VERSION "HNNBNNNYNNNNNNNNNNNNNNNNNNNNNNNNNNNNNNNNNN/4/%%%/4/'%**4NNN///"

NS_ :

BS_:

BU_: Allrad_Haldex AreaView_MQB BAP_Tester Bremse_ABS_MK100 Bremse_ESP_EPB_EBC460Vi Bremse_ESP_EPB_MK100 Bremse_ESP_MK100 Daempfer Gateway_MQB Lenkhilfe_EPS PDC PDC_PLA

BO_ 795 ESP_24: 8 Bremse_ABS_MK100
 SG_ ESP_24_CRC : 0|8@1+ (1,0) [0|255] ""  Gateway_MQB,Lenkhilfe_EPS
 SG_ ESP_24_BZ : 8|4@1+ (1,0) [0|15] ""  Gateway_MQB,Lenkhilfe_EPS
 SG_ ESP_Lampe : 12|1@1+ (1.0,0.0) [0.0|1] ""  AreaView_MQB,Gateway_MQB,Lenkhilfe_EPS,PDC,PDC_PLA
 SG_ ABS_Lampe : 13|1@1+ (1.0,0.0) [0.0|1] ""  Gateway_MQB,Lenkhilfe_EPS
 SG_ BK_Lampe_02 : 14|2@1+ (1.0,0.0) [0.0|3] ""  Gateway_MQB
 SG_ TC_Lampe : 16|1@1+ (1.0,0.0) [0.0|1] ""  Gateway_MQB
 SG_ ESP_m_Raddrehz : 17|15@1+ (0.002,0) [0.000|65.278] "Unit_Hertz"  Gateway_MQB
 SG_ ESP_Textanzeigen_03 : 32|5@1+ (1.0,0.0) [0.0|31] ""  Gateway_MQB
 SG_ ESP_Meldungen : 37|3@1+ (1.0,0.0) [0.0|7] ""  Gateway_MQB
 SG_ ESP_Wegimp_VA : 40|11@1+ (1,0) [0|2047] ""  AreaView_MQB,Gateway_MQB
 SG_ ESP_Fehlerstatus_Wegimp : 51|1@1+ (1.0,0.0) [0.0|1] ""  AreaView_MQB,Gateway_MQB
 SG_ ESP_Wegimp_Ueberlauf : 52|1@1+ (1.0,0.0) [0.0|1] ""  AreaView_MQB,Gateway_MQB
 SG_ ESP_QBit_Wegimp_VA : 53|1@1+ (1.0,0.0) [0.0|1] ""  AreaView_MQB,Gateway_MQB
 SG_ ESP_HDC_FktLampe : 54|1@1+ (1.0,0.0) [0.0|1] ""  Gateway_MQB
 SG_ ESP_Off_Lampe : 55|1@1+ (1.0,0.0) [0.0|1] ""  Gateway_MQB,Lenkhilfe_EPS
 SG_ ESP_HDC_Regelgeschw : 56|7@1+ (0.32,0) [0.32|39.68] "Unit_KiloMeterPerHour"  Gateway_MQB
 SG_ ESP_BKV_Warnung : 63|1@1+ (1.0,0.0) [0.0|1] ""  Gateway_MQB

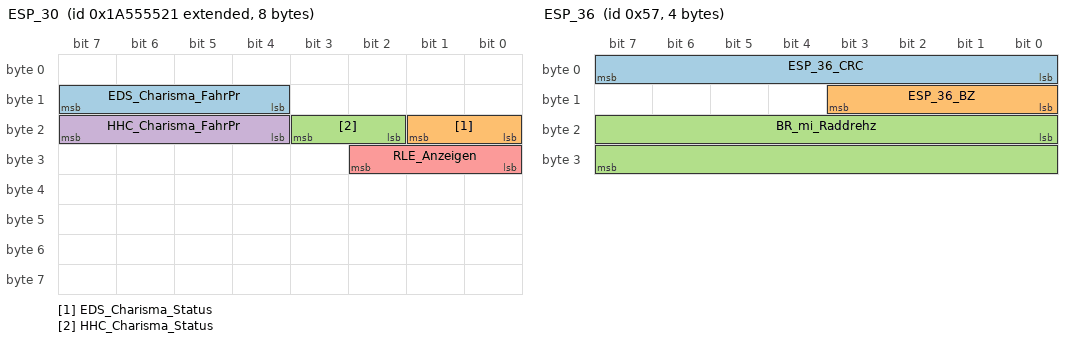
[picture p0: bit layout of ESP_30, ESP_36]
BO_ 2589283617 ESP_30: 8 Bremse_ESP_EPB_MK100
 SG_ EDS_Charisma_FahrPr : 12|4@1+ (1.0,0.0) [0.0|15] ""  Gateway_MQB
 SG_ EDS_Charisma_Status : 16|2@1+ (1.0,0.0) [0.0|3] ""  Gateway_MQB
 SG_ HHC_Charisma_Status : 18|2@1+ (1.0,0.0) [0.0|3] ""  Gateway_MQB
 SG_ HHC_Charisma_FahrPr : 20|4@1+ (1.0,0.0) [0.0|15] ""  Gateway_MQB
 SG_ RLE_Anzeigen : 24|3@1+ (1.0,0.0) [0.0|7] ""  Gateway_MQB

BO_ 427 ESP_33: 8 Bremse_ESP_EPB_EBC460Vi
 SG_ ESP_33_CRC : 0|8@1+ (1,0) [0|255] ""  Gateway_MQB,PDC
 SG_ ESP_33_BZ : 8|4@1+ (1,0) [0|15] ""  Gateway_MQB,PDC
 SG_ ESC_AHW_aktiv : 12|3@1+ (1.0,0.0) [0.0|7] ""  Gateway_MQB,PDC,PDC_PLA
 SG_ ESC_AHW_nicht_verfuegbar : 15|1@1+ (1.0,0.0) [0.0|1] ""  Gateway_MQB,PDC,PDC_PLA
 SG_ ESC_ANB_CM_aktiv : 16|2@1+ (1.0,0.0) [0.0|3] ""  Gateway_MQB
 SG_ ESC_ANB_CM_nicht_verfuegbar : 18|1@1+ (1.0,0.0) [0.0|1] ""  Gateway_MQB
 SG_ ESC_Warnruck_aktiv : 19|4@1+ (1.0,0.0) [0.0|15] ""  Gateway_MQB
 SG_ ESC_Warnruck_nicht_verfuegbar : 23|1@1+ (1.0,0.0) [0.0|1] ""  Gateway_MQB
 SG_ ESC_Prefill_aktiv : 24|1@1+ (1.0,0.0) [0.0|1] ""  Gateway_MQB
 SG_ ESC_Prefill_nicht_verfuegbar : 25|1@1+ (1.0,0.0) [0.0|1] ""  Gateway_MQB
 SG_ ESC_HBA_aktiv : 26|1@1+ (1.0,0.0) [0.0|1] ""  Gateway_MQB
 SG_ ESC_HBA_nicht_verfuegbar : 27|1@1+ (1.0,0.0) [0.0|1] ""  Gateway_MQB
 SG_ ESC_TSK_SRBM_Anf : 28|1@1+ (1.0,0.0) [0.0|1] ""  Gateway_MQB
 SG_ ESC_TSK_SRBM_nicht_verfuegbar : 29|1@1+ (1.0,0.0) [0.0|1] ""  Gateway_MQB
 SG_ ESC_Verz_Reg_aktiv : 30|4@1+ (1.0,0.0) [0.0|15] ""  Gateway_MQB,PDC,PDC_PLA
 SG_ ESC_Verz_Reg_nicht_verfuegbar : 34|1@1+ (1.0,0.0) [0.0|1] ""  Gateway_MQB,PDC,PDC_PLA
 SG_ ESC_Verz_Reg_TB_nicht_verfuegbar : 35|1@1+ (1.0,0.0) [0.0|1] ""  Gateway_MQB
 SG_ ESC_Verz_Reg_ZB_nicht_verfuegbar : 36|1@1+ (1.0,0.0) [0.0|1] ""  Gateway_MQB
 SG_ ESC_Bremslicht_unplausibel : 37|1@1+ (1.0,0.0) [0.0|1] ""  Gateway_MQB
 SG_ ESC_Konsistenz_ACC : 38|1@1+ (1.0,0.0) [0.0|1] ""  Gateway_MQB
 SG_ ESC_Konsistenz_AWV : 39|1@1+ (1.0,0.0) [0.0|1] ""  Gateway_MQB
 SG_ ESC_Konsistenz_ARA : 40|1@1+ (1.0,0.0) [0.0|1] ""  Gateway_MQB
 SG_ ESC_Konsistenz_IPA : 41|1@1+ (1.0,0.0) [0.0|1] ""  Gateway_MQB,PDC,PDC_PLA
 SG_ ESC_Konsistenz_FCW : 42|1@1+ (1.0,0.0) [0.0|1] ""  Gateway_MQB
 SG_ ESC_Konsistenz_NV : 43|1@1+ (1.0,0.0) [0.0|1] ""  Gateway_MQB
 SG_ ESC_Konsistenz_RCTA : 44|1@1+ (1.0,0.0) [0.0|1] ""  Gateway_MQB
 SG_ ESC_Konsistenz_TSK : 45|1@1+ (1.0,0.0) [0.0|1] ""  Gateway_MQB
 SG_ ESC_Konsistenz_vFGS : 46|1@1+ (1.0,0.0) [0.0|1] ""  Gateway_MQB
 SG_ ESC_Konsistenz_STA : 47|1@1+ (1.0,0.0) [0.0|1] ""  Gateway_MQB
 SG_ ESC_Fahrer_Bremsdruck_bestimmend : 48|1@1+ (1.0,0.0) [0.0|1] ""  Gateway_MQB,PDC,PDC_PLA
 SG_ ESC_Konsistenz_EA : 49|1@1+ (1.0,0.0) [0.0|1] ""  Gateway_MQB
 SG_ ESC_Konsistenz_BFF : 50|1@1+ (1.0,0.0) [0.0|1] ""  Gateway_MQB,PDC,PDC_PLA
 SG_ ESC_Konsistenz_MKB : 51|1@1+ (1.0,0.0) [0.0|1] ""  Gateway_MQB
 SG_ ESC_Verz_ASIL_Verfuegbarkeit : 52|3@1+ (1.0,0.0) [0.0|7] ""  Gateway_MQB,PDC,PDC_PLA
 SG_ ESC_Pumpenanlauf_aktiv : 55|1@1+ (1.0,0.0) [0.0|1] ""  Gateway_MQB
 SG_ ESC_Konsistenz_AGW : 56|1@1+ (1.0,0.0) [0.0|1] ""  Gateway_MQB
 SG_ ESC_Konsistenz_KAS : 57|1@1+ (1.0,0.0) [0.0|1] ""  Gateway_MQB
 SG_ ESC_Konsistenz_PCF : 58|1@1+ (1.0,0.0) [0.0|1] ""  Gateway_MQB
 SG_ ESC_Konsistenz_FAS_VK : 59|1@1+ (1.0,0.0) [0.0|1] ""  Gateway_MQB
 SG_ ESC_Verz_Begrenzung : 60|1@1+ (1.0,0.0) [0.0|1] ""  Gateway_MQB
 SG_ ESC_Konsistenz_AWA : 61|1@1+ (1.0,0.0) [0.0|1] ""  Gateway_MQB

BO_ 87 ESP_36: 4 Bremse_ESP_EPB_MK100
 SG_ ESP_36_CRC : 0|8@1+ (1,0) [0|255] ""  Gateway_MQB
 SG_ ESP_36_BZ : 8|4@1+ (1,0) [0|15] ""  Gateway_MQB
 SG_ BR_mi_Raddrehz : 16|16@1+ (0.0005,0) [0.0000|32.7660] "Unit_Hertz"  Gateway_MQB

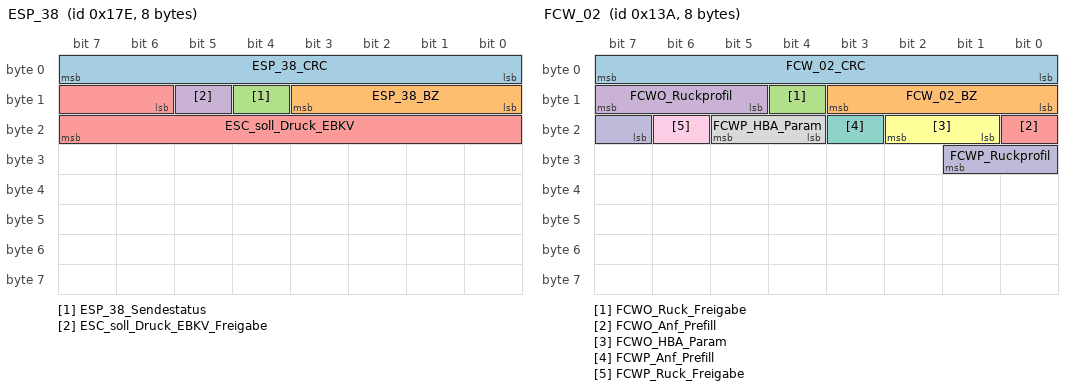
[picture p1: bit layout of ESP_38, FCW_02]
BO_ 382 ESP_38: 8 Bremse_ESP_EPB_MK100
 SG_ ESP_38_CRC : 0|8@1+ (1,0) [0|255] ""  Gateway_MQB
 SG_ ESP_38_BZ : 8|4@1+ (1,0) [0|15] ""  Gateway_MQB
 SG_ ESP_38_Sendestatus : 12|1@1+ (1.0,0.0) [0.0|1] ""  Gateway_MQB
 SG_ ESC_soll_Druck_EBKV_Freigabe : 13|1@1+ (1.0,0.0) [0.0|1] ""  Gateway_MQB
 SG_ ESC_soll_Druck_EBKV : 14|10@1+ (0.3,-30) [-30.0|276.6] "Unit_Bar"  Gateway_MQB

BO_ 264 Fahrwerk_01: 8 Daempfer
 SG_ Fahrwerk_01_CRC : 0|8@1+ (1,0) [0|255] ""  Bremse_ESP_EPB_EBC460Vi,Bremse_ESP_EPB_MK100,Bremse_ESP_MK100,Gateway_MQB
 SG_ Fahrwerk_01_BZ : 8|4@1+ (1,0) [0|15] ""  Bremse_ESP_EPB_EBC460Vi,Bremse_ESP_EPB_MK100,Bremse_ESP_MK100,Gateway_MQB
 SG_ FA_Hoehenwerte_kalibriert M  : 12|1@1+ (1.0,0.0) [0.0|1] ""  Gateway_MQB
 SG_ FA_ESP_Zuschaltung : 13|1@1+ (1.0,0.0) [0.0|1] ""  Bremse_ESP_EPB_EBC460Vi,Bremse_ESP_EPB_MK100,Bremse_ESP_MK100,Gateway_MQB
 SG_ FA_Hoehenwert_VL_00 m0  : 16|8@1+ (1,-127) [-127|126] "Unit_MilliMeter"  Gateway_MQB
 SG_ FA_Hoehenwert_VL_01 m1  : 16|8@1+ (0.4,0) [0.0|100.0] "Unit_PerCent"  Gateway_MQB
 SG_ FA_Hoehenwert_VR_00 m0  : 24|8@1+ (1,-127) [-127|126] "Unit_MilliMeter"  Gateway_MQB
 SG_ FA_Hoehenwert_VR_01 m1  : 24|8@1+ (0.4,0) [0.0|100.0] "Unit_PerCent"  Gateway_MQB
 SG_ FA_Hoehenwert_HL_00 m0  : 32|8@1+ (1,-127) [-127|126] "Unit_MilliMeter"  Gateway_MQB
 SG_ FA_Hoehenwert_HL_01 m1  : 32|8@1+ (0.4,0) [0.0|100.0] "Unit_PerCent"  Gateway_MQB
 SG_ FA_Hoehenwert_HR_00 m0  : 40|8@1+ (1,-127) [-127|126] "Unit_MilliMeter"  Gateway_MQB
 SG_ FA_Hoehenwert_HR_01 m1  : 40|8@1+ (0.4,0) [0.0|100.0] "Unit_PerCent"  Gateway_MQB

BO_ 314 FCW_02: 8 Gateway_MQB
 SG_ FCW_02_CRC : 0|8@1+ (1,0) [0|255] ""  Bremse_ESP_EPB_EBC460Vi,Bremse_ESP_EPB_MK100
 SG_ FCW_02_BZ : 8|4@1+ (1,0) [0|15] ""  Bremse_ESP_EPB_EBC460Vi,Bremse_ESP_EPB_MK100
 SG_ FCWO_Ruck_Freigabe : 12|1@1+ (1.0,0.0) [0.0|1] ""  Bremse_ESP_EPB_EBC460Vi,Bremse_ESP_EPB_MK100
 SG_ FCWO_Ruckprofil : 13|3@1+ (1.0,0.0) [0.0|7] ""  Bremse_ESP_EPB_EBC460Vi,Bremse_ESP_EPB_MK100
 SG_ FCWO_Anf_Prefill : 16|1@1+ (1.0,0.0) [0.0|1] ""  Bremse_ESP_EPB_EBC460Vi,Bremse_ESP_EPB_MK100
 SG_ FCWO_HBA_Param : 17|2@1+ (1.0,0.0) [0.0|3] ""  Bremse_ESP_EPB_EBC460Vi,Bremse_ESP_EPB_MK100
 SG_ FCWP_Anf_Prefill : 19|1@1+ (1.0,0.0) [0.0|1] ""  Bremse_ESP_EPB_EBC460Vi,Bremse_ESP_EPB_MK100
 SG_ FCWP_HBA_Param : 20|2@1+ (1.0,0.0) [0.0|3] ""  Bremse_ESP_EPB_EBC460Vi,Bremse_ESP_EPB_MK100
 SG_ FCWP_Ruck_Freigabe : 22|1@1+ (1.0,0.0) [0.0|1] ""  Bremse_ESP_EPB_EBC460Vi,Bremse_ESP_EPB_MK100
 SG_ FCWP_Ruckprofil : 23|3@1+ (1.0,0.0) [0.0|7] ""  Bremse_ESP_EPB_EBC460Vi,Bremse_ESP_EPB_MK100

BO_ 987 Gateway_72: 8 Gateway_MQB
 SG_ BCM_01_alt : 0|1@1+ (1.0,0.0) [0.0|1] ""  AreaView_MQB,Bremse_ABS_MK100,Bremse_ESP_EPB_EBC460Vi,Bremse_ESP_EPB_MK100,Bremse_ESP_MK100,PDC,PDC_PLA
 SG_ SMLS_01_alt : 1|1@1+ (1.0,0.0) [0.0|1] ""  AreaView_MQB,PDC,PDC_PLA
 SG_ ZV_02_alt : 2|1@1+ (1.0,0.0) [0.0|1] ""  AreaView_MQB,Bremse_ABS_MK100,Bremse_ESP_EPB_EBC460Vi,Bremse_ESP_EPB_MK100,Bremse_ESP_MK100,PDC,PDC_PLA
 SG_ Wischer_01_alt : 3|1@1+ (1.0,0.0) [0.0|1] ""  Bremse_ABS_MK100,Bremse_ESP_EPB_EBC460Vi,Bremse_ESP_EPB_MK100,Bremse_ESP_MK100
 SG_ Anhaenger_01_alt : 4|1@1+ (1.0,0.0) [0.0|1] ""  AreaView_MQB,Bremse_ESP_EPB_EBC460Vi,Bremse_ESP_EPB_MK100,Bremse_ESP_MK100,PDC,PDC_PLA
 SG_ Klima_Sensor_02_alt : 5|1@1+ (1.0,0.0) [0.0|1] ""  Lenkhilfe_EPS,PDC,PDC_PLA
 SG_ Verdeck_01_alt : 6|1@1+ (1.0,0.0) [0.0|1] ""  PDC,PDC_PLA
 SG_ Klima_11_alt : 7|1@1+ (1.0,0.0) [0.0|1] ""  Vector__XXX
 SG_ WFS_01_alt : 8|1@1+ (1.0,0.0) [0.0|1] ""  PDC,PDC_PLA
 SG_ Licht_Anf_01_alt : 9|1@1+ (1.0,0.0) [0.0|1] ""  AreaView_MQB,Lenkhilfe_EPS,PDC,PDC_PLA
 SG_ ZV_verriegelt_extern_soll : 10|1@1+ (1.0,0.0) [0.0|1] ""  Vector__XXX
 SG_ BH_Lichthupe : 11|1@1+ (1.0,0.0) [0.0|1] ""  Vector__XXX
 SG_ WFS_Klemmenfreigabe : 12|1@1+ (1.0,0.0) [0.0|1] ""  Vector__XXX
 SG_ ZV_Tankklappe_offen : 13|1@1+ (1.0,0.0) [0.0|1] ""  Vector__XXX
 SG_ AAG_Anhaenger_abgesteckt : 14|1@1+ (1.0,0.0) [0.0|1] ""  PDC,PDC_PLA
 SG_ BCM1_LDS_Stellung : 15|3@1+ (1.0,0.0) [0.0|7] ""  Vector__XXX
 SG_ VS_Verdeck_Anf : 18|1@1+ (1.0,0.0) [0.0|1] ""  PDC,PDC_PLA
 SG_ VS_VD_entriegelt : 19|1@1+ (1.0,0.0) [0.0|1] ""  PDC,PDC_PLA
 SG_ ZV_HFS_offen : 20|1@1+ (1.0,0.0) [0.0|1] ""  AreaView_MQB,PDC,PDC_PLA
 SG_ ZV_HBFS_offen : 21|1@1+ (1.0,0.0) [0.0|1] ""  AreaView_MQB,PDC,PDC_PLA
 SG_ VS_VD_offen_ver : 22|1@1+ (1.0,0.0) [0.0|1] ""  PDC,PDC_PLA
 SG_ VS_VD_zu_ver : 23|1@1+ (1.0,0.0) [0.0|1] ""  PDC,PDC_PLA
 SG_ ZV_BT_offen : 24|1@1+ (1.0,0.0) [0.0|1] ""  AreaView_MQB,PDC,PDC_PLA
 SG_ BCM1_Rueckfahrlicht_Schalter : 25|1@1+ (1.0,0.0) [0.0|1] ""  Bremse_ABS_MK100,Bremse_ESP_EPB_EBC460Vi,Bremse_ESP_EPB_MK100,Bremse_ESP_MK100,PDC,PDC_PLA
 SG_ ZV_FT_offen : 26|1@1+ (1.0,0.0) [0.0|1] ""  AreaView_MQB,Bremse_ABS_MK100,Bremse_ESP_EPB_EBC460Vi,Bremse_ESP_EPB_MK100,Bremse_ESP_MK100,PDC,PDC_PLA
 SG_ Wischer_vorne_aktiv : 27|1@1+ (1.0,0.0) [0.0|1] ""  Bremse_ABS_MK100,Bremse_ESP_EPB_EBC460Vi,Bremse_ESP_EPB_MK100,Bremse_ESP_MK100
 SG_ AAG_Anhaenger_erkannt : 28|1@1+ (1.0,0.0) [0.0|1] ""  AreaView_MQB,Bremse_ESP_EPB_EBC460Vi,Bremse_ESP_EPB_MK100,Bremse_ESP_MK100,PDC,PDC_PLA
 SG_ BCM1_MH_Schalter : 29|1@1+ (1.0,0.0) [0.0|1] ""  AreaView_MQB
 SG_ ZV_HD_offen : 30|1@1+ (1.0,0.0) [0.0|1] ""  AreaView_MQB,PDC,PDC_PLA
 SG_ Waschen_vorne_aktiv : 31|1@1+ (1.0,0.0) [0.0|1] ""  Vector__XXX
 SG_ KL_Thermomanagement : 32|2@1+ (1.0,0.0) [0.0|3] ""  Vector__XXX
 SG_ WFS_Schluessel_Fahrberecht : 34|4@1+ (1.0,0.0) [0.0|15] ""  PDC,PDC_PLA
 SG_ BCM_Rueckfahrlicht_Anf : 38|1@1+ (1.0,0.0) [0.0|1] ""  AreaView_MQB,Lenkhilfe_EPS,PDC,PDC_PLA
 SG_ WWSs_01_alt : 39|1@1+ (1.0,0.0) [0.0|1] ""  Bremse_ABS_MK100,Bremse_ESP_EPB_EBC460Vi,Bremse_ESP_EPB_MK100,Bremse_ESP_MK100
 SG_ BCM_Tankklappensteller_Fehler : 40|1@1+ (1.0,0.0) [0.0|1] ""  Vector__XXX
 SG_ AAG_LED_aktiv : 41|1@1+ (1.0,0.0) [0.0|1] ""  PDC,PDC_PLA
 SG_ ZV_verriegelt_soll : 42|2@1+ (1.0,0.0) [0.0|3] ""  Vector__XXX
 SG_ ZV_Schluessel_Zugang : 44|4@1+ (1.0,0.0) [0.0|15] ""  Vector__XXX
 SG_ WFS_ID_Geb_autorisiert_in_Kl15 : 48|1@1+ (1.0,0.0) [0.0|1] ""  Vector__XXX
 SG_ BH_Fernlicht : 49|1@1+ (1.0,0.0) [0.0|1] ""  Vector__XXX
 SG_ BH_Blinker_li : 50|1@1+ (1.0,0.0) [0.0|1] ""  AreaView_MQB,PDC,PDC_PLA
 SG_ BH_Blinker_re : 51|1@1+ (1.0,0.0) [0.0|1] ""  AreaView_MQB,PDC,PDC_PLA
 SG_ BCM1_OBD_FStatus_ATemp : 52|4@1+ (1.0,0.0) [0.0|15] ""  Lenkhilfe_EPS
 SG_ BCM1_Aussen_Temp_ungef : 56|8@1+ (0.5,-50) [-50.0|76.0] "Unit_DegreCelsi"  Lenkhilfe_EPS,PDC,PDC_PLA

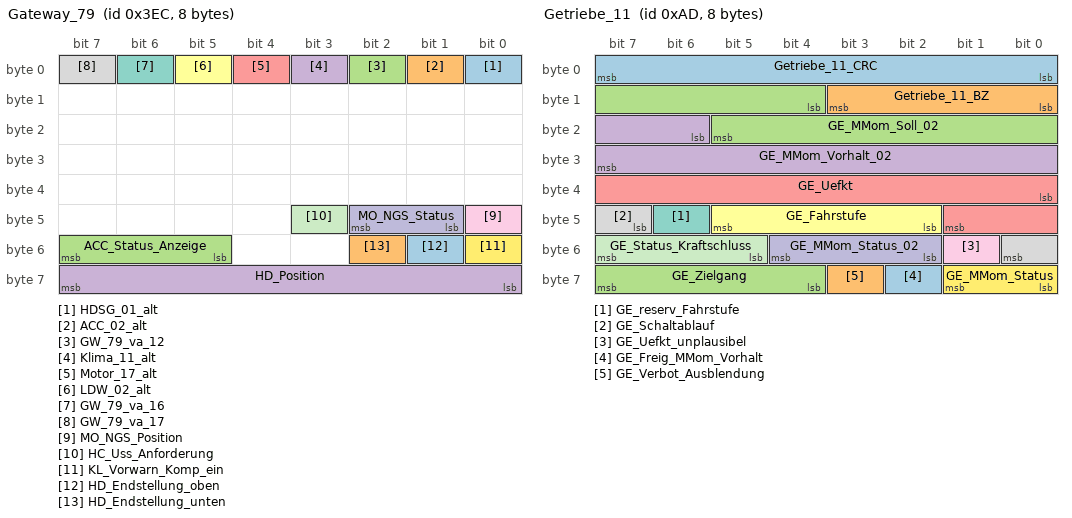
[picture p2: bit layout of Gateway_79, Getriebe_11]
BO_ 1004 Gateway_79: 8 Gateway_MQB
 SG_ HDSG_01_alt : 0|1@1+ (1.0,0.0) [0.0|1] ""  PDC,PDC_PLA
 SG_ ACC_02_alt : 1|1@1+ (1.0,0.0) [0.0|1] ""  PDC,PDC_PLA
 SG_ GW_79_va_12 : 2|1@1+ (1.0,0.0) [0.0|1] ""  Vector__XXX
 SG_ Klima_11_alt : 3|1@1+ (1.0,0.0) [0.0|1] ""  Bremse_ESP_EPB_EBC460Vi,Bremse_ESP_EPB_MK100
 SG_ Motor_17_alt : 4|1@1+ (1.0,0.0) [0.0|1] ""  Bremse_ESP_EPB_EBC460Vi,Bremse_ESP_EPB_MK100
 SG_ LDW_02_alt : 5|1@1+ (1.0,0.0) [0.0|1] ""  PDC_PLA
 SG_ GW_79_va_16 : 6|1@1+ (1.0,0.0) [0.0|1] ""  Vector__XXX
 SG_ GW_79_va_17 : 7|1@1+ (1.0,0.0) [0.0|1] ""  Vector__XXX
 SG_ MO_NGS_Position : 40|1@1+ (1.0,0.0) [0.0|1] ""  Bremse_ESP_EPB_EBC460Vi,Bremse_ESP_EPB_MK100
 SG_ MO_NGS_Status : 41|2@1+ (1.0,0.0) [0.0|3] ""  Bremse_ESP_EPB_EBC460Vi,Bremse_ESP_EPB_MK100
 SG_ HC_Uss_Anforderung : 43|1@1+ (1.0,0.0) [0.0|1] ""  PDC_PLA
 SG_ KL_Vorwarn_Komp_ein : 48|1@1+ (1.0,0.0) [0.0|1] ""  Bremse_ESP_EPB_EBC460Vi,Bremse_ESP_EPB_MK100
 SG_ HD_Endstellung_oben : 49|1@1+ (1.0,0.0) [0.0|1] ""  PDC,PDC_PLA
 SG_ HD_Endstellung_unten : 50|1@1+ (1.0,0.0) [0.0|1] ""  PDC,PDC_PLA
 SG_ ACC_Status_Anzeige : 53|3@1+ (1.0,0.0) [0.0|7] ""  PDC,PDC_PLA
 SG_ HD_Position : 56|8@1+ (1,0) [0|100] "Unit_PerCent"  PDC,PDC_PLA

BO_ 173 Getriebe_11: 8 Gateway_MQB
 SG_ Getriebe_11_CRC : 0|8@1+ (1,0) [0|255] ""  Bremse_ABS_MK100,Bremse_ESP_EPB_EBC460Vi,Bremse_ESP_EPB_MK100,Bremse_ESP_MK100
 SG_ Getriebe_11_BZ : 8|4@1+ (1,0) [0|15] ""  Bremse_ABS_MK100,Bremse_ESP_EPB_EBC460Vi,Bremse_ESP_EPB_MK100,Bremse_ESP_MK100
 SG_ GE_MMom_Soll_02 : 12|10@1+ (1,-509) [-509|509] ""  Vector__XXX
 SG_ GE_MMom_Vorhalt_02 : 22|10@1+ (1,-509) [-509|509] ""  Vector__XXX
 SG_ GE_Uefkt : 32|10@1+ (0.1,0) [0.0|102.2] ""  Bremse_ABS_MK100,Bremse_ESP_EPB_EBC460Vi,Bremse_ESP_EPB_MK100,Bremse_ESP_MK100
 SG_ GE_Fahrstufe : 42|4@1+ (1.0,0.0) [0.0|15] ""  AreaView_MQB,Bremse_ABS_MK100,Bremse_ESP_EPB_EBC460Vi,Bremse_ESP_EPB_MK100,Bremse_ESP_MK100,PDC,PDC_PLA
 SG_ GE_reserv_Fahrstufe : 46|1@1+ (1,0) [0|1] ""  Vector__XXX
 SG_ GE_Schaltablauf : 47|2@1+ (1.0,0.0) [0.0|3] ""  Bremse_ABS_MK100,Bremse_ESP_EPB_EBC460Vi,Bremse_ESP_EPB_MK100,Bremse_ESP_MK100
 SG_ GE_Uefkt_unplausibel : 49|1@1+ (1.0,0.0) [0.0|1] ""  Vector__XXX
 SG_ GE_MMom_Status_02 : 50|3@1+ (1.0,0.0) [0.0|7] ""  Vector__XXX
 SG_ GE_Status_Kraftschluss : 53|3@1+ (1.0,0.0) [0.0|7] ""  Vector__XXX
 SG_ GE_MMom_Status : 56|2@1+ (1.0,0.0) [0.0|3] ""  Vector__XXX
 SG_ GE_Freig_MMom_Vorhalt : 58|1@1+ (1.0,0.0) [0.0|1] ""  Vector__XXX
 SG_ GE_Verbot_Ausblendung : 59|1@1+ (1.0,0.0) [0.0|1] ""  Vector__XXX
 SG_ GE_Zielgang : 60|4@1+ (1.0,0.0) [0.0|15] ""  Allrad_Haldex,Bremse_ABS_MK100,Bremse_ESP_EPB_EBC460Vi,Bremse_ESP_EPB_MK100,Bremse_ESP_MK100

BO_ 968 Getriebe_14: 8 Gateway_MQB
 SG_ GE_OBD_AbsperrVent : 12|4@1+ (1.0,0.0) [0.0|15] ""  Vector__XXX
 SG_ GE_amax_moeglich : 16|9@1+ (0.024,-2.016) [-2.016|10.224] "Unit_MeterPerSeconSquar"  Vector__XXX
 SG_ GE_Charisma_FahrPr : 25|4@1+ (1.0,0.0) [0.0|15] ""  Vector__XXX
 SG_ GE_Charisma_Status : 29|2@1+ (1.0,0.0) [0.0|3] ""  Vector__XXX
 SG_ GE_Freigabe_Verfallsinfo_WFS : 31|1@1+ (1.0,0.0) [0.0|1] ""  Vector__XXX
 SG_ GE_Verlustmoment : 32|8@1+ (1,0) [0|254] ""  Bremse_ESP_EPB_EBC460Vi,Bremse_ESP_EPB_MK100
 SG_ Freilauf_Charisma_FahrPr : 40|4@1+ (1.0,0.0) [0.0|15] ""  Vector__XXX
 SG_ Freilauf_Charisma_Status : 44|2@1+ (1.0,0.0) [0.0|3] ""  Vector__XXX
 SG_ GE_Freigabe_Info_WFS : 46|1@1+ (1.0,0.0) [0.0|1] ""  Vector__XXX
 SG_ GE_Sperr_Info_WFS : 47|1@1+ (1.0,0.0) [0.0|1] ""  Vector__XXX
 SG_ GE_Zustand_Kuppltemp : 48|2@1+ (1.0,0.0) [0.0|3] ""  Vector__XXX
 SG_ GE_Codierung_MSG : 50|1@1+ (1.0,0.0) [0.0|1] ""  Vector__XXX
 SG_ GE_LaunchControl : 51|1@1+ (1.0,0.0) [0.0|1] ""  Bremse_ESP_EPB_EBC460Vi,Bremse_ESP_EPB_MK100,Bremse_ESP_MK100
 SG_ GE_Heizwunsch : 52|2@1+ (1.0,0.0) [0.0|3] ""  Vector__XXX
 SG_ GE_OBD_Status : 54|1@1+ (1.0,0.0) [0.0|1] ""  Vector__XXX
 SG_ GE_LFR_Adaption : 55|1@1+ (1.0,0.0) [0.0|1] ""  Vector__XXX
 SG_ GE_Sumpftemperatur : 56|8@1+ (1,-58) [-58|196] "Unit_DegreCelsi"  Vector__XXX

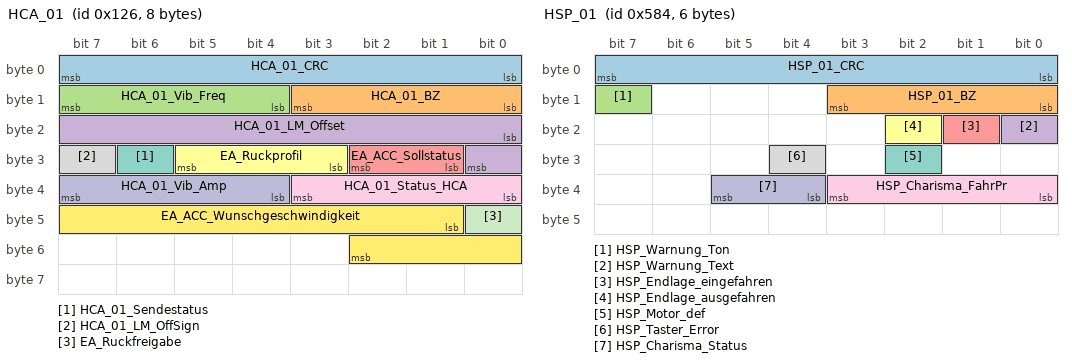
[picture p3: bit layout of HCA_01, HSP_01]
BO_ 294 HCA_01: 8 Gateway_MQB
 SG_ HCA_01_CRC : 0|8@1+ (1,0) [0|255] ""  Bremse_ESP_EPB_MK100,Bremse_ESP_MK100,Lenkhilfe_EPS
 SG_ HCA_01_BZ : 8|4@1+ (1,0) [0|15] ""  Bremse_ESP_EPB_MK100,Bremse_ESP_MK100,Lenkhilfe_EPS
 SG_ HCA_01_Vib_Freq : 12|4@1+ (1,15) [15|30] "Unit_Hertz"  Lenkhilfe_EPS
 SG_ HCA_01_LM_Offset : 16|9@1+ (0.01,0) [0.00|5.11] "Unit_NewtoMeter"  Lenkhilfe_EPS
 SG_ EA_ACC_Sollstatus : 25|2@1+ (1.0,0.0) [0.0|3] ""  Vector__XXX
 SG_ EA_Ruckprofil : 27|3@1+ (1.0,0.0) [0.0|7] ""  Bremse_ESP_EPB_MK100,Bremse_ESP_MK100
 SG_ HCA_01_Sendestatus : 30|1@1+ (1.0,0.0) [0.0|1] ""  Bremse_ESP_EPB_MK100,Bremse_ESP_MK100
 SG_ HCA_01_LM_OffSign : 31|1@1+ (1.0,0.0) [0.0|1] ""  Lenkhilfe_EPS
 SG_ HCA_01_Status_HCA : 32|4@1+ (1.0,0.0) [0.0|15] ""  Lenkhilfe_EPS
 SG_ HCA_01_Vib_Amp : 36|4@1+ (0.2,0) [0.0|3.0] "Unit_NewtoMeter"  Lenkhilfe_EPS
 SG_ EA_Ruckfreigabe : 40|1@1+ (1.0,0.0) [0.0|1] ""  Bremse_ESP_EPB_MK100,Bremse_ESP_MK100
 SG_ EA_ACC_Wunschgeschwindigkeit : 41|10@1+ (0.32,0) [0.00|327.04] "Unit_KiloMeterPerHour"  Vector__XXX

BO_ 1412 HSP_01: 6 Gateway_MQB
 SG_ HSP_01_CRC : 0|8@1+ (1,0) [0|255] ""  Vector__XXX
 SG_ HSP_01_BZ : 8|4@1+ (1,0) [0|15] ""  Vector__XXX
 SG_ HSP_Warnung_Ton : 15|1@1+ (1.0,0.0) [0.0|1] ""  Vector__XXX
 SG_ HSP_Warnung_Text : 16|1@1+ (1.0,0.0) [0.0|1] ""  Vector__XXX
 SG_ HSP_Endlage_eingefahren : 17|1@1+ (1.0,0.0) [0.0|1] ""  Vector__XXX
 SG_ HSP_Endlage_ausgefahren : 18|1@1+ (1.0,0.0) [0.0|1] ""  Vector__XXX
 SG_ HSP_Motor_def : 26|1@1+ (1.0,0.0) [0.0|1] ""  Vector__XXX
 SG_ HSP_Taster_Error : 28|1@1+ (1.0,0.0) [0.0|1] ""  Vector__XXX
 SG_ HSP_Charisma_FahrPr : 32|4@1+ (1.0,0.0) [0.0|15] ""  Vector__XXX
 SG_ HSP_Charisma_Status : 36|2@1+ (1.0,0.0) [0.0|3] ""  Vector__XXX

BO_ 1811 ISO_ABS_Req: 8 Gateway_MQB
 SG_ ISO_ABS_Req_Data : 0|64@1+ (1.0,0.0) [0.0|18446744073709551615] ""  Bremse_ABS_MK100,Bremse_ESP_EPB_EBC460Vi,Bremse_ESP_EPB_MK100,Bremse_ESP_MK100

BO_ 1917 ISO_ABS_Resp: 8 Bremse_ABS_MK100
 SG_ ISO_ABS_Resp_Data : 0|64@1+ (1.0,0.0) [0.0|18446744073709551615] ""  Gateway_MQB

BO_ 1807 ISO_Allrad_Req: 8 Gateway_MQB
 SG_ ISO_Allrad_Req_Data : 0|64@1+ (1.0,0.0) [0.0|18446744073709551615] ""  Allrad_Haldex

BO_ 1913 ISO_Allrad_Resp: 8 Allrad_Haldex
 SG_ ISO_Allrad_Resp_Data : 0|64@1+ (1.0,0.0) [0.0|18446744073709551615] ""  Gateway_MQB

BO_ 1906 ISO_Daempfer_Req: 8 Gateway_MQB
 SG_ ISO_Daempfer_Req_Data : 0|64@1+ (1.0,0.0) [0.0|18446744073709551615] ""  Daempfer

BO_ 2012 ISO_Daempfer_Resp: 8 Daempfer
 SG_ ISO_Daempfer_Resp_Data : 0|64@1+ (1.0,0.0) [0.0|18446744073709551615] ""  Gateway_MQB

BO_ 1802 ISO_EPH_Req: 8 Gateway_MQB
 SG_ ISO_EPH_Req_Data : 0|64@1+ (1.0,0.0) [0.0|18446744073709551615] ""  PDC,PDC_PLA

BO_ 1908 ISO_EPH_Resp: 8 PDC
 SG_ ISO_EPH_Resp_Data : 0|64@1+ (1.0,0.0) [0.0|18446744073709551615] ""  Gateway_MQB

BO_ 1793 ISO_Funktionaler_Req_01: 8 Gateway_MQB
 SG_ ISO_01_Req_Data : 0|64@1+ (1.0,0.0) [0.0|18446744073709551615] ""  Vector__XXX

BO_ 1794 ISO_Funktionaler_Req_02: 8 Gateway_MQB
 SG_ ISO_02_Req_Data : 0|64@1+ (1.0,0.0) [0.0|18446744073709551615] ""  Vector__XXX

BO_ 1796 ISO_Funktionaler_Req_04: 8 Gateway_MQB
 SG_ ISO_04_Req_Data : 0|64@1+ (1.0,0.0) [0.0|18446744073709551615] ""  Vector__XXX

BO_ 1797 ISO_Funktionaler_Req_05: 8 Gateway_MQB
 SG_ ISO_05_Req_Data : 0|64@1+ (1.0,0.0) [0.0|18446744073709551615] ""  Vector__XXX

BO_ 1798 ISO_Funktionaler_Req_06: 8 Gateway_MQB
 SG_ ISO_06_Req_Data : 0|64@1+ (1.0,0.0) [0.0|18446744073709551615] ""  Vector__XXX

BO_ 1799 ISO_Funktionaler_Req_07: 8 Gateway_MQB
 SG_ ISO_07_Req_Data : 0|64@1+ (1.0,0.0) [0.0|18446744073709551615] ""  Vector__XXX

BO_ 1800 ISO_Funktionaler_Req_08: 8 Gateway_MQB
 SG_ ISO_08_Req_Data : 0|64@1+ (1.0,0.0) [0.0|18446744073709551615] ""  Vector__XXX

BO_ 1801 ISO_Funktionaler_Req_09: 8 Gateway_MQB
 SG_ ISO_09_Req_Data : 0|64@1+ (1.0,0.0) [0.0|18446744073709551615] ""  Vector__XXX

BO_ 1795 ISO_Funktionaler_Req_Abgas: 8 Gateway_MQB
 SG_ ISO_Funktionaler_Req_Abgas : 0|64@1+ (1.0,0.0) [0.0|18446744073709551615] ""  Bremse_ESP_EPB_MK100

BO_ 1792 ISO_Funktionaler_Req_All: 8 Gateway_MQB
 SG_ ISO_ALL_01_Req_Data : 0|64@1+ (1.0,0.0) [0.0|18446744073709551615] ""  Allrad_Haldex,AreaView_MQB,Bremse_ABS_MK100,Bremse_ESP_EPB_EBC460Vi,Bremse_ESP_EPB_MK100,Bremse_ESP_MK100,Daempfer,Lenkhilfe_EPS,PDC,PDC_PLA

BO_ 2015 ISO_Funktionaler_Req_OBD: 8 Gateway_MQB
 SG_ ISO_OBD_Funktionaler_Req_Data : 0|64@1+ (1.0,0.0) [0.0|18446744073709551615] ""  Bremse_ESP_EPB_MK100

BO_ 1810 ISO_Lenkhilfe_Req: 8 Gateway_MQB
 SG_ ISO_Lenkhilfe_Req_Data : 0|64@1+ (1.0,0.0) [0.0|18446744073709551615] ""  Lenkhilfe_EPS

BO_ 1916 ISO_Lenkhilfe_Resp: 8 Lenkhilfe_EPS
 SG_ ISO_Lenkhilfe_Resp_Data : 0|64@1+ (1.0,0.0) [0.0|18446744073709551615] ""  Gateway_MQB

BO_ 2020 ISO_OBD_03_Req: 8 Gateway_MQB
 SG_ ISO_OBD_03_Req_Data : 0|64@1+ (1.0,0.0) [0.0|18446744073709551615] ""  Bremse_ESP_EPB_MK100

BO_ 2028 ISO_OBD_03_Resp: 8 Bremse_ESP_EPB_MK100
 SG_ ISO_OBD_03_Resp_Data : 0|64@1+ (1.0,0.0) [0.0|18446744073709551615] ""  Gateway_MQB

BO_ 1897 ISO_Rearview_Req: 8 Gateway_MQB
 SG_ ISO_Rearview_Req_Data : 0|64@1+ (1.0,0.0) [0.0|18446744073709551615] ""  AreaView_MQB

BO_ 2003 ISO_Rearview_Resp: 8 AreaView_MQB
 SG_ ISO_Rearview_Resp_Data : 0|64@1+ (1.0,0.0) [0.0|18446744073709551615] ""  Gateway_MQB

BO_ 960 Klemmen_Status_01: 4 Gateway_MQB
 SG_ Klemmen_Status_01_CRC : 0|8@1+ (1,0) [0|255] ""  Bremse_ESP_EPB_EBC460Vi,Bremse_ESP_EPB_MK100,Lenkhilfe_EPS
 SG_ Klemmen_Status_01_BZ : 8|4@1+ (1,0) [0|15] ""  Bremse_ESP_EPB_EBC460Vi,Bremse_ESP_EPB_MK100,Lenkhilfe_EPS
 SG_ RSt_Fahrerhinweise : 12|4@1+ (1.0,0.0) [0.0|15] ""  Vector__XXX
 SG_ ZAS_Kl_S : 16|1@1+ (1.0,0.0) [0.0|1] ""  Bremse_ESP_EPB_EBC460Vi,Bremse_ESP_EPB_MK100,Lenkhilfe_EPS
 SG_ ZAS_Kl_15 : 17|1@1+ (1.0,0.0) [0.0|1] ""  AreaView_MQB,Bremse_ESP_EPB_EBC460Vi,Bremse_ESP_EPB_MK100,Lenkhilfe_EPS,PDC,PDC_PLA
 SG_ ZAS_Kl_X : 18|1@1+ (1.0,0.0) [0.0|1] ""  Vector__XXX
 SG_ ZAS_Kl_50_Startanforderung : 19|1@1+ (1.0,0.0) [0.0|1] ""  Vector__XXX
 SG_ BCM_Remotestart_Betrieb : 20|1@1+ (1.0,0.0) [0.0|1] ""  Vector__XXX
 SG_ ZAS_Kl_Infotainment : 21|1@1+ (1.0,0.0) [0.0|1] ""  Vector__XXX
 SG_ BCM_Remotestart_KL15_Anf : 22|1@1+ (1.0,0.0) [0.0|1] ""  Vector__XXX
 SG_ BCM_Remotestart_MO_Start : 23|1@1+ (1.0,0.0) [0.0|1] ""  Vector__XXX
 SG_ KST_Warn_P1_ZST_def : 24|1@1+ (1.0,0.0) [0.0|1] ""  Vector__XXX
 SG_ KST_Warn_P2_ZST_def : 25|1@1+ (1.0,0.0) [0.0|1] ""  Vector__XXX
 SG_ KST_Fahrerhinweis_1 : 26|1@1+ (1.0,0.0) [0.0|1] ""  Vector__XXX
 SG_ KST_Fahrerhinweis_2 : 27|1@1+ (1.0,0.0) [0.0|1] ""  Vector__XXX
 SG_ BCM_Ausparken_Betrieb : 28|1@1+ (1.0,0.0) [0.0|1] ""  Vector__XXX
 SG_ KST_Fahrerhinweis_4 : 29|1@1+ (1.0,0.0) [0.0|1] ""  Vector__XXX
 SG_ KST_Fahrerhinweis_5 : 30|1@1+ (1.0,0.0) [0.0|1] ""  Vector__XXX
 SG_ KST_Fahrerhinweis_6 : 31|1@1+ (1.0,0.0) [0.0|1] ""  Vector__XXX

BO_ 1640 Klima_12: 8 Gateway_MQB
 SG_ KL_LRH_Taster : 0|1@1+ (1.0,0.0) [0.0|1] ""  Vector__XXX
 SG_ KL_LRH_Stufe : 1|2@1+ (1.0,0.0) [0.0|3] ""  Vector__XXX
 SG_ HSH_Taster : 3|2@1+ (1.0,0.0) [0.0|3] ""  Vector__XXX
 SG_ FSH_Taster : 5|1@1+ (1.0,0.0) [0.0|1] ""  Vector__XXX
 SG_ KL_Zuheizer_Freigabe : 6|1@1+ (1.0,0.0) [0.0|1] ""  Vector__XXX
 SG_ KL_Beschlagsgefahr : 7|1@1+ (1.0,0.0) [0.0|1] ""  Vector__XXX
 SG_ KL_SIH_Soll_li : 8|3@1+ (1.0,0.0) [0.0|7] ""  Vector__XXX
 SG_ KL_SIH_Soll_re : 11|3@1+ (1.0,0.0) [0.0|7] ""  Vector__XXX
 SG_ KRH_Soll_li : 14|2@1+ (1.0,0.0) [0.0|3] ""  Vector__XXX
 SG_ KL_SIL_Soll_li : 16|3@1+ (1.0,0.0) [0.0|7] ""  Vector__XXX
 SG_ KL_SIL_Soll_re : 19|3@1+ (1.0,0.0) [0.0|7] ""  Vector__XXX
 SG_ KRH_Soll_re : 22|2@1+ (1.0,0.0) [0.0|3] ""  Vector__XXX
 SG_ KL_Geblspng_Soll : 24|8@1+ (0.05,1.45) [1.50|14.00] "Unit_Volt"  PDC,PDC_PLA
 SG_ KL_Geblspng_Fond_Soll : 32|8@1+ (0.05,1.45) [1.50|14.00] "Unit_Volt"  PDC,PDC_PLA
 SG_ KL_I_Geblaese : 40|8@1+ (0.25,0) [0.00|63.50] "Unit_Amper"  Vector__XXX
 SG_ KL_Kompressorstrom_soll : 48|10@1+ (1,0) [0|1021] ""  Vector__XXX
 SG_ KL_Umluftklappe_Status : 58|4@1+ (1.0,0.0) [0.0|15] ""  Vector__XXX
 SG_ KL_PTC_Verbauinfo : 62|2@1+ (1.0,0.0) [0.0|3] ""  Vector__XXX

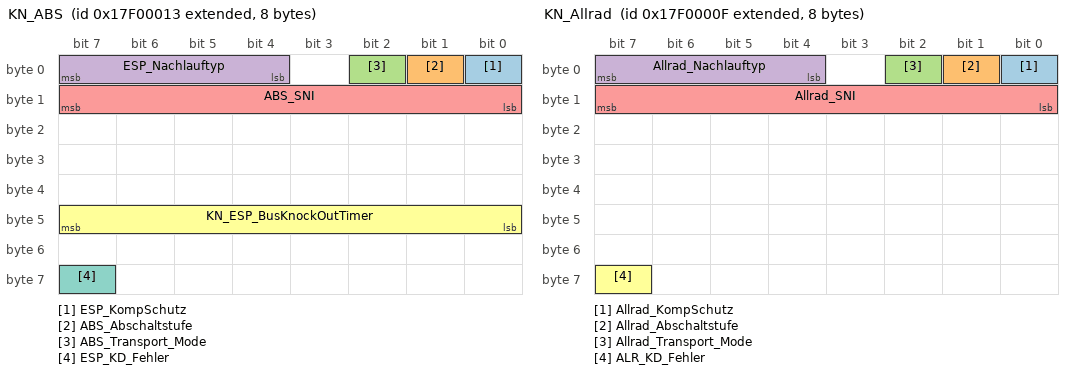
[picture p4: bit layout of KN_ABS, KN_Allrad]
BO_ 2549088275 KN_ABS: 8 Bremse_ABS_MK100
 SG_ ESP_KompSchutz : 0|1@1+ (1.0,0.0) [0.0|1] ""  Vector__XXX
 SG_ ABS_Abschaltstufe : 1|1@1+ (1.0,0.0) [0.0|1] ""  Vector__XXX
 SG_ ABS_Transport_Mode : 2|1@1+ (1.0,0.0) [0.0|1] ""  Vector__XXX
 SG_ ESP_Nachlauftyp : 4|4@1+ (1.0,0.0) [0.0|15] ""  Gateway_MQB
 SG_ ABS_SNI : 8|8@1+ (1.0,0.0) [0.0|255] ""  Vector__XXX
 SG_ KN_ESP_BusKnockOutTimer : 40|8@1+ (1,0) [0|254] ""  Vector__XXX
 SG_ ESP_KD_Fehler : 63|1@1+ (1.0,0.0) [0.0|1] ""  Gateway_MQB

BO_ 2549088271 KN_Allrad: 8 Allrad_Haldex
 SG_ Allrad_KompSchutz : 0|1@1+ (1.0,0.0) [0.0|1] ""  Vector__XXX
 SG_ Allrad_Abschaltstufe : 1|1@1+ (1.0,0.0) [0.0|1] ""  Vector__XXX
 SG_ Allrad_Transport_Mode : 2|1@1+ (1.0,0.0) [0.0|1] ""  Vector__XXX
 SG_ Allrad_Nachlauftyp : 4|4@1+ (1.0,0.0) [0.0|15] ""  Gateway_MQB
 SG_ Allrad_SNI : 8|8@1+ (1.0,0.0) [0.0|255] ""  Vector__XXX
 SG_ ALR_KD_Fehler : 63|1@1+ (1.0,0.0) [0.0|1] ""  Gateway_MQB

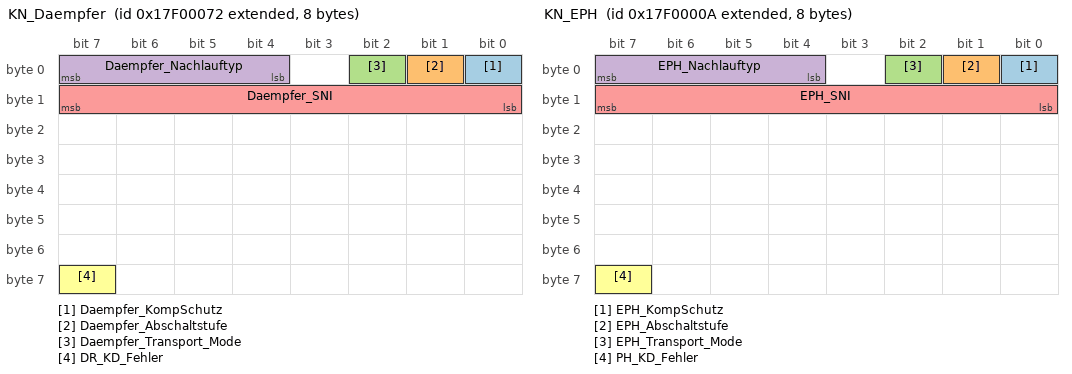
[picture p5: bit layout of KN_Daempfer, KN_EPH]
BO_ 2549088370 KN_Daempfer: 8 Daempfer
 SG_ Daempfer_KompSchutz : 0|1@1+ (1.0,0.0) [0.0|1] ""  Vector__XXX
 SG_ Daempfer_Abschaltstufe : 1|1@1+ (1.0,0.0) [0.0|1] ""  Vector__XXX
 SG_ Daempfer_Transport_Mode : 2|1@1+ (1.0,0.0) [0.0|1] ""  Vector__XXX
 SG_ Daempfer_Nachlauftyp : 4|4@1+ (1.0,0.0) [0.0|15] ""  Gateway_MQB
 SG_ Daempfer_SNI : 8|8@1+ (1.0,0.0) [0.0|255] ""  Vector__XXX
 SG_ DR_KD_Fehler : 63|1@1+ (1.0,0.0) [0.0|1] ""  Gateway_MQB

BO_ 2549088266 KN_EPH: 8 PDC
 SG_ EPH_KompSchutz : 0|1@1+ (1.0,0.0) [0.0|1] ""  Vector__XXX
 SG_ EPH_Abschaltstufe : 1|1@1+ (1.0,0.0) [0.0|1] ""  Vector__XXX
 SG_ EPH_Transport_Mode : 2|1@1+ (1.0,0.0) [0.0|1] ""  Vector__XXX
 SG_ EPH_Nachlauftyp : 4|4@1+ (1.0,0.0) [0.0|15] ""  Gateway_MQB
 SG_ EPH_SNI : 8|8@1+ (1.0,0.0) [0.0|255] ""  Vector__XXX
 SG_ PH_KD_Fehler : 63|1@1+ (1.0,0.0) [0.0|1] ""  Gateway_MQB

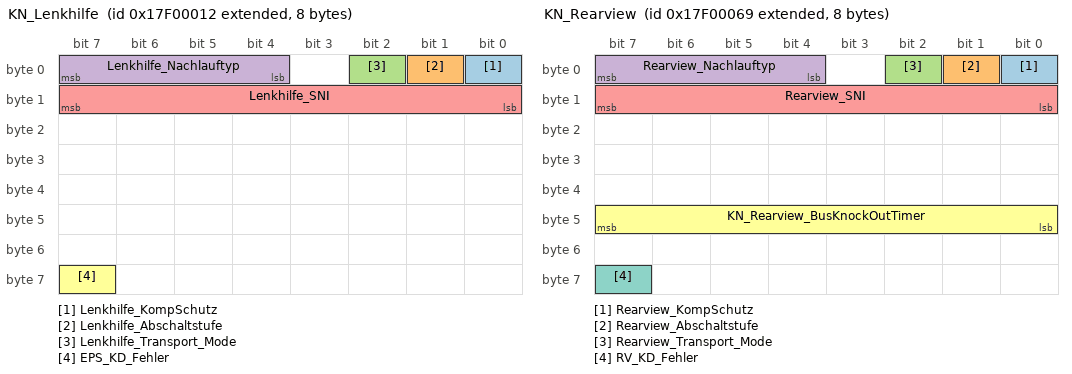
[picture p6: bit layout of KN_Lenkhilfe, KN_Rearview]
BO_ 2549088274 KN_Lenkhilfe: 8 Lenkhilfe_EPS
 SG_ Lenkhilfe_KompSchutz : 0|1@1+ (1.0,0.0) [0.0|1] ""  Vector__XXX
 SG_ Lenkhilfe_Abschaltstufe : 1|1@1+ (1.0,0.0) [0.0|1] ""  Vector__XXX
 SG_ Lenkhilfe_Transport_Mode : 2|1@1+ (1.0,0.0) [0.0|1] ""  Vector__XXX
 SG_ Lenkhilfe_Nachlauftyp : 4|4@1+ (1.0,0.0) [0.0|15] ""  Gateway_MQB
 SG_ Lenkhilfe_SNI : 8|8@1+ (1.0,0.0) [0.0|255] ""  Vector__XXX
 SG_ EPS_KD_Fehler : 63|1@1+ (1.0,0.0) [0.0|1] ""  Gateway_MQB

BO_ 2549088361 KN_Rearview: 8 AreaView_MQB
 SG_ Rearview_KompSchutz : 0|1@1+ (1.0,0.0) [0.0|1] ""  Vector__XXX
 SG_ Rearview_Abschaltstufe : 1|1@1+ (1.0,0.0) [0.0|1] ""  Vector__XXX
 SG_ Rearview_Transport_Mode : 2|1@1+ (1.0,0.0) [0.0|1] ""  Vector__XXX
 SG_ Rearview_Nachlauftyp : 4|4@1+ (1.0,0.0) [0.0|15] ""  Gateway_MQB
 SG_ Rearview_SNI : 8|8@1+ (1.0,0.0) [0.0|255] ""  Vector__XXX
 SG_ KN_Rearview_BusKnockOutTimer : 40|8@1+ (1,0) [0|254] ""  Vector__XXX
 SG_ RV_KD_Fehler : 63|1@1+ (1.0,0.0) [0.0|1] ""  Gateway_MQB

BO_TX_BU_ 795 :Bremse_ABS_MK100,Bremse_ESP_EPB_EBC460Vi,Bremse_ESP_EPB_MK100,Bremse_ESP_MK100;
BO_TX_BU_ 2589283617 :Bremse_ESP_EPB_MK100,Bremse_ESP_MK100;
BO_TX_BU_ 427 :Bremse_ESP_EPB_EBC460Vi,Bremse_ESP_EPB_MK100,Bremse_ESP_MK100;
BO_TX_BU_ 382 :Bremse_ESP_EPB_MK100,Bremse_ESP_MK100;
BO_TX_BU_ 1917 :Bremse_ABS_MK100,Bremse_ESP_EPB_EBC460Vi,Bremse_ESP_EPB_MK100,Bremse_ESP_MK100;
BO_TX_BU_ 1908 :PDC,PDC_PLA;
BO_TX_BU_ 2549088275 :Bremse_ABS_MK100,Bremse_ESP_EPB_EBC460Vi,Bremse_ESP_EPB_MK100,Bremse_ESP_MK100;
BO_TX_BU_ 2549088266 :PDC,PDC_PLA;
CM_ BO_ 795 "neu für MQB wg. Absicherung
Entstanden aus ESP_04";
CM_ BO_ 87 "Reserviert für Sondermaßnahme VW370/7";
CM_ BO_ 382 "reserviert für MQB (ESP->EBKV)";
CM_ BO_ 264 "ab MQB mit CRC-8";
CM_ BO_ 987 "Komfort -> Antrieb, Extended, Fahrwerk, Infotainment";
CM_ BO_ 1004 "Extended, Komfort  -> Fahrwerk";
CM_ BO_ 294 "für MQB verändertes Sendeverhalten
(nicht IL-kompatibel, da zwei Inaktiv-Werte im Signal HCA_01_Status_HCA)";
CM_ BO_ 960 "MQB";
CM_ BO_ 1640 "ab MQB IS-4";

CM_ SG_ 795 ABS_Lampe "Sicherheitswarnlampe

Weiterführende Informationen im Lastenheft spezifiziert und in der entsprechenden Fachabteilung zu erfragen.";
CM_ SG_ 795 BK_Lampe_02 "Sicherheitswarnlampe signalisiert EBV-Ausfall

MQB: wird auch bei HBV-Ausfall verwendet.

Weiterführende Informationen im Lastenheft spezifiziert und in der entsprechenden Fachabteilung zu erfragen.";
CM_ SG_ 795 ESP_24_CRC "Für MLB:
'Berechnung siehe Lastenheft 'Kommunikationsabsicherung für FlexRay und CAN''

Ab MQB und MLBevo:
'Berechnung siehe Lastenheft 'End-to-End Kommunikationsabsicherung''

Endwerte siehe Begleitdokument 'S-PDU Kennungsfolgen'";
CM_ SG_ 795 ESP_BKV_Warnung "ESP sendet im Hinweis- /Störungsfall an das Kombi Informationen zum Anzeigen (Text + Akustik)

Im MQB wird dieses Signal nicht unterstützt!
";
CM_ SG_ 795 ESP_Fehlerstatus_Wegimp "Weiterführende Informationen im Lastenheft spezifiziert und in der entsprechenden Fachabteilung zu erfragen.

MLB: Fehler wird gesetzt, wenn beide ESP-Drehzahlfühler an der Vorderachse defekt sind.

MQB: Fehler wird gesetzt, wenn beide Raddrehzahlfühl";
CM_ SG_ 795 ESP_HDC_FktLampe "Funktionslampe Bergabfahrassistent.
(Sender blinkt mit dem Bit 3,3Hz)";
CM_ SG_ 795 ESP_HDC_Regelgeschw "Verwendung/Bedienung nur im AU57x Allroad:
HDC-Geschwindigkeit
Dient der Anzeige der HDC-Geschwindigkeit und eines Bergabfahrsymbols im Kombi.
HDC-Standby wird gesetzt sobald der Fahrer den HDC-Taster aktiviert hat.
Bei HDC-Off oder während der Initia";
CM_ SG_ 795 ESP_Lampe "Zustand der Fahrdynamikregelungslampe (MLB: ASR und/oder ESP, MQB: nur ESP)

Weiterführende Informationen im Lastenheft spezifiziert und in der entsprechenden Fachabteilung zu erfragen.";
CM_ SG_ 795 ESP_m_Raddrehz "Radumdrehungen pro Sekunde sind Eingangsgröße für die Geschwindigkeitsberechnung im Kombi. Aus dieser Raddrehzahl und dem Radumfang wird die Fahrzeuggeschwindigkeit errechnet.

MLB: Exklusiver Empfänger ist das Kombiinstrument!
MQB: Bei Frontantrieb un";
CM_ SG_ 795 ESP_Meldungen "ESP sendet im Hinweis- /Störungsfall an das Kombi Informationen zum Anzeigen

Weiterführende Informationen im Lastenheft spezifiziert und in der entsprechenden Fachabteilung zu erfragen.
Ergänzender Hinweis:
1 = Autohold_Hinweis_1 (Anfahrassistent: nu";
CM_ SG_ 795 ESP_Off_Lampe "Bit zur Ansteuerung der separaten ESP-off-Lampe im Kombi (Gesetzesforderung USA)

MLB:
Verwendung/Bedienung ab D4";
CM_ SG_ 795 ESP_QBit_Wegimp_VA "Gesetzt bei Ersatzwert, Init oder Fehler.";
CM_ SG_ 795 ESP_Textanzeigen_03 "Textanzeigen der Fahrdynamikregelung im Kombiinstrument

Weiterführende Informationen im Lastenheft spezifiziert und in der entsprechenden Fachabteilung zu erfragen.

Der Signalwert 24 wird nur im BY736 verwendet.";
CM_ SG_ 795 ESP_Wegimp_Ueberlauf "Der Wegimpulszähler ist pro Zündungslauf mindestens einmal übergelaufen

Weiterführende Informationen im Lastenheft spezifiziert und in der entsprechenden Fachabteilung zu erfragen.";
CM_ SG_ 795 ESP_Wegimp_VA "Weiterführende Informationen im Lastenheft spezifiziert und in der entsprechenden Fachabteilung zu erfragen.

MLB: Die Wegimpulse Vorderachse sind die gemittelten Werte (reine mathematische Operation: Addition und Division durch zwei, keine Filterung) d";
CM_ SG_ 795 TC_Lampe "M-ABS Lampe (separate Lampe für M-ABS-Systeme Markt Brasilien)

Weiterführende Informationen im Lastenheft spezifiziert und in der entsprechenden Fachabteilung zu erfragen.";

CM_ SG_ 2589283617 EDS_Charisma_FahrPr "Aktuelles Fahrprogramm des Charisma-Teilnehmers Elektronische Differentialsperre EDS";
CM_ SG_ 2589283617 EDS_Charisma_Status "Systemstatus des Charismateilnehmers Elektronische Differentialsperre EDS";
CM_ SG_ 2589283617 HHC_Charisma_FahrPr "Aktuelles Fahrprogramm des Charisma-Teilnehmers Berganfahrassistent HHC";
CM_ SG_ 2589283617 HHC_Charisma_Status "Systemstatus des Charismateilnehmers Berganfahrassistent HHC";
CM_ SG_ 2589283617 RLE_Anzeigen "Anzeigen für die Radlöseerkennung";

CM_ SG_ 427 ESC_AHW_aktiv "Rueckmeldung Anhaltewegregelung aktiv
";
CM_ SG_ 427 ESC_AHW_nicht_verfuegbar "Rueckmeldung Anhaltewegregelung nicht verfuegbar
";
CM_ SG_ 427 ESC_ANB_CM_aktiv "Rueckmeldung ANB_CM (Autom_Notbremsung_Collision_Mitigation) aktiv
";
CM_ SG_ 427 ESC_ANB_CM_nicht_verfuegbar "Rueckmeldung ANB_CM nicht verfuegbar
";
CM_ SG_ 427 ESC_Bremslicht_unplausibel "Plausibilisierung der Rückmeldeinformation von BCM/AAG bezüglich Anforderung ESC_Bremslicht";
CM_ SG_ 427 ESC_Fahrer_Bremsdruck_bestimmend "Das Signal zeigt an, dass der Fahrer Bremsdruck bestimmend ist";
CM_ SG_ 427 ESC_HBA_aktiv "Rueckmeldung HBA (hydraulischer Bremsassistent) aktiv";
CM_ SG_ 427 ESC_HBA_nicht_verfuegbar "Rueckmeldung HBA (hydraulischer Bremsassistent) nicht verfuegbar";
CM_ SG_ 427 ESC_Konsistenz_ACC "Rueckmeldung Konsistenz der ACC Botschaften";
CM_ SG_ 427 ESC_Konsistenz_AGW "Rückmeldung Konsistenz der AGW-Botschaft an das ESC.";
CM_ SG_ 427 ESC_Konsistenz_ARA "Rueckmeldung Konsistenz der ARA Botschaften";
CM_ SG_ 427 ESC_Konsistenz_AWA "Rueckmeldung Konsistenz der AWA-Botschaften";
CM_ SG_ 427 ESC_Konsistenz_AWV "Rueckmeldung Konsistenz der AWV Botschaften";
CM_ SG_ 427 ESC_Konsistenz_BFF "Rückmeldung Konsistenz der Verzögerungsanforderung an das ESC-Steuergerät der Funktion 'Bremsen im freien Fahren' vom PDC_PLA_ARA-Steuergerät";
CM_ SG_ 427 ESC_Konsistenz_EA "Rueckmeldung Konsistenz der EA Botschaften (HCA)";
CM_ SG_ 427 ESC_Konsistenz_FAS_VK "Rueckmeldung Konsistenz der FAS_VK Botschaften";
CM_ SG_ 427 ESC_Konsistenz_FCW "Rueckmeldung Konsistenz der FCW Botschaften";
CM_ SG_ 427 ESC_Konsistenz_IPA "Rueckmeldung Konsistenz der IPA Botschaften";
CM_ SG_ 427 ESC_Konsistenz_KAS "Rückmeldung Konsistenz für Kreuzungsassistent-Anforderungen";
CM_ SG_ 427 ESC_Konsistenz_MKB "Rückmeldung Konsistenz für MKB-Verzögerungsanfoorderung";
CM_ SG_ 427 ESC_Konsistenz_NV "Rueckmeldung Konsistenz der NightVision Botschaften";
CM_ SG_ 427 ESC_Konsistenz_PCF "Rückmeldung der Konsistenz der PCF-Anforderungen";
CM_ SG_ 427 ESC_Konsistenz_RCTA "Rueckmeldung Konsistenz der RCTA (Rear Cross Traffic Alert) Botschaften";
CM_ SG_ 427 ESC_Konsistenz_STA "Rueckmeldung Konsistenz der STA Botschaften";
CM_ SG_ 427 ESC_Konsistenz_TSK "Rueckmeldung Konsistenz der TSK Botschaften";
CM_ SG_ 427 ESC_Konsistenz_vFGS "Rueckmeldung Konsistenz der vFGS Botschaften";
CM_ SG_ 427 ESC_Prefill_aktiv "Rueckmeldung Prefill aktiv";
CM_ SG_ 427 ESC_Prefill_nicht_verfuegbar "Rueckmeldung Prefill nicht verfuegbar";
CM_ SG_ 427 ESC_Pumpenanlauf_aktiv "Bestätigung der Durchführung eines Vorsteuerpumpenanlaufes";
CM_ SG_ 427 ESC_TSK_SRBM_Anf "Quittierung fuer TSK (SRBM=Summenradbremsmoment) Anforderung";
CM_ SG_ 427 ESC_TSK_SRBM_nicht_verfuegbar "Rueckmeldung TSK (SRBM= Summenradbremsmoment) nicht verfuegbar";
CM_ SG_ 427 ESC_Verz_ASIL_Verfuegbarkeit "Gibt die Verfuegbarkeit der VZM-Regelung an, wobei folgende Zustaende beruecksichtigt werden:
-Nicht Verfuegbarkeit wegen Sonderbetriebszustaenden (z.B. Produktionsmodus)
-ueber VZM abgebaute Fahrzeuggeschwindigkeit bei Verzögerungen a>5m/s², wobei gilt";
CM_ SG_ 427 ESC_Verz_Begrenzung "Rückmeldung angeforderte Verzögerung oder Summenradbremsmoment wird begrenzt umgesetzt  ";
CM_ SG_ 427 ESC_Verz_Reg_aktiv "Rueckmeldung Verzoegerungsregelung aktiv";
CM_ SG_ 427 ESC_Verz_Reg_nicht_verfuegbar "Rueckmeldung Verzoegerungsregelung nicht verfuegbar";
CM_ SG_ 427 ESC_Verz_Reg_TB_nicht_verfuegbar "Rueckmeldung Verzoegerungsregelung (Teilbremsung) nicht verfuegbar";
CM_ SG_ 427 ESC_Verz_Reg_ZB_nicht_verfuegbar "Rueckmeldung Verzoegerungsregelung ZB (Zielbremsung) nicht verfuegbar";
CM_ SG_ 427 ESC_Warnruck_aktiv "Rueckmeldung Warnruck aktiv";
CM_ SG_ 427 ESC_Warnruck_nicht_verfuegbar "Rueckmeldung Warnruck nicht verfuegbar";
CM_ SG_ 427 ESP_33_CRC "Für MLB:
'Berechnung siehe Lastenheft 'Kommunikationsabsicherung für FlexRay und CAN''

Ab MQB und MLBevo:
'Berechnung siehe Lastenheft 'End-to-End Kommunikationsabsicherung''

Endwerte siehe Begleitdokument 'S-PDU Kennungsfolgen'";

CM_ SG_ 87 BR_mi_Raddrehz "Mittelwert der Raddrehzahlen der angetriebenen Achse.
Bei Ausfall mind. eines Sensors wird 'Fehler' ausgegeben.
Bei Unterspannung an mind. einem Sensor wird 'Unterspannung' ausgegeben.
Im VW370/7 werden die Beträge der Raddrehzahlen VL und VR arithmeti";
CM_ SG_ 87 ESP_36_BZ "Botschaftszähler";
CM_ SG_ 87 ESP_36_CRC "Für MLB:
'Berechnung siehe Lastenheft 'Kommunikationsabsicherung für FlexRay und CAN''

Ab MQB und MLBevo:
'Berechnung siehe Lastenheft 'End-to-End Kommunikationsabsicherung''

Endwerte siehe Begleitdokument 'S-PDU Kennungsfolgen'";

CM_ SG_ 382 ESC_soll_Druck_EBKV "Stellgröße für den aufzubauenden Solldruck, den der eBKV aufbauen soll. Das Signal wird von allen ESC-Steuergeräten gesandt, die in Fahrzeugen mit eBKV verbaut werden.";
CM_ SG_ 382 ESC_soll_Druck_EBKV_Freigabe "Freigabebit für den zu stellenden Solldruck vom ESC an den eBKV";
CM_ SG_ 382 ESP_38_BZ "Botschaftszähler";
CM_ SG_ 382 ESP_38_CRC "Für MLB:
'Berechnung siehe Lastenheft 'Kommunikationsabsicherung für FlexRay und CAN''

Ab MQB und MLBevo:
'Berechnung siehe Lastenheft 'End-to-End Kommunikationsabsicherung''

Endwerte siehe Begleitdokument 'S-PDU Kennungsfolgen'";
CM_ SG_ 382 ESP_38_Sendestatus "Gibt den Sendestatus der Botschaft ESP_38 an (notwendig für IL-Unterstützung)";

CM_ SG_ 264 FA_ESP_Zuschaltung "Zwangsweise Aktivierung der ESP-Funktionalität wird angefordert auch bei Passivtastung";
CM_ SG_ 264 FA_Hoehenwert_HL_00 "Aktueller Höhenwert (kalibriert) Hinten Links; ungefiltertes Signal
Einheit, Offset und Faktor sind abhänig von 'FA_Hoehenwert_kalibriert'

Achtung:
Wird im AUDI B8 nicht bedient";
CM_ SG_ 264 FA_Hoehenwert_HL_01 "Aktueller Höhenwert (Rohwerte) Hinten Links; ungefiltertes Signal
Einheit, Offset und Faktor sind abhänig von 'FA_Hoehenwert_kalibriert'";
CM_ SG_ 264 FA_Hoehenwert_HR_00 "Aktueller Höhenwert (kalibriert) Hinten Rechts; ungefiltertes Signal
Einheit, Offset und Faktor sind abhänig von 'FA_Hoehenwert_kalibriert'

Achtung:
Wird im AUDI B8 nicht bedient";
CM_ SG_ 264 FA_Hoehenwert_HR_01 "Aktueller Höhenwert (Rohwerte) Hinten Rechts; ungefiltertes Signal
Einheit, Offset und Faktor sind abhänig von 'FA_Hoehenwert_kalibriert'";
CM_ SG_ 264 FA_Hoehenwert_VL_00 "Aktueller Höhenwert (kalibriert) Vorne Links; ungefiltertes Signal
Einheit, Offset und Faktor sind abhänig von 'FA_Hoehenwert_kalibriert'

Achtung:
Wird im AUDI B8 nicht bedient";
CM_ SG_ 264 FA_Hoehenwert_VL_01 "Aktueller Höhenwert (Rohwerte) Vorne Links; ungefiltertes Signal
Einheit, Offset und Faktor sind abhänig von 'FA_Hoehenwert_kalibriert'";
CM_ SG_ 264 FA_Hoehenwert_VR_00 "Aktueller Höhenwert (kalibriert) Vorne Rechts; ungefiltertes Signal
Einheit, Offset und Faktor sind abhänig von 'FA_Hoehenwert_kalibriert'

Achtung:
Wird im AUDI B8 nicht bedient";
CM_ SG_ 264 FA_Hoehenwert_VR_01 "Aktueller Höhenwert (Rohwerte) Vorne Rechts; ungefiltertes Signal
Einheit, Offset und Faktor sind abhänig von 'FA_Hoehenwert_kalibriert'";
CM_ SG_ 264 FA_Hoehenwerte_kalibriert "Legt fest, wie die Höhensensorwerte interpretiert werden müssen. Umschaltung kalibrierte Höhenwerte / Rohsignale in Byte 3-6

Achtung:
Im AUDI B8 Konstante: 0x1. D.h. es werden nur Rohwerte bedient!
Im AUDI D4 Konstante: 0x0. D.h. es werden nur Millim";
CM_ SG_ 264 Fahrwerk_01_CRC "Für MLB:
'Berechnung siehe Lastenheft 'Kommunikationsabsicherung für FlexRay und CAN''

Ab MQB und MLBevo:
'Berechnung siehe Lastenheft 'End-to-End Kommunikationsabsicherung''

Endwerte siehe Begleitdokument 'S-PDU Kennungsfolgen'";

CM_ SG_ 314 FCW_02_BZ "Botschaftszähler";
CM_ SG_ 314 FCW_02_CRC "Checksumme";
CM_ SG_ 314 FCWO_Anf_Prefill "Anforderung an ESP, dass die Prefill-Funktion aktiviert werden soll.";
CM_ SG_ 314 FCWO_HBA_Param "Anforderung an ESP, welcher HBA-Parametersatz verwendet werden soll.";
CM_ SG_ 314 FCWO_Ruck_Freigabe "Freigabit für die Warnruck-Anforderung an das ESP";
CM_ SG_ 314 FCWO_Ruckprofil "Anforderung an ESP, welcher Ruck aus einer Auswahl von max.
7 verschiedenen Ruckprofilen verwendet werden soll.
Eine Umsetzung der Ruckanforderung im ESP erfolgt nur mit gesetztem Bit 'FCWO_Ruck_ Freigabe'.";
CM_ SG_ 314 FCWP_Anf_Prefill "Anforderung an ESP, dass die Prefill-Funktion aktiviert werden soll.";
CM_ SG_ 314 FCWP_HBA_Param "Anforderung an ESP, welcher HBA-Parametersatz verwendet werden soll.";
CM_ SG_ 314 FCWP_Ruck_Freigabe "Freigabit für die Warnruck-Anforderung an das ESP";
CM_ SG_ 314 FCWP_Ruckprofil "Anforderung an ESP, welcher Ruck aus einer Auswahl von max. 7 verschiedenen Ruckprofilen verwendet werden soll. Eine Umsetzung der Ruckanforderung im ESP erfolgt nur mit gesetztem Bit 'FCWP_Ruck_ Freigabe'.";

CM_ SG_ 987 AAG_Anhaenger_abgesteckt "Anhaenger wurde bei Kl. 15 aus abgesteckt";
CM_ SG_ 987 AAG_Anhaenger_erkannt "Erkennung Anhaenger ";
CM_ SG_ 987 AAG_LED_aktiv "Dieses Signal sendet der Beleuchtungsart des Anhängers (LED oder Lampe)
Bei LED aktiv erfolgt kein Kaltüberwachung";
CM_ SG_ 987 BCM1_Aussen_Temp_ungef "ungefilterter Wert des Aussentemperatursensors
";
CM_ SG_ 987 BCM1_LDS_Stellung "Das Signal wird vom AFS / LWR Steuergerät empfangen und dient der Verifizierung der Lichtdrehschalterstellung. Intelligente Lichtfunktionen wie dyn. KL und gleitende Leuchtweite (GLW) nur bei LDS = 'AUTO'.";
CM_ SG_ 987 BCM1_MH_Schalter "Motorhaubenkontakt";
CM_ SG_ 987 BCM1_OBD_FStatus_ATemp "Fehlerstatus Umgebungstemperatursensor (OBD relevanter Sensor)
";
CM_ SG_ 987 BCM1_Rueckfahrlicht_Schalter "Rückfahrlichtschalter
ab MQB/ MLBevo: Die Ganginformation wird unentprellt übertragen, im AT-Getriebe wird evtl. kurzzeitig der R-Gang angezeigt. Eine Entprellung muß im Empfänger erfolgen (typisch 400ms).";
CM_ SG_ 987 BCM_Rueckfahrlicht_Anf "Anforderung Rückfahrlicht (Sollzustand). 
Das Signal wird entprellt (typisch 400ms) und bei KL15EIN gesendet. Das Signal ist unabhängig von der Position des Heckdeckels (kein Überhitzungsschutz).";
CM_ SG_ 987 BCM_Tankklappensteller_Fehler "Fehler: nicht Funktionalität des Tankklappenstellers";
CM_ SG_ 987 BH_Blinker_li "Blinkerhebel Richtung links
";
CM_ SG_ 987 BH_Blinker_re "Blinkerhebel Richtung rechts
";
CM_ SG_ 987 BH_Fernlicht "Betaetigung Fernlicht
";
CM_ SG_ 987 BH_Lichthupe "Betaetigung Lichthupe
";
CM_ SG_ 987 KL_Thermomanagement "Stufen des Thermomanagements;
Bei Klemme 15 AUS und erkannten Timeout zum Klimabedienteil (z.B. Klimabedienteil während des Motorsteuergeräte-Kommunikations-Nachlaufs bereits im NM-Zustand ¿Bus Sleep¿)
erfolgt keine Ansteuerung der Wasserpumpe durch die";
CM_ SG_ 987 VS_VD_entriegelt "

";
CM_ SG_ 987 VS_VD_offen_ver "

";
CM_ SG_ 987 VS_VD_zu_ver "
";
CM_ SG_ 987 VS_Verdeck_Anf "



";
CM_ SG_ 987 Waschen_vorne_aktiv "Status: Waschen vorne aktiv 
";
CM_ SG_ 987 WFS_ID_Geb_autorisiert_in_Kl15 "Authorisierung des Schlüssels im aktiven Klemme-15-Zyklus";
CM_ SG_ 987 WFS_Klemmenfreigabe "Freigabe von der WFS zum Einschalten der Klemme 15 und Klemme S";
CM_ SG_ 987 WFS_Schluessel_Fahrberecht "Schlüsselnummer Fahrberechtigung
0 = ungueltig, xxxx = Schluessel-Nr.";
CM_ SG_ 987 Wischer_vorne_aktiv "Status: Wischer vorne ";
CM_ SG_ 987 WWSs_01_alt "Veraltet Bit für die LIN-Botschaft WWSs_01.

Betroffene Signale:

Wischer_vorne_aktiv";
CM_ SG_ 987 ZV_BT_offen "gespiegeltes Bit BT_Tuer_geoeffnet TSG_BT_1 Botschaft";
CM_ SG_ 987 ZV_FT_offen "gespiegeltes Bit FT_Tuer_geoeffnet TSG_FT_1 Botschaft";
CM_ SG_ 987 ZV_HBFS_offen "gespiegeltes Bit HBFS_Tuer_geoeffnet TSG_HBFS_1 Botschaft";
CM_ SG_ 987 ZV_HD_offen "Status Heckdeckel
";
CM_ SG_ 987 ZV_HFS_offen "gespiegeltes Bit HFS_Tuer_geoeffnet TSG_HFS_1 Botschaft";
CM_ SG_ 987 ZV_Schluessel_Zugang "aktuelle Funkschlüsselnummer";
CM_ SG_ 987 ZV_Tankklappe_offen "Öffnungsstatus der Tankklappe";
CM_ SG_ 987 ZV_verriegelt_extern_soll "Sollzustand: Verriegelung Fahrzeug aussen
";
CM_ SG_ 987 ZV_verriegelt_soll "Fahrzeug Gesamtverriegelungsstatus Sollzustand für Ladestecker- und Ladeklappenverriegelung. ";

CM_ SG_ 1004 ACC_Status_Anzeige "Status nur zur Defintion von Anzeige im Kombi. Hinweis: Wird für die spez. VW-Anzeige (überlappende Anzeigebereiche) verwendet. Vom AUDI-ACC im Rahmen der Modulstrategie zu bedienen.";
CM_ SG_ 1004 HC_Uss_Anforderung "Ansteuerung der vorderen PLA (VLS, VRS) und APS Sensoren (VL, VR)
0 = Ultraschallsensoren Aus
1 = Ultraschallsensoren An";
CM_ SG_ 1004 HD_Endstellung_oben "obere Endstellung HD
";
CM_ SG_ 1004 HD_Endstellung_unten "untere Endstellung HD
";
CM_ SG_ 1004 HD_Position "HD Position von 0 bis 100 %";
CM_ SG_ 1004 KL_Vorwarn_Komp_ein "Vorwarnung Kompressor ein; 140ms vorher; Information für Motor zum Aufbau Momentenreserve";
CM_ SG_ 1004 MO_NGS_Position "Messwert des Neutralgangsensors
(nur Handschalter)";
CM_ SG_ 1004 MO_NGS_Status "Status des Signals MO_NGS_Position. Das MSG prüft die Plausibilität nur hinsichtlich sicher geöffnetem Triebstrang.";

CM_ SG_ 173 GE_Fahrstufe "Fahrprogramm des Getriebes

Hinweis: Zwischenstellung '0x0' darf nur für Zustandswechsel P/R, R/N, N/D ausgegeben werden, nicht für D/S oder D/Tippgasse wegen Abschaltkriterium GRA/ACC";
CM_ SG_ 173 GE_Freig_MMom_Vorhalt "Freigabe für die Anforderung einer Momentenreserve durch das Getriebe über das Signal
MLB: GE_MMom_Vorhalt
MQB/MLBevo: GE_MMom_Vorhalt_02";
CM_ SG_ 173 GE_MMom_Soll_02 "Momenteneingriff an den Motor.
Fordert vom MSG eine kurzfristige Reduzierung oder Anhebung des Moments.
Das Signal ist nur gültig in Kombination mit GE_MMom_Status (bei MQB) bzw. GE_MMom_Status_02 (bei MLBevo).

Achtung:
Einheitenloser Wert! Faktor i";
CM_ SG_ 173 GE_MMom_Status "Qualifiziert 
MLB: GE_MMom_Soll
MQB: GE_MMom_Soll_02";
CM_ SG_ 173 GE_MMom_Status_02 "Das Signal qualifiziert GE_MMom_Soll_02 und gibt an, wie GE_MMom_Soll_02 umgesetzt werden soll.
Werte:
0= kein Eingriff
1=   absoluter reduzierender Eingriff auf Gesamt Antrieb nur über schnellen Pfad 
2 = absoluter, erhöhender Eingriff auf Gesamt-Ant";
CM_ SG_ 173 GE_MMom_Vorhalt_02 "Anforderung einer Momentenreserve durch das Getriebe, gilt nur mit Freigabe durch 
GE_Freig_MMom_Vorhalt

Anforderung wird als Absolut-Wert umgesetzt, nicht als Relativ-Wert/Delta zum aktuellen Ist-Moment (d. h. eine Momentenreserve wird eingestellt, w";
CM_ SG_ 173 GE_reserv_Fahrstufe "reserviert, falls künftig Erweiterung von GE_Fahrstufe nötig";
CM_ SG_ 173 GE_Schaltablauf "Das Signal zeigt den aktuellen Status eines Schaltvorgangs.

Bei Signal = 0 liegt kein Schaltvorgang vor.
Bei Signal =2 liegt die Befüllphase der zuschaltenden Kupplung bzw. 
                      die Vorbereitungsphase dazu vor.

Mit den unterschie";
CM_ SG_ 173 GE_Status_Kraftschluss "Zeigt den Ist-Status des Kraftschlusses im Getriebe.
(Anmerkung: meist wird damit der Zustand des Anfahrelements beschrieben, d.h. bei DL/DQ die Kupplung;  bei AQ/AL der Wandler incl. Überbrückungskupplung)
0 = offen, kein Kraftschluss
1 = offen mit Kr";
CM_ SG_ 173 GE_Uefkt "Übertragungsfunktion des Getriebes
Drehzahlverhältnis = Eingangsdrehzahl / Ausgangsdrehzahl

AL: Wandlerverstärkung x Drehzahlverhältnis
VL: Drehzahlverhältnis
DL: Drehzahlverhältnis der aktiven und kraftschluß führenden Welle zum Abtrieb, bei Schalt";
CM_ SG_ 173 GE_Uefkt_unplausibel "Das Signal darf nur im Reku-Manager in Hybrid-Varianten verwendet werden.
Zeigt an, ob die Plausibilisierung Momenten-Verhältnis zu Drehzahl-Verhältnis i.O. ist.
Ein gesetztes Signal meldet eine unplausible GE_Uefkt bzw. GE_Uefkt_02.";
CM_ SG_ 173 GE_Verbot_Ausblendung "Verbot Einspritzausblendung für komfortable Schaltungen";
CM_ SG_ 173 GE_Zielgang "VL-Getriebe:
Signalisiert den Zielgang im manuellen Modus während eines Schaltvorgangs bzw. die momentane simulierte Gangstufe wenn kein Schaltvorgang aktiv ist. In den Fahrprogrammen 'D' und 'S' ist die Übersetzung variabel und somit wird dauerhaft 'Ist";
CM_ SG_ 173 Getriebe_11_BZ "Botschaftszähler
Botschaft asynchron geroutet. Zählerwert kann springen.";
CM_ SG_ 173 Getriebe_11_CRC "Für MLB:
'Berechnung siehe Lastenheft 'Kommunikationsabsicherung für FlexRay und CAN''

Ab MQB und MLBevo:
'Berechnung siehe Lastenheft 'End-to-End Kommunikationsabsicherung''

Endwerte siehe Begleitdokument 'S-PDU Kennungsfolgen'";

CM_ SG_ 968 Freilauf_Charisma_FahrPr "MLBevo: Aktuelles Fahrprogramm des Charisma-Teilnehmers (siehe Systemlastenheft Drive Select)
MQB: Istwert der Kennlinie (siehe Systemlastenheft MQB FPA)";
CM_ SG_ 968 Freilauf_Charisma_Status "Charisma Systemstatus des Charisma-Teilnehmers

Wert 0x3 ist nur für Fahrzeuge ab MQB relevant";
CM_ SG_ 968 GE_amax_moeglich "AL/DL: maximal mögliche Beschleunigung unter Berücksichtigung aller möglichen Gänge.

Eine Reduzierung des maximalen Motormoments durch Efficiency wird in dem Signal berücksichtigt.

VL: maximal mögliche Beschleunigung bei Nenndrehzahl (Efficency wird";
CM_ SG_ 968 GE_Charisma_FahrPr "MLBevo: Aktuelles Fahrprogramm des Charisma-Teilnehmers (siehe Systemlastenheft Drive Select)
MQB: Istwert der Kennlinie (siehe Systemlastenheft MQB FPA)";
CM_ SG_ 968 GE_Charisma_Status "Charisma Systemstatus des Charisma-Teilnehmers

Wert 0x3 ist nur für Fahrzeuge ab MQB relevant";
CM_ SG_ 968 GE_Codierung_MSG "Statusausgabe der Diagnose für Falschverbau. Plausibilisierung der empfangenen Motor- und Getriebevariante mit der erwarteten Motor- und Getriebevarianten.";
CM_ SG_ 968 GE_Freigabe_Info_WFS "WFS-Freigabeinformation";
CM_ SG_ 968 GE_Freigabe_Verfallsinfo_WFS "WFS";
CM_ SG_ 968 GE_LaunchControl "Während einer LaunchControl-Anfahrt sendet das Getriebesteuergerät das Bit LaunchControl aktiv.
Die Bremse wertet dieses Bit aus, um während einer solchen Anfahrt die Regelgrenzen der Schlupfregelung zu erweitern.
Im Motor Nutzung zur Verbesserung des A";
CM_ SG_ 968 GE_LFR_Adaption "Qualifiziert das ausgegeben Motorbelastungsmoment (durch GE_Vorsteuermoment) für die Verwendung zur LFR (Leerlauffüllungsregelung) im Moto";
CM_ SG_ 968 GE_OBD_AbsperrVent "Das Getriebesteuergerät führt eine elektrische Diagnose des von ihm angesteuerten Absperrventils für den Öl-Wasser-Wärmetauscher durch und übermittelt das Ergebnis an das MSG (Standard-4Bit-OBD-Status, nicht alle Zustände müssen genutzt werden; so sind z.";
CM_ SG_ 968 GE_OBD_Status "Dieses Bit steuert die MIL-Lampe an (Motorsteuergerät reicht diese Info an Kombi weiter).";
CM_ SG_ 968 GE_Sperr_Info_WFS "WFS-Sperrinformation";
CM_ SG_ 968 GE_Sumpftemperatur "Getriebesumpftemperatur wird über den Temperatursensor auf der Getriebeplatine ermittelt. Die absolute Sumpftemperatur wird vom Motor empfangen, um entsprechende Kühlleistung für das Getriebe einzustellen.";
CM_ SG_ 968 GE_Verlustmoment "Achtung einheitenloser Wert !!
	Faktor in MO_Faktor_Momente (MLB) bzw. MO_Faktor_Momente_02 (MQB/MLBevo) in Motor_Code_01 beachten!

ab MQB/MLBevo:
	Das Signal enthält die berechneten Momentenverluste, welche innerhalb des Getriebegehäuses entstehen (";
CM_ SG_ 968 GE_Zustand_Kuppltemp "Dieses Signal gibt den Temperaturzustand der Kupplung im DQ-Getriebe (z. Zt. DQ2x0, DQ500) an das ACC-System.";

CM_ SG_ 294 EA_ACC_Sollstatus "Status-Anforderung ACC von Emergency Alert. Statuswechsel bei Flanke. Solange Wert=1, wird EA_ACC_Wunschgeschwindigkeit übernommen. Wert=2 führt zu Zustand ¿ACC_GRA_passiv¿";
CM_ SG_ 294 EA_ACC_Wunschgeschwindigkeit "Emergency Alert Anforderung neue Wunschgeschwindigkeit";
CM_ SG_ 294 EA_Ruckfreigabe "Emergency Alert Freigabit für die Warnruck-Anforderung an das ESP";
CM_ SG_ 294 EA_Ruckprofil "Emergency Alert Anforderung an ESP, welcher Ruck verwendet werden soll. Eine Umsetzung der Ruckanforderung im ESP erfolgt nur mit gesetztem Bit 'EA_Ruckfreigabe'.";
CM_ SG_ 294 HCA_01_CRC "Für MLB:
'Berechnung siehe Lastenheft 'Kommunikationsabsicherung für Flexray und CAN''

Ab MQB und MLBevo:
'Berechnung siehe Lastenheft 'End-to-End Kommunikationsabsicherung'

Endwerte siehe Begleitdokument 'S-PDU Kennungsfolge'";
CM_ SG_ 294 HCA_01_LM_Offset "Von HCA angefordertes Lenkmoment (Betrag)";
CM_ SG_ 294 HCA_01_LM_OffSign "Vorzeichen des HCA-Lenkmoments";
CM_ SG_ 294 HCA_01_Sendestatus "Gibt den Sendestatus der HCA_01 an (notwendig für IL-Unterstützung)";
CM_ SG_ 294 HCA_01_Status_HCA "Statusinformation vom HCA und Manoevrierassistent für Handshakemechanismus mit der Lenkung";
CM_ SG_ 294 HCA_01_Vib_Amp "Momentenamplitude der Lenkradvibration";
CM_ SG_ 294 HCA_01_Vib_Freq "Frequenz der Lenkradvibration";

CM_ SG_ 1412 HSP_01_CRC "CRC8-Checksumme über alle Datenbytes der Botschaft HSPs_01

 Für MLB:
 'Berechnung siehe Lastenheft 'Kommunikationsabsicherung für Flexray und CAN''

 Ab MQB und MLBevo:
 'Berechnung siehe Lastenheft 'End-to-End Kommunikationsabsicherung'

 Endwer";
CM_ SG_ 1412 HSP_Charisma_FahrPr "MLBevo: Aktuelles Fahrprogramm des Charisma-Teilnehmers (siehe Systemlastenheft Drive Select)
MQB: Istwert der Kennlinie (siehe Systemlastenheft MQB FPA)";
CM_ SG_ 1412 HSP_Charisma_Status "Rückmeldung an den Charisma-Master

Wert 0x3 ist nur für Fahrzeuge ab MQB relevant";
CM_ SG_ 1412 HSP_Endlage_ausgefahren "Spoiler in Endlage ausgefahren";
CM_ SG_ 1412 HSP_Endlage_eingefahren "Spoiler in Endlage eingefahren";
CM_ SG_ 1412 HSP_Motor_def "elektr. Fehler im Spoilermotor";
CM_ SG_ 1412 HSP_Taster_Error "Spoiler meldet Tasterfehler";
CM_ SG_ 1412 HSP_Warnung_Text "Kombi Warnung Text Spoiler";
CM_ SG_ 1412 HSP_Warnung_Ton "Kombi Warnung Ton Spoiler";

CM_ SG_ 1811 ISO_ABS_Req_Data "Diagnose Request Bremsen-SG/Elektronisches Stabilitätsprogramm";

CM_ SG_ 1917 ISO_ABS_Resp_Data "Diagnose Response Bremsen-SG/Elektronisches Stabilitätsprogramm";

CM_ SG_ 1807 ISO_Allrad_Req_Data "Diagnose Request Allradsteuergeraet";

CM_ SG_ 1913 ISO_Allrad_Resp_Data "Diagnose Response Allradsteuergeraet";

CM_ SG_ 1906 ISO_Daempfer_Req_Data "Diagnose Request Daempfer-Steuergeraet";

CM_ SG_ 2012 ISO_Daempfer_Resp_Data "Diagnose Response Daempfer-Steuergeraet";

CM_ SG_ 1802 ISO_EPH_Req_Data "Diagnose Request Einparkhilfe";

CM_ SG_ 1908 ISO_EPH_Resp_Data "Diagnose Response Einparkhilfe";

CM_ SG_ 1795 ISO_Funktionaler_Req_Abgas "Funktionaler Request für abgasrelevante Steuergeraete";

CM_ SG_ 1792 ISO_ALL_01_Req_Data "Funktionaler Request ALL";

CM_ SG_ 2015 ISO_OBD_Funktionaler_Req_Data "Funktionaler Request für OBD relevante Steuergeraete";

CM_ SG_ 1810 ISO_Lenkhilfe_Req_Data "Diagnose Request Lenkhilfe (EPS)";

CM_ SG_ 1916 ISO_Lenkhilfe_Resp_Data "Diagnose Response Lenkhilfe (EPS)";

CM_ SG_ 2020 ISO_OBD_03_Req_Data "Diagnose Request 03 für OBD relevante Steuergeraete
MLBevo: ESC
MQB: ESC";

CM_ SG_ 2028 ISO_OBD_03_Resp_Data "Diagnose Response 03 für OBD relevante Steuergeraete
MLBevo: ESC
MQB: ESC";

CM_ SG_ 1897 ISO_Rearview_Req_Data "Diagnose Request Rearview/Areaview-Steuergerät";

CM_ SG_ 2003 ISO_Rearview_Resp_Data "Diagnose Response Rearview/Areaview-Steuergerät";

CM_ SG_ 960 BCM_Ausparken_Betrieb "Anforderung zur erneuten Lampenaufprüfung und Anzeige von Warnhinweisen nach einem pilotierten Ausparkvorgang (Trigger: fallende Flanke)";
CM_ SG_ 960 BCM_Remotestart_Betrieb "Zeigt den Status des RemoteStarts an, d.h. KL15_RSt ist aktiviert und der Motorlauf ist im RSt-Betrieb aktiv.";
CM_ SG_ 960 BCM_Remotestart_KL15_Anf "Zeigt den Status der Aktivierung der KL15_RST durch das BCM an.";
CM_ SG_ 960 BCM_Remotestart_MO_Start "Nachdem das BCM die Remotestart MSG Freigabe sicher erkannt hat, fordert das BCM wiederum über dieses Signal vom MSG einen Motorstart durchzuführen.";
CM_ SG_ 960 Klemmen_Status_01_BZ "4bit Botschaftszaehler; wird in jeder Sendebotschaft inkrementiert";
CM_ SG_ 960 Klemmen_Status_01_CRC "Für MLB:
'Berechnung siehe Lastenheft 'Kommunikationsabsicherung für FlexRay und CAN''

Ab MQB und MLBevo:
'Berechnung siehe Lastenheft 'End-to-End Kommunikationsabsicherung''

Endwerte siehe Begleitdokument 'S-PDU Kennungsfolgen'";
CM_ SG_ 960 KST_Fahrerhinweis_1 "Signalisierung Fahrerhinweis 1 der Klemmensteuerung an das Kombi";
CM_ SG_ 960 KST_Fahrerhinweis_2 "Signalisierung Fahrerhinweis 2 der Klemmensteuerung an das Kombi";
CM_ SG_ 960 KST_Fahrerhinweis_4 "Signalisierung Fahrerhinweis 4 der Klemmensteuerung an das Kombi";
CM_ SG_ 960 KST_Fahrerhinweis_5 "Anzeigesignal für RemoteStart";
CM_ SG_ 960 KST_Fahrerhinweis_6 "Signal aktiviert die Kombi-Anzeigeinstrumente (Drehzahl, Tankinhalt, Kühlmitteltemperatur) während aktiviertem RemoteStart-Betrieb";
CM_ SG_ 960 KST_Warn_P1_ZST_def "Kombi Prio Warnung Klemmensteuerung 
Zündschloß defekt, Service aufsuchen!";
CM_ SG_ 960 KST_Warn_P2_ZST_def "Kombi Prio Warnung Klemmensteuerung
Zündschloß defekt!
";
CM_ SG_ 960 RSt_Fahrerhinweise "Über das Signal fordert das BCM Fahrerhinweise im Kombi für die Funktion RemoteStart an.";
CM_ SG_ 960 ZAS_Kl_15 "Klemme 15: Zuendung (SW-Kl.15)
";
CM_ SG_ 960 ZAS_Kl_50_Startanforderung "Klemme 50: Startwunsch Fahrer
";
CM_ SG_ 960 ZAS_Kl_Infotainment "Separate Klemmeninformation für das Infotainment. Signal entspricht im wesentlichen einer Klemme S Information, kann aber über einen Vor - bzw. Nachlauf zu Klemme S verfügen. 
Ein konkreter Anwendungsfall für einen Nachlauf ist die Abschaltung der Klemme";
CM_ SG_ 960 ZAS_Kl_S "Klemme S: S-Kontakt (Schluessel steckt)
";
CM_ SG_ 960 ZAS_Kl_X "Klemme 75
";

CM_ SG_ 1640 FSH_Taster "Tasterbetätigung Frontscheibenheizung
";
CM_ SG_ 1640 HSH_Taster "An-/Abforderung Heckscheibenheizung über spezielles Tastersignal
";
CM_ SG_ 1640 KL_Beschlagsgefahr "Beschlagsgefahr auf der Frontscheibe im Bereich des Spiegelfusses. Dient zur präventiven Ansteuerung der  Kamera-Scheibenheizung, um Kamera-Blindheit zu vermeiden
PHEV: volle Leistungsfreigabe 
HV Heizer und HV EKK bei Scheibenbeschlag ";
CM_ SG_ 1640 KL_Geblspng_Fond_Soll "Ausgabe des Sollwertes für die Spannung des Klimagebläsemotores hinten.






";
CM_ SG_ 1640 KL_Geblspng_Soll "Ausgabe des Sollwertes für die Spannung des Klimagebläsemotores vorne.







";
CM_ SG_ 1640 KL_I_Geblaese "Stromaufnahme Gebläse";
CM_ SG_ 1640 KL_Kompressorstrom_soll "Sollvorgabe Klima-Kompressorstrom";
CM_ SG_ 1640 KL_LRH_Stufe "Eingestellte Temperaturstufe der Lenkradheizung";
CM_ SG_ 1640 KL_LRH_Taster "Tasterbetätigung Lenkradheizung";
CM_ SG_ 1640 KL_PTC_Verbauinfo "Im Klima- bzw. Heizungsbedienteil wird der Verbau eines PTCs und dessen elektr. Leistungsklasse codiert";
CM_ SG_ 1640 KL_SIH_Soll_li "Einstellung Sitzheizung Fahrer (0...6)";
CM_ SG_ 1640 KL_SIH_Soll_re "Einstellung Sitzheizung Beifahrer (0...6)";
CM_ SG_ 1640 KL_SIL_Soll_li "Einstellung Sitzlüftung Fahrer (0...6)";
CM_ SG_ 1640 KL_SIL_Soll_re "Einstellung Sitzlüftung Beifahrer (0...6)";
CM_ SG_ 1640 KL_Umluftklappe_Status "Status Umluftklappe";
CM_ SG_ 1640 KL_Zuheizer_Freigabe "Freigabe Zuheizer
";
CM_ SG_ 1640 KRH_Soll_li "Ausgabe des Sollwertes für die Kopfraumheizung links.";
CM_ SG_ 1640 KRH_Soll_re "Ausgabe des Sollwertes für die Kopfraumheizung rechts.";

CM_ SG_ 2549088275 ABS_Abschaltstufe "Funktionseinschränkung aufgrund aktiver Abschaltstufe";
CM_ SG_ 2549088275 ABS_SNI "Das Signal beinhaltet den Source Node Identifier (Knotenadresse, die auch in der Abbildungsvorschrift zur CAN-ID für die NM-High Botschaft verwendet wird).";
CM_ SG_ 2549088275 ABS_Transport_Mode "Funktionseinschränkung aufgrund aktivem Transport Mode und/oder Transport Schutz";
CM_ SG_ 2549088275 ESP_KompSchutz "Funktionseinschränkung aufgrund Komponentenschutz aktiv";
CM_ SG_ 2549088275 ESP_Nachlauftyp "Abgebildet wird die von der Hardware vorgegebene Möglichkeit, die Kommunikation nach Klemme 15 = AUS aufrecht zu erhalten. Es wird ein Init-Wert gesendet.
0 = Kommunikation nur bei KL15=EIN (kein Nachlauf, nicht weckfähig)
1 = Kommunikation nach KL15=AU";
CM_ SG_ 2549088275 KN_ESP_BusKnockOutTimer "Ausgabe des BusKnockOut-Timer in der Knotenbotschaft";

CM_ SG_ 2549088271 Allrad_Abschaltstufe "Funktionseinschränkung aufgrund aktiver Abschaltstufe";
CM_ SG_ 2549088271 Allrad_KompSchutz "Funktionseinschränkung aufgrund Komponentenschutz aktiv";
CM_ SG_ 2549088271 Allrad_Nachlauftyp "Abgebildet wird die von der Hardware vorgegebene Möglichkeit, die Kommunikation nach Klemme 15 = AUS aufrecht zu erhalten. Es wird ein Init-Wert gesendet.
0 = Kommunikation nur bei KL15=EIN (kein Nachlauf, nicht weckfähig)
1 = Kommunikation nach KL15=AU";
CM_ SG_ 2549088271 Allrad_SNI "Das Signal beinhaltet den Source Node Identifier (Knotenadresse, die auch in der Abbildungsvorschrift zur CAN-ID für die NM-High Botschaft verwendet wird).";
CM_ SG_ 2549088271 Allrad_Transport_Mode "Funktionseinschränkung aufgrund aktivem Transport Mode und/oder Transport Schutz";
CM_ SG_ 2549088271 ALR_KD_Fehler "Bei gesetztem Bit ist mindestens ein Kundendienstfehler eingetragen";

CM_ SG_ 2549088370 Daempfer_Abschaltstufe "Funktionseinschränkung aufgrund aktiver Abschaltstufe";
CM_ SG_ 2549088370 Daempfer_KompSchutz "Funktionseinschränkung aufgrund Komponentenschutz aktiv";
CM_ SG_ 2549088370 Daempfer_Nachlauftyp "Abgebildet wird die von der Hardware vorgegebene Möglichkeit, die Kommunikation nach Klemme 15 = AUS aufrecht zu erhalten. Es wird ein Init-Wert gesendet.
0 = Kommunikation nur bei KL15=EIN (kein Nachlauf, nicht weckfähig)
1 = Kommunikation nach KL15=AU";
CM_ SG_ 2549088370 Daempfer_SNI "Das Signal beinhaltet den Source Node Identifier (Knotenadresse, die auch in der Abbildungsvorschrift zur CAN-ID für die NM-High Botschaft verwendet wird).";
CM_ SG_ 2549088370 Daempfer_Transport_Mode "Funktionseinschränkung aufgrund aktivem Transport Mode und/oder Transport Schutz";

CM_ SG_ 2549088266 EPH_Abschaltstufe "Funktionseinschränkung aufgrund aktiver Abschaltstufe";
CM_ SG_ 2549088266 EPH_KompSchutz "Funktionseinschränkung aufgrund Komponentenschutz aktiv";
CM_ SG_ 2549088266 EPH_Nachlauftyp "Abgebildet wird die von der Hardware vorgegebene Möglichkeit, die Kommunikation nach Klemme 15 = AUS aufrecht zu erhalten. Es wird ein Init-Wert gesendet.
0 = Kommunikation nur bei KL15=EIN (kein Nachlauf, nicht weckfähig)
1 = Kommunikation nach KL15=AU";
CM_ SG_ 2549088266 EPH_SNI "Das Signal beinhaltet den Source Node Identifier (Knotenadresse, die auch in der Abbildungsvorschrift zur CAN-ID für die NM-High Botschaft verwendet wird).";
CM_ SG_ 2549088266 EPH_Transport_Mode "Funktionseinschränkung aufgrund aktivem Transport Mode und/oder Transport Schutz";
CM_ SG_ 2549088266 PH_KD_Fehler "Meldung, ob mindestens ein Fehler mit Priorität 1....6 im Fehlerspeicher eingetragen ist (aktiv oder passiv), gilt nicht für Fehler im Entwicklungsfehlerspeicher. Bit wird erst mit Löschen des Fehlerspeichers zurückgenommen.";

CM_ SG_ 2549088274 Lenkhilfe_Abschaltstufe "Funktionseinschränkung aufgrund aktiver Abschaltstufe";
CM_ SG_ 2549088274 Lenkhilfe_KompSchutz "Funktionseinschränkung aufgrund Komponentenschutz aktiv";
CM_ SG_ 2549088274 Lenkhilfe_Nachlauftyp "Abgebildet wird die von der Hardware vorgegebene Möglichkeit, die Kommunikation nach Klemme 15 = AUS aufrecht zu erhalten. Es wird ein Init-Wert gesendet.
0 = Kommunikation nur bei KL15=EIN (kein Nachlauf, nicht weckfähig)
1 = Kommunikation nach KL15=AU";
CM_ SG_ 2549088274 Lenkhilfe_SNI "Das Signal beinhaltet den Source Node Identifier (Knotenadresse, die auch in der Abbildungsvorschrift zur CAN-ID für die NM-High Botschaft verwendet wird).";
CM_ SG_ 2549088274 Lenkhilfe_Transport_Mode "Funktionseinschränkung aufgrund aktivem Transport Mode und/oder Transport Schutz";

CM_ SG_ 2549088361 KN_Rearview_BusKnockOutTimer "Ausgabe des BusKnockOut-Timer in der Knotenbotschaft";
CM_ SG_ 2549088361 Rearview_Abschaltstufe "Funktionseinschränkung aufgrund aktiver Abschaltstufe";
CM_ SG_ 2549088361 Rearview_KompSchutz "Funktionseinschränkung aufgrund Komponentenschutz aktiv";
CM_ SG_ 2549088361 Rearview_Nachlauftyp "Abgebildet wird die von der Hardware vorgegebene Möglichkeit, die Kommunikation nach Klemme 15 = AUS aufrecht zu erhalten. Es wird ein Init-Wert gesendet.
0 = Kommunikation nur bei KL15=EIN (kein Nachlauf, nicht weckfähig)
1 = Kommunikation nach KL15=AU";
CM_ SG_ 2549088361 Rearview_SNI "Das Signal beinhaltet den Source Node Identifier (Knotenadresse, die auch in der Abbildungsvorschrift zur CAN-ID für die NM-High Botschaft verwendet wird).";
CM_ SG_ 2549088361 Rearview_Transport_Mode "Funktionseinschränkung aufgrund aktivem Transport Mode und/oder Transport Schutz";
CM_ SG_ 2549088361 RV_KD_Fehler "Status Kundendienstfehlerspeichereinträge";
BA_DEF_REL_ BU_SG_REL_  "GenSigTimeoutTime" INT 0 65535;
BA_DEF_ BO_  "DiagRequest" ENUM "No", "Yes";
BA_DEF_ BO_  "DiagResponse" ENUM "No", "Yes";
BA_DEF_ BO_  "DiagState" ENUM "No", "Yes";
BA_DEF_ BO_  "GenMsgChkConstant" HEX 0 4095;
BA_DEF_ BO_  "GenMsgCycleTime" INT 0 65535;
BA_DEF_ BO_  "GenMsgCycleTimeFast" INT 0 65535;
BA_DEF_ BO_  "GenMsgDelayTime" INT 0 100000;
BA_DEF_ BO_  "GenMsgILSupport" ENUM "No", "Yes";
BA_DEF_ BO_  "GenMsgNrOfRepetition" INT 0 100;
BA_DEF_ BO_  "GenMsgPDUConstants" STRING;
BA_DEF_ BO_  "GenMsgSendType" ENUM "Cyclic", "not_used", "not_used", "not_used", "not_used", "not_used", "not_used", "IfActive", "NoMsgSendType";
BA_DEF_ BO_  "GenMsgStartDelayTime" INT 0 100000;
BA_DEF_ BO_  "NmMessage" ENUM "No", "Yes";
BA_DEF_ BO_  "NmhMessage" ENUM "No", "Yes";
BA_DEF_ BO_  "MsgType" ENUM "Application", "NM ", "NMH", "TP2.0", "ISO-TP ", "BAP", "EID", "KS";
BA_DEF_ BO_  "VAGTP20_API" HEX 0 255;
BA_DEF_ BO_  "VAGTP20_DynConnection" ENUM "No", "Yes";
BA_DEF_ BO_  "VAGTP20_DynSetup" ENUM "No", "Yes";
BA_DEF_ BO_  "VAGTP20_StatConnection" ENUM "No", "Yes";
BA_DEF_ SG_  "GenSigActiveRepetitions" INT -2147483648 2147483647;
BA_DEF_ SG_  "GenSigInactiveValue" INT -2147483648 2147483647;
BA_DEF_ SG_  "GenSigSendType" ENUM "Cyclic", "OnWrite", "OnWriteWithRepetition", "OnChange", "OnChangeWithRepetition", "IfActive", "IfActiveWithRepetition", "NoSigSendType", "OnChangeAndIfActive", "OnChangeAndIfActiveWithRepetition";
BA_DEF_ SG_  "GenSigStartValue" INT -2147483648 2147483647;
BA_DEF_ SG_  "NWM-WakeupAllowed" ENUM "No", "Yes";
BA_DEF_ SG_  "GenSigFuncType" ENUM "NoFunction", "MsgCounter", "CRC-8", "XOR", "XOR-2", "DatedBit", "SW-Kl15", "CHK", "Constant", "Protocol", "CRC-8-SAE_J1850";
BA_DEF_ SG_  "GenSigSwitchedByIgnition" ENUM "No", "Yes";
BA_DEF_ SG_  "Fehlerwert" HEX 0 2147483647;
BA_DEF_ SG_  "GenSigMissingSourceValue" HEX 0 2147483647;
BA_DEF_DEF_REL_  "GenSigTimeoutTime" 0;
BA_DEF_DEF_  "DiagRequest" "No";
BA_DEF_DEF_  "DiagResponse" "No";
BA_DEF_DEF_  "DiagState" "No";
BA_DEF_DEF_  "GenMsgChkConstant" 0;
BA_DEF_DEF_  "GenMsgCycleTime" 0;
BA_DEF_DEF_  "GenMsgCycleTimeFast" 0;
BA_DEF_DEF_  "GenMsgDelayTime" 0;
BA_DEF_DEF_  "GenMsgILSupport" "No";
BA_DEF_DEF_  "GenMsgNrOfRepetition" 0;
BA_DEF_DEF_  "GenMsgPDUConstants" "";
BA_DEF_DEF_  "GenMsgSendType" "NoMsgSendType";
BA_DEF_DEF_  "GenMsgStartDelayTime" 0;
BA_DEF_DEF_  "NmMessage" "No";
BA_DEF_DEF_  "NmhMessage" "No";
BA_DEF_DEF_  "MsgType" "Application";
BA_DEF_DEF_  "VAGTP20_API" 0;
BA_DEF_DEF_  "VAGTP20_DynConnection" "No";
BA_DEF_DEF_  "VAGTP20_DynSetup" "No";
BA_DEF_DEF_  "VAGTP20_StatConnection" "No";
BA_DEF_DEF_  "GenSigActiveRepetitions" 0;
BA_DEF_DEF_  "GenSigInactiveValue" 0;
BA_DEF_DEF_  "GenSigSendType" "NoSigSendType";
BA_DEF_DEF_  "GenSigStartValue" 0;
BA_DEF_DEF_  "NWM-WakeupAllowed" "No";
BA_DEF_DEF_  "GenSigFuncType" "NoFunction";
BA_DEF_DEF_  "GenSigSwitchedByIgnition" "Yes";
BA_DEF_DEF_  "Fehlerwert" 0;
BA_DEF_DEF_  "GenSigMissingSourceValue" 0;
BA_ "GenMsgCycleTime" BO_ 795 50;
BA_ "GenMsgILSupport" BO_ 795 1;
BA_ "GenMsgPDUConstants" BO_ 795 "0x67,0x8a,0xae,0x22,0x4d,0xd0,0x51,0x80,0x5c,0xb9,0xce,0x1e,0xdf,0x02,0x2d,0xd4";
BA_ "GenMsgSendType" BO_ 795 0;
BA_ "GenMsgCycleTime" BO_ 2589283617 1000;
BA_ "GenMsgDelayTime" BO_ 2589283617 200;
BA_ "GenMsgILSupport" BO_ 2589283617 1;
BA_ "GenMsgSendType" BO_ 2589283617 0;
BA_ "GenMsgCycleTime" BO_ 427 200;
BA_ "GenMsgDelayTime" BO_ 427 20;
BA_ "GenMsgILSupport" BO_ 427 1;
BA_ "GenMsgPDUConstants" BO_ 427 "0x13,0x21,0x9b,0x6a,0x9a,0x62,0xd4,0x65,0x18,0xf1,0xab,0x16,0x32,0x89,0xe7,0x26";
BA_ "GenMsgSendType" BO_ 427 0;
BA_ "GenMsgCycleTime" BO_ 87 5;
BA_ "GenMsgILSupport" BO_ 87 1;
BA_ "GenMsgPDUConstants" BO_ 87 "0xd4,0x37,0x91,0x7d,0x5f,0xf3,0xbc,0xa9,0xd2,0x18,0x96,0x46,0xf8,0x6d,0xf5,0x4d";
BA_ "GenMsgSendType" BO_ 87 0;
BA_ "GenMsgCycleTime" BO_ 382 100;
BA_ "GenMsgCycleTimeFast" BO_ 382 10;
BA_ "GenMsgILSupport" BO_ 382 1;
BA_ "GenMsgNrOfRepetition" BO_ 382 5;
BA_ "GenMsgPDUConstants" BO_ 382 "0x1b,0x0a,0x35,0x1f,0x60,0x15,0xe5,0x2e,0x2a,0x53,0x5f,0xb8,0x0c,0xc9,0x4e,0x26";
BA_ "GenMsgSendType" BO_ 382 0;
BA_ "GenMsgChkConstant" BO_ 264 9;
BA_ "GenMsgCycleTime" BO_ 264 25;
BA_ "GenMsgILSupport" BO_ 264 1;
BA_ "GenMsgPDUConstants" BO_ 264 "0x09,0x09,0x09,0x09,0x09,0x09,0x09,0x09,0x09,0x09,0x09,0x09,0x09,0x09,0x09,0x09";
BA_ "GenMsgSendType" BO_ 264 0;
BA_ "GenMsgCycleTime" BO_ 314 20;
BA_ "GenMsgILSupport" BO_ 314 1;
BA_ "GenMsgPDUConstants" BO_ 314 "0xb4,0x24,0x5a,0x8b,0xaa,0xb6,0xd5,0x97,0xb9,0x82,0x3d,0x96,0x7d,0x5d,0x64,0x9b";
BA_ "GenMsgSendType" BO_ 314 0;
BA_ "GenMsgCycleTime" BO_ 987 100;
BA_ "GenMsgDelayTime" BO_ 987 10;
BA_ "GenMsgILSupport" BO_ 987 1;
BA_ "GenMsgSendType" BO_ 987 0;
BA_ "GenMsgCycleTime" BO_ 1004 200;
BA_ "GenMsgDelayTime" BO_ 1004 20;
BA_ "GenMsgILSupport" BO_ 1004 1;
BA_ "GenMsgSendType" BO_ 1004 0;
BA_ "GenMsgCycleTime" BO_ 173 50;
BA_ "GenMsgILSupport" BO_ 173 1;
BA_ "GenMsgPDUConstants" BO_ 173 "0x3f,0x69,0x39,0xdc,0x94,0xf9,0x14,0x64,0xd8,0x6a,0x34,0xce,0xa2,0x55,0xb5,0x2c";
BA_ "GenMsgSendType" BO_ 173 0;
BA_ "GenMsgCycleTime" BO_ 968 100;
BA_ "GenMsgDelayTime" BO_ 968 10;
BA_ "GenMsgILSupport" BO_ 968 1;
BA_ "GenMsgSendType" BO_ 968 0;
BA_ "GenMsgChkConstant" BO_ 294 218;
BA_ "GenMsgCycleTime" BO_ 294 1000;
BA_ "GenMsgCycleTimeFast" BO_ 294 20;
BA_ "GenMsgILSupport" BO_ 294 1;
BA_ "GenMsgPDUConstants" BO_ 294 "0xda,0xda,0xda,0xda,0xda,0xda,0xda,0xda,0xda,0xda,0xda,0xda,0xda,0xda,0xda,0xda";
BA_ "GenMsgSendType" BO_ 294 0;
BA_ "GenMsgChkConstant" BO_ 1412 127;
BA_ "GenMsgCycleTime" BO_ 1412 200;
BA_ "GenMsgILSupport" BO_ 1412 1;
BA_ "GenMsgPDUConstants" BO_ 1412 "0x7f,0x7f,0x7f,0x7f,0x7f,0x7f,0x7f,0x7f,0x7f,0x7f,0x7f,0x7f,0x7f,0x7f,0x7f,0x7f";
BA_ "GenMsgSendType" BO_ 1412 0;
BA_ "DiagRequest" BO_ 1811 1;
BA_ "MsgType" BO_ 1811 4;
BA_ "DiagResponse" BO_ 1917 1;
BA_ "MsgType" BO_ 1917 4;
BA_ "DiagRequest" BO_ 1807 1;
BA_ "MsgType" BO_ 1807 4;
BA_ "DiagResponse" BO_ 1913 1;
BA_ "MsgType" BO_ 1913 4;
BA_ "DiagRequest" BO_ 1906 1;
BA_ "MsgType" BO_ 1906 4;
BA_ "DiagResponse" BO_ 2012 1;
BA_ "MsgType" BO_ 2012 4;
BA_ "DiagRequest" BO_ 1802 1;
BA_ "MsgType" BO_ 1802 4;
BA_ "DiagResponse" BO_ 1908 1;
BA_ "MsgType" BO_ 1908 4;
BA_ "DiagState" BO_ 1793 1;
BA_ "MsgType" BO_ 1793 4;
BA_ "DiagState" BO_ 1794 1;
BA_ "MsgType" BO_ 1794 4;
BA_ "DiagState" BO_ 1796 1;
BA_ "MsgType" BO_ 1796 4;
BA_ "DiagState" BO_ 1797 1;
BA_ "MsgType" BO_ 1797 4;
BA_ "DiagState" BO_ 1798 1;
BA_ "MsgType" BO_ 1798 4;
BA_ "DiagState" BO_ 1799 1;
BA_ "MsgType" BO_ 1799 4;
BA_ "DiagState" BO_ 1800 1;
BA_ "MsgType" BO_ 1800 4;
BA_ "DiagState" BO_ 1801 1;
BA_ "MsgType" BO_ 1801 4;
BA_ "DiagState" BO_ 1795 1;
BA_ "MsgType" BO_ 1795 4;
BA_ "DiagState" BO_ 1792 1;
BA_ "MsgType" BO_ 1792 4;
BA_ "DiagState" BO_ 2015 1;
BA_ "MsgType" BO_ 2015 4;
BA_ "DiagRequest" BO_ 1810 1;
BA_ "MsgType" BO_ 1810 4;
BA_ "DiagResponse" BO_ 1916 1;
BA_ "MsgType" BO_ 1916 4;
BA_ "DiagRequest" BO_ 2020 1;
BA_ "MsgType" BO_ 2020 4;
BA_ "DiagResponse" BO_ 2028 1;
BA_ "MsgType" BO_ 2028 4;
BA_ "DiagRequest" BO_ 1897 1;
BA_ "MsgType" BO_ 1897 4;
BA_ "DiagResponse" BO_ 2003 1;
BA_ "MsgType" BO_ 2003 4;
BA_ "GenMsgChkConstant" BO_ 960 195;
BA_ "GenMsgCycleTime" BO_ 960 100;
BA_ "GenMsgDelayTime" BO_ 960 10;
BA_ "GenMsgILSupport" BO_ 960 1;
BA_ "GenMsgPDUConstants" BO_ 960 "0xc3,0xc3,0xc3,0xc3,0xc3,0xc3,0xc3,0xc3,0xc3,0xc3,0xc3,0xc3,0xc3,0xc3,0xc3,0xc3";
BA_ "GenMsgSendType" BO_ 960 0;
BA_ "GenMsgCycleTime" BO_ 1640 200;
BA_ "GenMsgCycleTimeFast" BO_ 1640 100;
BA_ "GenMsgDelayTime" BO_ 1640 50;
BA_ "GenMsgILSupport" BO_ 1640 1;
BA_ "GenMsgNrOfRepetition" BO_ 1640 5;
BA_ "GenMsgSendType" BO_ 1640 0;
BA_ "GenMsgCycleTime" BO_ 2549088275 500;
BA_ "GenMsgILSupport" BO_ 2549088275 1;
BA_ "GenMsgSendType" BO_ 2549088275 0;
BA_ "GenMsgCycleTime" BO_ 2549088271 500;
BA_ "GenMsgILSupport" BO_ 2549088271 1;
BA_ "GenMsgSendType" BO_ 2549088271 0;
BA_ "GenMsgCycleTime" BO_ 2549088370 500;
BA_ "GenMsgILSupport" BO_ 2549088370 1;
BA_ "GenMsgSendType" BO_ 2549088370 0;
BA_ "GenMsgCycleTime" BO_ 2549088266 500;
BA_ "GenMsgILSupport" BO_ 2549088266 1;
BA_ "GenMsgSendType" BO_ 2549088266 0;
BA_ "GenMsgCycleTime" BO_ 2549088274 500;
BA_ "GenMsgILSupport" BO_ 2549088274 1;
BA_ "GenMsgSendType" BO_ 2549088274 0;
BA_ "GenMsgCycleTime" BO_ 2549088361 500;
BA_ "GenMsgILSupport" BO_ 2549088361 1;
BA_ "GenMsgSendType" BO_ 2549088361 0;
BA_ "GenSigSendType" SG_ 795 ABS_Lampe 0;
BA_ "GenSigStartValue" SG_ 795 ABS_Lampe 1;
BA_ "GenSigSwitchedByIgnition" SG_ 795 ABS_Lampe 0;
BA_ "GenSigSendType" SG_ 795 BK_Lampe_02 0;
BA_ "GenSigStartValue" SG_ 795 BK_Lampe_02 1;
BA_ "GenSigSwitchedByIgnition" SG_ 795 BK_Lampe_02 0;
BA_ "GenSigSendType" SG_ 795 ESP_24_BZ 0;
BA_ "GenSigFuncType" SG_ 795 ESP_24_BZ 1;
BA_ "GenSigSwitchedByIgnition" SG_ 795 ESP_24_BZ 0;
BA_ "GenSigSendType" SG_ 795 ESP_24_CRC 0;
BA_ "GenSigFuncType" SG_ 795 ESP_24_CRC 2;
BA_ "GenSigSwitchedByIgnition" SG_ 795 ESP_24_CRC 0;
BA_ "GenSigSendType" SG_ 795 ESP_BKV_Warnung 0;
BA_ "GenSigSwitchedByIgnition" SG_ 795 ESP_BKV_Warnung 0;
BA_ "GenSigSendType" SG_ 795 ESP_Fehlerstatus_Wegimp 0;
BA_ "GenSigSwitchedByIgnition" SG_ 795 ESP_Fehlerstatus_Wegimp 0;
BA_ "GenSigSendType" SG_ 795 ESP_HDC_FktLampe 0;
BA_ "GenSigSwitchedByIgnition" SG_ 795 ESP_HDC_FktLampe 0;
BA_ "GenSigSendType" SG_ 795 ESP_HDC_Regelgeschw 0;
BA_ "GenSigStartValue" SG_ 795 ESP_HDC_Regelgeschw 126;
BA_ "GenSigSwitchedByIgnition" SG_ 795 ESP_HDC_Regelgeschw 0;
BA_ "Fehlerwert" SG_ 795 ESP_HDC_Regelgeschw 127;
BA_ "GenSigSendType" SG_ 795 ESP_Lampe 0;
BA_ "GenSigStartValue" SG_ 795 ESP_Lampe 1;
BA_ "GenSigSwitchedByIgnition" SG_ 795 ESP_Lampe 0;
BA_ "GenSigSendType" SG_ 795 ESP_m_Raddrehz 0;
BA_ "GenSigStartValue" SG_ 795 ESP_m_Raddrehz 32766;
BA_ "GenSigSwitchedByIgnition" SG_ 795 ESP_m_Raddrehz 0;
BA_ "Fehlerwert" SG_ 795 ESP_m_Raddrehz 32767;
BA_ "GenSigSendType" SG_ 795 ESP_Meldungen 0;
BA_ "GenSigSwitchedByIgnition" SG_ 795 ESP_Meldungen 0;
BA_ "GenSigSendType" SG_ 795 ESP_Off_Lampe 0;
BA_ "GenSigSwitchedByIgnition" SG_ 795 ESP_Off_Lampe 0;
BA_ "GenSigSendType" SG_ 795 ESP_QBit_Wegimp_VA 0;
BA_ "GenSigStartValue" SG_ 795 ESP_QBit_Wegimp_VA 1;
BA_ "GenSigSwitchedByIgnition" SG_ 795 ESP_QBit_Wegimp_VA 0;
BA_ "GenSigSendType" SG_ 795 ESP_Textanzeigen_03 0;
BA_ "GenSigSwitchedByIgnition" SG_ 795 ESP_Textanzeigen_03 0;
BA_ "GenSigSendType" SG_ 795 ESP_Wegimp_Ueberlauf 0;
BA_ "GenSigSwitchedByIgnition" SG_ 795 ESP_Wegimp_Ueberlauf 0;
BA_ "GenSigSendType" SG_ 795 ESP_Wegimp_VA 0;
BA_ "GenSigSwitchedByIgnition" SG_ 795 ESP_Wegimp_VA 0;
BA_ "GenSigSendType" SG_ 795 TC_Lampe 0;
BA_ "GenSigSwitchedByIgnition" SG_ 795 TC_Lampe 0;
BA_ "GenSigSendType" SG_ 2589283617 EDS_Charisma_FahrPr 3;
BA_ "GenSigSwitchedByIgnition" SG_ 2589283617 EDS_Charisma_FahrPr 0;
BA_ "GenSigSendType" SG_ 2589283617 EDS_Charisma_Status 3;
BA_ "GenSigSwitchedByIgnition" SG_ 2589283617 EDS_Charisma_Status 0;
BA_ "GenSigSendType" SG_ 2589283617 HHC_Charisma_FahrPr 3;
BA_ "GenSigSwitchedByIgnition" SG_ 2589283617 HHC_Charisma_FahrPr 0;
BA_ "GenSigSendType" SG_ 2589283617 HHC_Charisma_Status 3;
BA_ "GenSigSwitchedByIgnition" SG_ 2589283617 HHC_Charisma_Status 0;
BA_ "GenSigSendType" SG_ 2589283617 RLE_Anzeigen 0;
BA_ "GenSigSwitchedByIgnition" SG_ 2589283617 RLE_Anzeigen 0;
BA_ "GenSigSendType" SG_ 427 ESC_AHW_aktiv 3;
BA_ "GenSigSwitchedByIgnition" SG_ 427 ESC_AHW_aktiv 0;
BA_ "GenSigSendType" SG_ 427 ESC_AHW_nicht_verfuegbar 3;
BA_ "GenSigSwitchedByIgnition" SG_ 427 ESC_AHW_nicht_verfuegbar 0;
BA_ "GenSigSendType" SG_ 427 ESC_ANB_CM_aktiv 3;
BA_ "GenSigSwitchedByIgnition" SG_ 427 ESC_ANB_CM_aktiv 0;
BA_ "GenSigSendType" SG_ 427 ESC_ANB_CM_nicht_verfuegbar 3;
BA_ "GenSigSwitchedByIgnition" SG_ 427 ESC_ANB_CM_nicht_verfuegbar 0;
BA_ "GenSigSendType" SG_ 427 ESC_Bremslicht_unplausibel 3;
BA_ "GenSigSwitchedByIgnition" SG_ 427 ESC_Bremslicht_unplausibel 0;
BA_ "GenSigSendType" SG_ 427 ESC_Fahrer_Bremsdruck_bestimmend 3;
BA_ "GenSigSwitchedByIgnition" SG_ 427 ESC_Fahrer_Bremsdruck_bestimmend 0;
BA_ "GenSigSendType" SG_ 427 ESC_HBA_aktiv 3;
BA_ "GenSigSwitchedByIgnition" SG_ 427 ESC_HBA_aktiv 0;
BA_ "GenSigSendType" SG_ 427 ESC_HBA_nicht_verfuegbar 3;
BA_ "GenSigSwitchedByIgnition" SG_ 427 ESC_HBA_nicht_verfuegbar 0;
BA_ "GenSigSendType" SG_ 427 ESC_Konsistenz_ACC 3;
BA_ "GenSigSwitchedByIgnition" SG_ 427 ESC_Konsistenz_ACC 0;
BA_ "GenSigSendType" SG_ 427 ESC_Konsistenz_AGW 3;
BA_ "GenSigSwitchedByIgnition" SG_ 427 ESC_Konsistenz_AGW 0;
BA_ "GenSigSendType" SG_ 427 ESC_Konsistenz_ARA 3;
BA_ "GenSigSwitchedByIgnition" SG_ 427 ESC_Konsistenz_ARA 0;
BA_ "GenSigSendType" SG_ 427 ESC_Konsistenz_AWA 3;
BA_ "GenSigSwitchedByIgnition" SG_ 427 ESC_Konsistenz_AWA 0;
BA_ "GenSigSendType" SG_ 427 ESC_Konsistenz_AWV 3;
BA_ "GenSigSwitchedByIgnition" SG_ 427 ESC_Konsistenz_AWV 0;
BA_ "GenSigSendType" SG_ 427 ESC_Konsistenz_BFF 3;
BA_ "GenSigSwitchedByIgnition" SG_ 427 ESC_Konsistenz_BFF 0;
BA_ "GenSigSendType" SG_ 427 ESC_Konsistenz_EA 3;
BA_ "GenSigSwitchedByIgnition" SG_ 427 ESC_Konsistenz_EA 0;
BA_ "GenSigSendType" SG_ 427 ESC_Konsistenz_FAS_VK 3;
BA_ "GenSigSwitchedByIgnition" SG_ 427 ESC_Konsistenz_FAS_VK 0;
BA_ "GenSigSendType" SG_ 427 ESC_Konsistenz_FCW 3;
BA_ "GenSigSwitchedByIgnition" SG_ 427 ESC_Konsistenz_FCW 0;
BA_ "GenSigSendType" SG_ 427 ESC_Konsistenz_IPA 3;
BA_ "GenSigSwitchedByIgnition" SG_ 427 ESC_Konsistenz_IPA 0;
BA_ "GenSigSendType" SG_ 427 ESC_Konsistenz_KAS 3;
BA_ "GenSigSwitchedByIgnition" SG_ 427 ESC_Konsistenz_KAS 0;
BA_ "GenSigSendType" SG_ 427 ESC_Konsistenz_MKB 3;
BA_ "GenSigSwitchedByIgnition" SG_ 427 ESC_Konsistenz_MKB 0;
BA_ "GenSigSendType" SG_ 427 ESC_Konsistenz_NV 3;
BA_ "GenSigSwitchedByIgnition" SG_ 427 ESC_Konsistenz_NV 0;
BA_ "GenSigSendType" SG_ 427 ESC_Konsistenz_PCF 3;
BA_ "GenSigSwitchedByIgnition" SG_ 427 ESC_Konsistenz_PCF 0;
BA_ "GenSigSendType" SG_ 427 ESC_Konsistenz_RCTA 3;
BA_ "GenSigSwitchedByIgnition" SG_ 427 ESC_Konsistenz_RCTA 0;
BA_ "GenSigSendType" SG_ 427 ESC_Konsistenz_STA 3;
BA_ "GenSigSwitchedByIgnition" SG_ 427 ESC_Konsistenz_STA 0;
BA_ "GenSigSendType" SG_ 427 ESC_Konsistenz_TSK 3;
BA_ "GenSigSwitchedByIgnition" SG_ 427 ESC_Konsistenz_TSK 0;
BA_ "GenSigSendType" SG_ 427 ESC_Konsistenz_vFGS 3;
BA_ "GenSigSwitchedByIgnition" SG_ 427 ESC_Konsistenz_vFGS 0;
BA_ "GenSigSendType" SG_ 427 ESC_Prefill_aktiv 3;
BA_ "GenSigSwitchedByIgnition" SG_ 427 ESC_Prefill_aktiv 0;
BA_ "GenSigSendType" SG_ 427 ESC_Prefill_nicht_verfuegbar 3;
BA_ "GenSigSwitchedByIgnition" SG_ 427 ESC_Prefill_nicht_verfuegbar 0;
BA_ "GenSigSendType" SG_ 427 ESC_Pumpenanlauf_aktiv 3;
BA_ "GenSigSwitchedByIgnition" SG_ 427 ESC_Pumpenanlauf_aktiv 0;
BA_ "GenSigSendType" SG_ 427 ESC_TSK_SRBM_Anf 3;
BA_ "GenSigSwitchedByIgnition" SG_ 427 ESC_TSK_SRBM_Anf 0;
BA_ "GenSigSendType" SG_ 427 ESC_TSK_SRBM_nicht_verfuegbar 3;
BA_ "GenSigSwitchedByIgnition" SG_ 427 ESC_TSK_SRBM_nicht_verfuegbar 0;
BA_ "GenSigSendType" SG_ 427 ESC_Verz_ASIL_Verfuegbarkeit 3;
BA_ "GenSigSwitchedByIgnition" SG_ 427 ESC_Verz_ASIL_Verfuegbarkeit 0;
BA_ "GenSigSendType" SG_ 427 ESC_Verz_Begrenzung 3;
BA_ "GenSigSwitchedByIgnition" SG_ 427 ESC_Verz_Begrenzung 0;
BA_ "GenSigSendType" SG_ 427 ESC_Verz_Reg_aktiv 3;
BA_ "GenSigSwitchedByIgnition" SG_ 427 ESC_Verz_Reg_aktiv 0;
BA_ "GenSigSendType" SG_ 427 ESC_Verz_Reg_nicht_verfuegbar 3;
BA_ "GenSigSwitchedByIgnition" SG_ 427 ESC_Verz_Reg_nicht_verfuegbar 0;
BA_ "GenSigSendType" SG_ 427 ESC_Verz_Reg_TB_nicht_verfuegbar 3;
BA_ "GenSigSwitchedByIgnition" SG_ 427 ESC_Verz_Reg_TB_nicht_verfuegbar 0;
BA_ "GenSigSendType" SG_ 427 ESC_Verz_Reg_ZB_nicht_verfuegbar 3;
BA_ "GenSigSwitchedByIgnition" SG_ 427 ESC_Verz_Reg_ZB_nicht_verfuegbar 0;
BA_ "GenSigSendType" SG_ 427 ESC_Warnruck_aktiv 3;
BA_ "GenSigSwitchedByIgnition" SG_ 427 ESC_Warnruck_aktiv 0;
BA_ "GenSigSendType" SG_ 427 ESC_Warnruck_nicht_verfuegbar 3;
BA_ "GenSigSwitchedByIgnition" SG_ 427 ESC_Warnruck_nicht_verfuegbar 0;
BA_ "GenSigSendType" SG_ 427 ESP_33_BZ 0;
BA_ "GenSigFuncType" SG_ 427 ESP_33_BZ 1;
BA_ "GenSigSwitchedByIgnition" SG_ 427 ESP_33_BZ 0;
BA_ "GenSigSendType" SG_ 427 ESP_33_CRC 0;
BA_ "GenSigFuncType" SG_ 427 ESP_33_CRC 2;
BA_ "GenSigSwitchedByIgnition" SG_ 427 ESP_33_CRC 0;
BA_ "GenSigSendType" SG_ 87 BR_mi_Raddrehz 0;
BA_ "GenSigStartValue" SG_ 87 BR_mi_Raddrehz 65534;
BA_ "GenSigSwitchedByIgnition" SG_ 87 BR_mi_Raddrehz 0;
BA_ "Fehlerwert" SG_ 87 BR_mi_Raddrehz 65535;
BA_ "GenSigSendType" SG_ 87 ESP_36_BZ 0;
BA_ "GenSigFuncType" SG_ 87 ESP_36_BZ 1;
BA_ "GenSigSwitchedByIgnition" SG_ 87 ESP_36_BZ 0;
BA_ "GenSigSendType" SG_ 87 ESP_36_CRC 0;
BA_ "GenSigFuncType" SG_ 87 ESP_36_CRC 2;
BA_ "GenSigSwitchedByIgnition" SG_ 87 ESP_36_CRC 0;
BA_ "GenSigSendType" SG_ 382 ESC_soll_Druck_EBKV 0;
BA_ "GenSigStartValue" SG_ 382 ESC_soll_Druck_EBKV 100;
BA_ "GenSigSwitchedByIgnition" SG_ 382 ESC_soll_Druck_EBKV 0;
BA_ "Fehlerwert" SG_ 382 ESC_soll_Druck_EBKV 1023;
BA_ "GenSigSendType" SG_ 382 ESC_soll_Druck_EBKV_Freigabe 0;
BA_ "GenSigSwitchedByIgnition" SG_ 382 ESC_soll_Druck_EBKV_Freigabe 0;
BA_ "GenSigSendType" SG_ 382 ESP_38_BZ 0;
BA_ "GenSigFuncType" SG_ 382 ESP_38_BZ 1;
BA_ "GenSigSwitchedByIgnition" SG_ 382 ESP_38_BZ 0;
BA_ "GenSigSendType" SG_ 382 ESP_38_CRC 0;
BA_ "GenSigFuncType" SG_ 382 ESP_38_CRC 2;
BA_ "GenSigSwitchedByIgnition" SG_ 382 ESP_38_CRC 0;
BA_ "GenSigSendType" SG_ 382 ESP_38_Sendestatus 6;
BA_ "GenSigSwitchedByIgnition" SG_ 382 ESP_38_Sendestatus 0;
BA_ "GenSigSendType" SG_ 264 FA_ESP_Zuschaltung 0;
BA_ "GenSigStartValue" SG_ 264 FA_Hoehenwert_HL_00 254;
BA_ "Fehlerwert" SG_ 264 FA_Hoehenwert_HL_00 255;
BA_ "GenSigStartValue" SG_ 264 FA_Hoehenwert_HL_01 254;
BA_ "Fehlerwert" SG_ 264 FA_Hoehenwert_HL_01 255;
BA_ "GenSigStartValue" SG_ 264 FA_Hoehenwert_HR_00 254;
BA_ "Fehlerwert" SG_ 264 FA_Hoehenwert_HR_00 255;
BA_ "GenSigStartValue" SG_ 264 FA_Hoehenwert_HR_01 254;
BA_ "Fehlerwert" SG_ 264 FA_Hoehenwert_HR_01 255;
BA_ "GenSigStartValue" SG_ 264 FA_Hoehenwert_VL_00 254;
BA_ "Fehlerwert" SG_ 264 FA_Hoehenwert_VL_00 255;
BA_ "GenSigStartValue" SG_ 264 FA_Hoehenwert_VL_01 254;
BA_ "Fehlerwert" SG_ 264 FA_Hoehenwert_VL_01 255;
BA_ "GenSigStartValue" SG_ 264 FA_Hoehenwert_VR_00 254;
BA_ "Fehlerwert" SG_ 264 FA_Hoehenwert_VR_00 255;
BA_ "GenSigStartValue" SG_ 264 FA_Hoehenwert_VR_01 254;
BA_ "Fehlerwert" SG_ 264 FA_Hoehenwert_VR_01 255;
BA_ "GenSigSendType" SG_ 264 FA_Hoehenwerte_kalibriert 0;
BA_ "GenSigSendType" SG_ 264 Fahrwerk_01_BZ 0;
BA_ "GenSigFuncType" SG_ 264 Fahrwerk_01_BZ 1;
BA_ "GenSigSendType" SG_ 264 Fahrwerk_01_CRC 0;
BA_ "GenSigFuncType" SG_ 264 Fahrwerk_01_CRC 2;
BA_ "GenSigSendType" SG_ 314 FCW_02_BZ 0;
BA_ "GenSigFuncType" SG_ 314 FCW_02_BZ 1;
BA_ "GenSigSendType" SG_ 314 FCW_02_CRC 0;
BA_ "GenSigFuncType" SG_ 314 FCW_02_CRC 2;
BA_ "GenSigSendType" SG_ 314 FCWO_Anf_Prefill 0;
BA_ "GenSigSendType" SG_ 314 FCWO_HBA_Param 0;
BA_ "GenSigSendType" SG_ 314 FCWO_Ruck_Freigabe 0;
BA_ "GenSigSendType" SG_ 314 FCWO_Ruckprofil 0;
BA_ "GenSigSendType" SG_ 314 FCWP_Anf_Prefill 0;
BA_ "GenSigSendType" SG_ 314 FCWP_HBA_Param 0;
BA_ "GenSigSendType" SG_ 314 FCWP_Ruck_Freigabe 0;
BA_ "GenSigSendType" SG_ 314 FCWP_Ruckprofil 0;
BA_ "GenSigSendType" SG_ 987 AAG_Anhaenger_abgesteckt 0;
BA_ "GenSigSwitchedByIgnition" SG_ 987 AAG_Anhaenger_abgesteckt 0;
BA_ "GenSigSendType" SG_ 987 AAG_Anhaenger_erkannt 0;
BA_ "NWM-WakeupAllowed" SG_ 987 AAG_Anhaenger_erkannt 1;
BA_ "GenSigSwitchedByIgnition" SG_ 987 AAG_Anhaenger_erkannt 0;
BA_ "GenSigSendType" SG_ 987 AAG_LED_aktiv 0;
BA_ "GenSigSwitchedByIgnition" SG_ 987 AAG_LED_aktiv 0;
BA_ "GenSigSendType" SG_ 987 Anhaenger_01_alt 0;
BA_ "GenSigStartValue" SG_ 987 Anhaenger_01_alt 1;
BA_ "GenSigFuncType" SG_ 987 Anhaenger_01_alt 5;
BA_ "GenSigSwitchedByIgnition" SG_ 987 Anhaenger_01_alt 0;
BA_ "GenSigSendType" SG_ 987 BCM1_Aussen_Temp_ungef 0;
BA_ "GenSigStartValue" SG_ 987 BCM1_Aussen_Temp_ungef 254;
BA_ "GenSigSwitchedByIgnition" SG_ 987 BCM1_Aussen_Temp_ungef 0;
BA_ "Fehlerwert" SG_ 987 BCM1_Aussen_Temp_ungef 255;
BA_ "GenSigSendType" SG_ 987 BCM1_LDS_Stellung 3;
BA_ "GenSigSwitchedByIgnition" SG_ 987 BCM1_LDS_Stellung 0;
BA_ "Fehlerwert" SG_ 987 BCM1_LDS_Stellung 7;
BA_ "GenSigSendType" SG_ 987 BCM1_MH_Schalter 3;
BA_ "GenSigSwitchedByIgnition" SG_ 987 BCM1_MH_Schalter 0;
BA_ "GenSigSendType" SG_ 987 BCM1_OBD_FStatus_ATemp 0;
BA_ "GenSigSwitchedByIgnition" SG_ 987 BCM1_OBD_FStatus_ATemp 0;
BA_ "GenSigSendType" SG_ 987 BCM1_Rueckfahrlicht_Schalter 3;
BA_ "GenSigSwitchedByIgnition" SG_ 987 BCM1_Rueckfahrlicht_Schalter 0;
BA_ "GenSigSendType" SG_ 987 BCM_01_alt 0;
BA_ "GenSigStartValue" SG_ 987 BCM_01_alt 1;
BA_ "GenSigFuncType" SG_ 987 BCM_01_alt 5;
BA_ "GenSigSwitchedByIgnition" SG_ 987 BCM_01_alt 0;
BA_ "GenSigSendType" SG_ 987 BCM_Rueckfahrlicht_Anf 0;
BA_ "GenSigSwitchedByIgnition" SG_ 987 BCM_Rueckfahrlicht_Anf 0;
BA_ "GenSigSendType" SG_ 987 BCM_Tankklappensteller_Fehler 0;
BA_ "GenSigSwitchedByIgnition" SG_ 987 BCM_Tankklappensteller_Fehler 0;
BA_ "Fehlerwert" SG_ 987 BCM_Tankklappensteller_Fehler 1;
BA_ "GenSigSendType" SG_ 987 BH_Blinker_li 3;
BA_ "GenSigSwitchedByIgnition" SG_ 987 BH_Blinker_li 0;
BA_ "GenSigSendType" SG_ 987 BH_Blinker_re 3;
BA_ "GenSigSwitchedByIgnition" SG_ 987 BH_Blinker_re 0;
BA_ "GenSigSendType" SG_ 987 BH_Fernlicht 3;
BA_ "GenSigSwitchedByIgnition" SG_ 987 BH_Fernlicht 0;
BA_ "GenSigSendType" SG_ 987 BH_Lichthupe 3;
BA_ "GenSigSwitchedByIgnition" SG_ 987 BH_Lichthupe 0;
BA_ "GenSigSendType" SG_ 987 KL_Thermomanagement 0;
BA_ "GenSigSwitchedByIgnition" SG_ 987 KL_Thermomanagement 0;
BA_ "GenSigSendType" SG_ 987 Klima_11_alt 0;
BA_ "GenSigStartValue" SG_ 987 Klima_11_alt 1;
BA_ "GenSigFuncType" SG_ 987 Klima_11_alt 5;
BA_ "GenSigSwitchedByIgnition" SG_ 987 Klima_11_alt 0;
BA_ "GenSigSendType" SG_ 987 Klima_Sensor_02_alt 0;
BA_ "GenSigStartValue" SG_ 987 Klima_Sensor_02_alt 1;
BA_ "GenSigFuncType" SG_ 987 Klima_Sensor_02_alt 5;
BA_ "GenSigSwitchedByIgnition" SG_ 987 Klima_Sensor_02_alt 0;
BA_ "GenSigSendType" SG_ 987 Licht_Anf_01_alt 0;
BA_ "GenSigStartValue" SG_ 987 Licht_Anf_01_alt 1;
BA_ "GenSigFuncType" SG_ 987 Licht_Anf_01_alt 5;
BA_ "GenSigSwitchedByIgnition" SG_ 987 Licht_Anf_01_alt 0;
BA_ "GenSigSendType" SG_ 987 SMLS_01_alt 0;
BA_ "GenSigStartValue" SG_ 987 SMLS_01_alt 1;
BA_ "GenSigFuncType" SG_ 987 SMLS_01_alt 5;
BA_ "GenSigSwitchedByIgnition" SG_ 987 SMLS_01_alt 0;
BA_ "GenSigSendType" SG_ 987 Verdeck_01_alt 0;
BA_ "GenSigStartValue" SG_ 987 Verdeck_01_alt 1;
BA_ "GenSigFuncType" SG_ 987 Verdeck_01_alt 5;
BA_ "GenSigSwitchedByIgnition" SG_ 987 Verdeck_01_alt 0;
BA_ "GenSigSendType" SG_ 987 VS_VD_entriegelt 0;
BA_ "GenSigSwitchedByIgnition" SG_ 987 VS_VD_entriegelt 0;
BA_ "GenSigSendType" SG_ 987 VS_VD_offen_ver 0;
BA_ "GenSigSwitchedByIgnition" SG_ 987 VS_VD_offen_ver 0;
BA_ "GenSigSendType" SG_ 987 VS_VD_zu_ver 0;
BA_ "GenSigSwitchedByIgnition" SG_ 987 VS_VD_zu_ver 0;
BA_ "GenSigSendType" SG_ 987 VS_Verdeck_Anf 0;
BA_ "GenSigSwitchedByIgnition" SG_ 987 VS_Verdeck_Anf 0;
BA_ "GenSigSendType" SG_ 987 Waschen_vorne_aktiv 3;
BA_ "GenSigSwitchedByIgnition" SG_ 987 Waschen_vorne_aktiv 0;
BA_ "GenSigSendType" SG_ 987 WFS_01_alt 0;
BA_ "GenSigStartValue" SG_ 987 WFS_01_alt 1;
BA_ "GenSigFuncType" SG_ 987 WFS_01_alt 5;
BA_ "GenSigSwitchedByIgnition" SG_ 987 WFS_01_alt 0;
BA_ "GenSigSendType" SG_ 987 WFS_ID_Geb_autorisiert_in_Kl15 0;
BA_ "GenSigSwitchedByIgnition" SG_ 987 WFS_ID_Geb_autorisiert_in_Kl15 0;
BA_ "GenSigSendType" SG_ 987 WFS_Klemmenfreigabe 0;
BA_ "GenSigSwitchedByIgnition" SG_ 987 WFS_Klemmenfreigabe 0;
BA_ "GenSigSendType" SG_ 987 WFS_Schluessel_Fahrberecht 0;
BA_ "GenSigSwitchedByIgnition" SG_ 987 WFS_Schluessel_Fahrberecht 0;
BA_ "GenSigSendType" SG_ 987 Wischer_01_alt 0;
BA_ "GenSigStartValue" SG_ 987 Wischer_01_alt 1;
BA_ "GenSigFuncType" SG_ 987 Wischer_01_alt 5;
BA_ "GenSigSwitchedByIgnition" SG_ 987 Wischer_01_alt 0;
BA_ "GenSigSendType" SG_ 987 Wischer_vorne_aktiv 3;
BA_ "GenSigSwitchedByIgnition" SG_ 987 Wischer_vorne_aktiv 0;
BA_ "GenSigSendType" SG_ 987 WWSs_01_alt 3;
BA_ "GenSigStartValue" SG_ 987 WWSs_01_alt 1;
BA_ "GenSigFuncType" SG_ 987 WWSs_01_alt 5;
BA_ "GenSigSwitchedByIgnition" SG_ 987 WWSs_01_alt 0;
BA_ "GenSigSendType" SG_ 987 ZV_02_alt 0;
BA_ "GenSigStartValue" SG_ 987 ZV_02_alt 1;
BA_ "GenSigFuncType" SG_ 987 ZV_02_alt 5;
BA_ "GenSigSwitchedByIgnition" SG_ 987 ZV_02_alt 0;
BA_ "GenSigSendType" SG_ 987 ZV_BT_offen 3;
BA_ "GenSigSwitchedByIgnition" SG_ 987 ZV_BT_offen 0;
BA_ "GenSigSendType" SG_ 987 ZV_FT_offen 3;
BA_ "GenSigSwitchedByIgnition" SG_ 987 ZV_FT_offen 0;
BA_ "GenSigSendType" SG_ 987 ZV_HBFS_offen 3;
BA_ "GenSigSwitchedByIgnition" SG_ 987 ZV_HBFS_offen 0;
BA_ "GenSigSendType" SG_ 987 ZV_HD_offen 3;
BA_ "GenSigSwitchedByIgnition" SG_ 987 ZV_HD_offen 0;
BA_ "GenSigSendType" SG_ 987 ZV_HFS_offen 3;
BA_ "GenSigSwitchedByIgnition" SG_ 987 ZV_HFS_offen 0;
BA_ "GenSigSendType" SG_ 987 ZV_Schluessel_Zugang 0;
BA_ "GenSigSwitchedByIgnition" SG_ 987 ZV_Schluessel_Zugang 0;
BA_ "GenSigSendType" SG_ 987 ZV_Tankklappe_offen 0;
BA_ "GenSigSwitchedByIgnition" SG_ 987 ZV_Tankklappe_offen 0;
BA_ "GenSigSendType" SG_ 987 ZV_verriegelt_extern_soll 0;
BA_ "GenSigSwitchedByIgnition" SG_ 987 ZV_verriegelt_extern_soll 0;
BA_ "GenSigSendType" SG_ 987 ZV_verriegelt_soll 3;
BA_ "GenSigSwitchedByIgnition" SG_ 987 ZV_verriegelt_soll 0;
BA_ "GenSigSendType" SG_ 1004 ACC_02_alt 0;
BA_ "GenSigStartValue" SG_ 1004 ACC_02_alt 1;
BA_ "GenSigFuncType" SG_ 1004 ACC_02_alt 5;
BA_ "GenSigSwitchedByIgnition" SG_ 1004 ACC_02_alt 0;
BA_ "GenSigSendType" SG_ 1004 ACC_Status_Anzeige 3;
BA_ "GenSigSendType" SG_ 1004 GW_79_va_12 0;
BA_ "GenSigStartValue" SG_ 1004 GW_79_va_12 1;
BA_ "GenSigFuncType" SG_ 1004 GW_79_va_12 5;
BA_ "GenSigSwitchedByIgnition" SG_ 1004 GW_79_va_12 0;
BA_ "GenSigSendType" SG_ 1004 GW_79_va_16 0;
BA_ "GenSigStartValue" SG_ 1004 GW_79_va_16 1;
BA_ "GenSigFuncType" SG_ 1004 GW_79_va_16 5;
BA_ "GenSigSwitchedByIgnition" SG_ 1004 GW_79_va_16 0;
BA_ "GenSigSendType" SG_ 1004 GW_79_va_17 0;
BA_ "GenSigStartValue" SG_ 1004 GW_79_va_17 1;
BA_ "GenSigFuncType" SG_ 1004 GW_79_va_17 5;
BA_ "GenSigSwitchedByIgnition" SG_ 1004 GW_79_va_17 0;
BA_ "GenSigSendType" SG_ 1004 HC_Uss_Anforderung 3;
BA_ "GenSigSendType" SG_ 1004 HD_Endstellung_oben 3;
BA_ "GenSigSwitchedByIgnition" SG_ 1004 HD_Endstellung_oben 0;
BA_ "GenSigSendType" SG_ 1004 HD_Endstellung_unten 3;
BA_ "GenSigSwitchedByIgnition" SG_ 1004 HD_Endstellung_unten 0;
BA_ "GenSigSendType" SG_ 1004 HD_Position 3;
BA_ "GenSigSwitchedByIgnition" SG_ 1004 HD_Position 0;
BA_ "GenSigSendType" SG_ 1004 HDSG_01_alt 0;
BA_ "GenSigStartValue" SG_ 1004 HDSG_01_alt 1;
BA_ "GenSigFuncType" SG_ 1004 HDSG_01_alt 5;
BA_ "GenSigSwitchedByIgnition" SG_ 1004 HDSG_01_alt 0;
BA_ "GenSigSendType" SG_ 1004 KL_Vorwarn_Komp_ein 3;
BA_ "GenSigSwitchedByIgnition" SG_ 1004 KL_Vorwarn_Komp_ein 0;
BA_ "GenSigSendType" SG_ 1004 Klima_11_alt 0;
BA_ "GenSigStartValue" SG_ 1004 Klima_11_alt 1;
BA_ "GenSigFuncType" SG_ 1004 Klima_11_alt 5;
BA_ "GenSigSwitchedByIgnition" SG_ 1004 Klima_11_alt 0;
BA_ "GenSigSendType" SG_ 1004 LDW_02_alt 0;
BA_ "GenSigStartValue" SG_ 1004 LDW_02_alt 1;
BA_ "GenSigFuncType" SG_ 1004 LDW_02_alt 5;
BA_ "GenSigSwitchedByIgnition" SG_ 1004 LDW_02_alt 0;
BA_ "GenSigSendType" SG_ 1004 MO_NGS_Position 3;
BA_ "GenSigSwitchedByIgnition" SG_ 1004 MO_NGS_Position 0;
BA_ "GenSigSendType" SG_ 1004 MO_NGS_Status 3;
BA_ "GenSigSwitchedByIgnition" SG_ 1004 MO_NGS_Status 0;
BA_ "Fehlerwert" SG_ 1004 MO_NGS_Status 3;
BA_ "GenSigSendType" SG_ 1004 Motor_17_alt 0;
BA_ "GenSigStartValue" SG_ 1004 Motor_17_alt 1;
BA_ "GenSigFuncType" SG_ 1004 Motor_17_alt 5;
BA_ "GenSigSwitchedByIgnition" SG_ 1004 Motor_17_alt 0;
BA_ "GenSigSendType" SG_ 173 GE_Fahrstufe 0;
BA_ "GenSigStartValue" SG_ 173 GE_Fahrstufe 1;
BA_ "GenSigSwitchedByIgnition" SG_ 173 GE_Fahrstufe 0;
BA_ "Fehlerwert" SG_ 173 GE_Fahrstufe 15;
BA_ "GenSigSendType" SG_ 173 GE_Freig_MMom_Vorhalt 0;
BA_ "GenSigSwitchedByIgnition" SG_ 173 GE_Freig_MMom_Vorhalt 0;
BA_ "GenSigSendType" SG_ 173 GE_MMom_Soll_02 0;
BA_ "GenSigStartValue" SG_ 173 GE_MMom_Soll_02 1022;
BA_ "GenSigSwitchedByIgnition" SG_ 173 GE_MMom_Soll_02 0;
BA_ "Fehlerwert" SG_ 173 GE_MMom_Soll_02 1023;
BA_ "GenSigSendType" SG_ 173 GE_MMom_Status 0;
BA_ "GenSigSwitchedByIgnition" SG_ 173 GE_MMom_Status 0;
BA_ "GenSigSendType" SG_ 173 GE_MMom_Status_02 0;
BA_ "GenSigSwitchedByIgnition" SG_ 173 GE_MMom_Status_02 0;
BA_ "GenSigSendType" SG_ 173 GE_MMom_Vorhalt_02 0;
BA_ "GenSigStartValue" SG_ 173 GE_MMom_Vorhalt_02 1022;
BA_ "GenSigSwitchedByIgnition" SG_ 173 GE_MMom_Vorhalt_02 0;
BA_ "Fehlerwert" SG_ 173 GE_MMom_Vorhalt_02 1023;
BA_ "GenSigSendType" SG_ 173 GE_reserv_Fahrstufe 0;
BA_ "GenSigSwitchedByIgnition" SG_ 173 GE_reserv_Fahrstufe 0;
BA_ "GenSigSendType" SG_ 173 GE_Schaltablauf 0;
BA_ "GenSigSwitchedByIgnition" SG_ 173 GE_Schaltablauf 0;
BA_ "GenSigSendType" SG_ 173 GE_Status_Kraftschluss 0;
BA_ "GenSigSwitchedByIgnition" SG_ 173 GE_Status_Kraftschluss 0;
BA_ "GenSigSendType" SG_ 173 GE_Uefkt 0;
BA_ "GenSigSwitchedByIgnition" SG_ 173 GE_Uefkt 0;
BA_ "Fehlerwert" SG_ 173 GE_Uefkt 1023;
BA_ "GenSigSendType" SG_ 173 GE_Uefkt_unplausibel 0;
BA_ "GenSigSwitchedByIgnition" SG_ 173 GE_Uefkt_unplausibel 0;
BA_ "GenSigSendType" SG_ 173 GE_Verbot_Ausblendung 0;
BA_ "GenSigSwitchedByIgnition" SG_ 173 GE_Verbot_Ausblendung 0;
BA_ "GenSigSendType" SG_ 173 GE_Zielgang 0;
BA_ "GenSigSwitchedByIgnition" SG_ 173 GE_Zielgang 0;
BA_ "Fehlerwert" SG_ 173 GE_Zielgang 15;
BA_ "GenSigSendType" SG_ 173 Getriebe_11_BZ 0;
BA_ "GenSigFuncType" SG_ 173 Getriebe_11_BZ 1;
BA_ "GenSigSwitchedByIgnition" SG_ 173 Getriebe_11_BZ 0;
BA_ "GenSigSendType" SG_ 173 Getriebe_11_CRC 0;
BA_ "GenSigFuncType" SG_ 173 Getriebe_11_CRC 2;
BA_ "GenSigSwitchedByIgnition" SG_ 173 Getriebe_11_CRC 0;
BA_ "GenSigSendType" SG_ 968 Freilauf_Charisma_FahrPr 0;
BA_ "GenSigSwitchedByIgnition" SG_ 968 Freilauf_Charisma_FahrPr 0;
BA_ "GenSigSendType" SG_ 968 Freilauf_Charisma_Status 0;
BA_ "GenSigSwitchedByIgnition" SG_ 968 Freilauf_Charisma_Status 0;
BA_ "GenSigSendType" SG_ 968 GE_amax_moeglich 0;
BA_ "GenSigStartValue" SG_ 968 GE_amax_moeglich 84;
BA_ "GenSigSwitchedByIgnition" SG_ 968 GE_amax_moeglich 0;
BA_ "GenSigSendType" SG_ 968 GE_Charisma_FahrPr 0;
BA_ "GenSigSwitchedByIgnition" SG_ 968 GE_Charisma_FahrPr 0;
BA_ "GenSigSendType" SG_ 968 GE_Charisma_Status 0;
BA_ "GenSigSwitchedByIgnition" SG_ 968 GE_Charisma_Status 0;
BA_ "GenSigSendType" SG_ 968 GE_Codierung_MSG 0;
BA_ "GenSigSwitchedByIgnition" SG_ 968 GE_Codierung_MSG 0;
BA_ "GenSigSendType" SG_ 968 GE_Freigabe_Info_WFS 3;
BA_ "GenSigSwitchedByIgnition" SG_ 968 GE_Freigabe_Info_WFS 0;
BA_ "GenSigSendType" SG_ 968 GE_Freigabe_Verfallsinfo_WFS 3;
BA_ "GenSigSwitchedByIgnition" SG_ 968 GE_Freigabe_Verfallsinfo_WFS 0;
BA_ "GenSigSendType" SG_ 968 GE_Heizwunsch 0;
BA_ "GenSigStartValue" SG_ 968 GE_Heizwunsch 1;
BA_ "GenSigSwitchedByIgnition" SG_ 968 GE_Heizwunsch 0;
BA_ "GenSigSendType" SG_ 968 GE_LaunchControl 0;
BA_ "GenSigSwitchedByIgnition" SG_ 968 GE_LaunchControl 0;
BA_ "GenSigSendType" SG_ 968 GE_LFR_Adaption 0;
BA_ "GenSigSwitchedByIgnition" SG_ 968 GE_LFR_Adaption 0;
BA_ "GenSigSendType" SG_ 968 GE_OBD_AbsperrVent 0;
BA_ "GenSigSwitchedByIgnition" SG_ 968 GE_OBD_AbsperrVent 0;
BA_ "GenSigSendType" SG_ 968 GE_OBD_Status 0;
BA_ "GenSigSwitchedByIgnition" SG_ 968 GE_OBD_Status 0;
BA_ "GenSigSendType" SG_ 968 GE_Sperr_Info_WFS 3;
BA_ "GenSigSwitchedByIgnition" SG_ 968 GE_Sperr_Info_WFS 0;
BA_ "GenSigSendType" SG_ 968 GE_Sumpftemperatur 0;
BA_ "GenSigSwitchedByIgnition" SG_ 968 GE_Sumpftemperatur 0;
BA_ "Fehlerwert" SG_ 968 GE_Sumpftemperatur 255;
BA_ "GenSigSendType" SG_ 968 GE_Verlustmoment 0;
BA_ "GenSigSwitchedByIgnition" SG_ 968 GE_Verlustmoment 0;
BA_ "Fehlerwert" SG_ 968 GE_Verlustmoment 255;
BA_ "GenSigSendType" SG_ 968 GE_Zustand_Kuppltemp 0;
BA_ "GenSigSwitchedByIgnition" SG_ 968 GE_Zustand_Kuppltemp 0;
BA_ "GenSigSendType" SG_ 294 EA_ACC_Sollstatus 0;
BA_ "GenSigSendType" SG_ 294 EA_ACC_Wunschgeschwindigkeit 0;
BA_ "GenSigStartValue" SG_ 294 EA_ACC_Wunschgeschwindigkeit 1023;
BA_ "GenSigSendType" SG_ 294 EA_Ruckfreigabe 0;
BA_ "GenSigSendType" SG_ 294 EA_Ruckprofil 0;
BA_ "GenSigSendType" SG_ 294 HCA_01_BZ 0;
BA_ "GenSigFuncType" SG_ 294 HCA_01_BZ 1;
BA_ "GenSigSendType" SG_ 294 HCA_01_CRC 0;
BA_ "GenSigFuncType" SG_ 294 HCA_01_CRC 2;
BA_ "GenSigSendType" SG_ 294 HCA_01_LM_Offset 0;
BA_ "GenSigSendType" SG_ 294 HCA_01_LM_OffSign 0;
BA_ "GenSigSendType" SG_ 294 HCA_01_Sendestatus 5;
BA_ "GenSigSendType" SG_ 294 HCA_01_Status_HCA 0;
BA_ "GenSigSendType" SG_ 294 HCA_01_Vib_Amp 0;
BA_ "GenSigSendType" SG_ 294 HCA_01_Vib_Freq 0;
BA_ "GenSigSendType" SG_ 1412 HSP_01_BZ 0;
BA_ "GenSigFuncType" SG_ 1412 HSP_01_BZ 1;
BA_ "GenSigSwitchedByIgnition" SG_ 1412 HSP_01_BZ 0;
BA_ "GenSigSendType" SG_ 1412 HSP_01_CRC 0;
BA_ "GenSigFuncType" SG_ 1412 HSP_01_CRC 2;
BA_ "GenSigSwitchedByIgnition" SG_ 1412 HSP_01_CRC 0;
BA_ "GenSigSendType" SG_ 1412 HSP_Charisma_FahrPr 0;
BA_ "GenSigSwitchedByIgnition" SG_ 1412 HSP_Charisma_FahrPr 0;
BA_ "GenSigSendType" SG_ 1412 HSP_Charisma_Status 0;
BA_ "GenSigSwitchedByIgnition" SG_ 1412 HSP_Charisma_Status 0;
BA_ "GenSigSendType" SG_ 1412 HSP_Endlage_ausgefahren 0;
BA_ "GenSigSwitchedByIgnition" SG_ 1412 HSP_Endlage_ausgefahren 0;
BA_ "GenSigSendType" SG_ 1412 HSP_Endlage_eingefahren 0;
BA_ "GenSigSwitchedByIgnition" SG_ 1412 HSP_Endlage_eingefahren 0;
BA_ "GenSigSendType" SG_ 1412 HSP_Motor_def 0;
BA_ "GenSigSwitchedByIgnition" SG_ 1412 HSP_Motor_def 0;
BA_ "Fehlerwert" SG_ 1412 HSP_Motor_def 1;
BA_ "GenSigSendType" SG_ 1412 HSP_Taster_Error 0;
BA_ "GenSigSwitchedByIgnition" SG_ 1412 HSP_Taster_Error 0;
BA_ "GenSigSendType" SG_ 1412 HSP_Warnung_Text 0;
BA_ "GenSigSwitchedByIgnition" SG_ 1412 HSP_Warnung_Text 0;
BA_ "GenSigSendType" SG_ 1412 HSP_Warnung_Ton 0;
BA_ "GenSigSwitchedByIgnition" SG_ 1412 HSP_Warnung_Ton 0;
BA_ "GenSigSendType" SG_ 1811 ISO_ABS_Req_Data 3;
BA_ "GenSigFuncType" SG_ 1811 ISO_ABS_Req_Data 9;
BA_ "GenSigSwitchedByIgnition" SG_ 1811 ISO_ABS_Req_Data 0;
BA_ "GenSigSendType" SG_ 1917 ISO_ABS_Resp_Data 3;
BA_ "GenSigFuncType" SG_ 1917 ISO_ABS_Resp_Data 9;
BA_ "GenSigSwitchedByIgnition" SG_ 1917 ISO_ABS_Resp_Data 0;
BA_ "GenSigSendType" SG_ 1807 ISO_Allrad_Req_Data 3;
BA_ "GenSigFuncType" SG_ 1807 ISO_Allrad_Req_Data 9;
BA_ "GenSigSendType" SG_ 1913 ISO_Allrad_Resp_Data 3;
BA_ "GenSigFuncType" SG_ 1913 ISO_Allrad_Resp_Data 9;
BA_ "GenSigSendType" SG_ 1906 ISO_Daempfer_Req_Data 3;
BA_ "GenSigFuncType" SG_ 1906 ISO_Daempfer_Req_Data 9;
BA_ "GenSigSwitchedByIgnition" SG_ 1906 ISO_Daempfer_Req_Data 0;
BA_ "GenSigSendType" SG_ 2012 ISO_Daempfer_Resp_Data 3;
BA_ "GenSigFuncType" SG_ 2012 ISO_Daempfer_Resp_Data 9;
BA_ "GenSigSendType" SG_ 1802 ISO_EPH_Req_Data 3;
BA_ "GenSigFuncType" SG_ 1802 ISO_EPH_Req_Data 9;
BA_ "GenSigSwitchedByIgnition" SG_ 1802 ISO_EPH_Req_Data 0;
BA_ "GenSigSendType" SG_ 1908 ISO_EPH_Resp_Data 3;
BA_ "GenSigFuncType" SG_ 1908 ISO_EPH_Resp_Data 9;
BA_ "GenSigSendType" SG_ 1793 ISO_01_Req_Data 3;
BA_ "GenSigFuncType" SG_ 1793 ISO_01_Req_Data 9;
BA_ "GenSigSwitchedByIgnition" SG_ 1793 ISO_01_Req_Data 0;
BA_ "GenSigSendType" SG_ 1794 ISO_02_Req_Data 3;
BA_ "GenSigFuncType" SG_ 1794 ISO_02_Req_Data 9;
BA_ "GenSigSwitchedByIgnition" SG_ 1794 ISO_02_Req_Data 0;
BA_ "GenSigSendType" SG_ 1796 ISO_04_Req_Data 3;
BA_ "GenSigFuncType" SG_ 1796 ISO_04_Req_Data 9;
BA_ "GenSigSwitchedByIgnition" SG_ 1796 ISO_04_Req_Data 0;
BA_ "GenSigSendType" SG_ 1797 ISO_05_Req_Data 3;
BA_ "GenSigFuncType" SG_ 1797 ISO_05_Req_Data 9;
BA_ "GenSigSwitchedByIgnition" SG_ 1797 ISO_05_Req_Data 0;
BA_ "GenSigSendType" SG_ 1798 ISO_06_Req_Data 3;
BA_ "GenSigFuncType" SG_ 1798 ISO_06_Req_Data 9;
BA_ "GenSigSwitchedByIgnition" SG_ 1798 ISO_06_Req_Data 0;
BA_ "GenSigSendType" SG_ 1799 ISO_07_Req_Data 3;
BA_ "GenSigFuncType" SG_ 1799 ISO_07_Req_Data 9;
BA_ "GenSigSwitchedByIgnition" SG_ 1799 ISO_07_Req_Data 0;
BA_ "GenSigSendType" SG_ 1800 ISO_08_Req_Data 3;
BA_ "GenSigFuncType" SG_ 1800 ISO_08_Req_Data 9;
BA_ "GenSigSwitchedByIgnition" SG_ 1800 ISO_08_Req_Data 0;
BA_ "GenSigSendType" SG_ 1801 ISO_09_Req_Data 3;
BA_ "GenSigFuncType" SG_ 1801 ISO_09_Req_Data 9;
BA_ "GenSigSwitchedByIgnition" SG_ 1801 ISO_09_Req_Data 0;
BA_ "GenSigSendType" SG_ 1795 ISO_Funktionaler_Req_Abgas 3;
BA_ "GenSigFuncType" SG_ 1795 ISO_Funktionaler_Req_Abgas 9;
BA_ "GenSigSwitchedByIgnition" SG_ 1795 ISO_Funktionaler_Req_Abgas 0;
BA_ "GenSigSendType" SG_ 1792 ISO_ALL_01_Req_Data 3;
BA_ "GenSigFuncType" SG_ 1792 ISO_ALL_01_Req_Data 9;
BA_ "GenSigSwitchedByIgnition" SG_ 1792 ISO_ALL_01_Req_Data 0;
BA_ "GenSigSendType" SG_ 2015 ISO_OBD_Funktionaler_Req_Data 3;
BA_ "GenSigFuncType" SG_ 2015 ISO_OBD_Funktionaler_Req_Data 9;
BA_ "GenSigSwitchedByIgnition" SG_ 2015 ISO_OBD_Funktionaler_Req_Data 0;
BA_ "GenSigSendType" SG_ 1810 ISO_Lenkhilfe_Req_Data 3;
BA_ "GenSigFuncType" SG_ 1810 ISO_Lenkhilfe_Req_Data 9;
BA_ "GenSigSwitchedByIgnition" SG_ 1810 ISO_Lenkhilfe_Req_Data 0;
BA_ "GenSigSendType" SG_ 1916 ISO_Lenkhilfe_Resp_Data 3;
BA_ "GenSigFuncType" SG_ 1916 ISO_Lenkhilfe_Resp_Data 9;
BA_ "GenSigSwitchedByIgnition" SG_ 1916 ISO_Lenkhilfe_Resp_Data 0;
BA_ "GenSigSendType" SG_ 2020 ISO_OBD_03_Req_Data 3;
BA_ "GenSigFuncType" SG_ 2020 ISO_OBD_03_Req_Data 9;
BA_ "GenSigSwitchedByIgnition" SG_ 2020 ISO_OBD_03_Req_Data 0;
BA_ "GenSigSendType" SG_ 2028 ISO_OBD_03_Resp_Data 3;
BA_ "GenSigFuncType" SG_ 2028 ISO_OBD_03_Resp_Data 9;
BA_ "GenSigSwitchedByIgnition" SG_ 2028 ISO_OBD_03_Resp_Data 0;
BA_ "GenSigSendType" SG_ 1897 ISO_Rearview_Req_Data 3;
BA_ "GenSigFuncType" SG_ 1897 ISO_Rearview_Req_Data 9;
BA_ "GenSigSwitchedByIgnition" SG_ 1897 ISO_Rearview_Req_Data 0;
BA_ "GenSigSendType" SG_ 2003 ISO_Rearview_Resp_Data 3;
BA_ "GenSigFuncType" SG_ 2003 ISO_Rearview_Resp_Data 9;
BA_ "GenSigSwitchedByIgnition" SG_ 2003 ISO_Rearview_Resp_Data 0;
BA_ "GenSigSendType" SG_ 960 BCM_Ausparken_Betrieb 3;
BA_ "GenSigSwitchedByIgnition" SG_ 960 BCM_Ausparken_Betrieb 0;
BA_ "GenSigSendType" SG_ 960 BCM_Remotestart_Betrieb 3;
BA_ "GenSigSwitchedByIgnition" SG_ 960 BCM_Remotestart_Betrieb 0;
BA_ "GenSigSendType" SG_ 960 BCM_Remotestart_KL15_Anf 3;
BA_ "GenSigSwitchedByIgnition" SG_ 960 BCM_Remotestart_KL15_Anf 0;
BA_ "GenSigSendType" SG_ 960 BCM_Remotestart_MO_Start 3;
BA_ "GenSigSwitchedByIgnition" SG_ 960 BCM_Remotestart_MO_Start 0;
BA_ "GenSigSendType" SG_ 960 Klemmen_Status_01_BZ 0;
BA_ "GenSigFuncType" SG_ 960 Klemmen_Status_01_BZ 1;
BA_ "GenSigSwitchedByIgnition" SG_ 960 Klemmen_Status_01_BZ 0;
BA_ "GenSigSendType" SG_ 960 Klemmen_Status_01_CRC 0;
BA_ "GenSigFuncType" SG_ 960 Klemmen_Status_01_CRC 2;
BA_ "GenSigSwitchedByIgnition" SG_ 960 Klemmen_Status_01_CRC 0;
BA_ "GenSigSendType" SG_ 960 KST_Fahrerhinweis_1 3;
BA_ "GenSigSwitchedByIgnition" SG_ 960 KST_Fahrerhinweis_1 0;
BA_ "GenSigSendType" SG_ 960 KST_Fahrerhinweis_2 3;
BA_ "GenSigSwitchedByIgnition" SG_ 960 KST_Fahrerhinweis_2 0;
BA_ "GenSigSendType" SG_ 960 KST_Fahrerhinweis_4 3;
BA_ "GenSigSwitchedByIgnition" SG_ 960 KST_Fahrerhinweis_4 0;
BA_ "GenSigSendType" SG_ 960 KST_Fahrerhinweis_5 3;
BA_ "GenSigSwitchedByIgnition" SG_ 960 KST_Fahrerhinweis_5 0;
BA_ "GenSigSendType" SG_ 960 KST_Fahrerhinweis_6 3;
BA_ "GenSigSwitchedByIgnition" SG_ 960 KST_Fahrerhinweis_6 0;
BA_ "GenSigSendType" SG_ 960 KST_Warn_P1_ZST_def 3;
BA_ "GenSigSwitchedByIgnition" SG_ 960 KST_Warn_P1_ZST_def 0;
BA_ "GenSigSendType" SG_ 960 KST_Warn_P2_ZST_def 3;
BA_ "GenSigSwitchedByIgnition" SG_ 960 KST_Warn_P2_ZST_def 0;
BA_ "GenSigSendType" SG_ 960 RSt_Fahrerhinweise 3;
BA_ "GenSigSwitchedByIgnition" SG_ 960 RSt_Fahrerhinweise 0;
BA_ "GenSigSendType" SG_ 960 ZAS_Kl_15 3;
BA_ "NWM-WakeupAllowed" SG_ 960 ZAS_Kl_15 1;
BA_ "GenSigFuncType" SG_ 960 ZAS_Kl_15 6;
BA_ "GenSigSwitchedByIgnition" SG_ 960 ZAS_Kl_15 0;
BA_ "GenSigSendType" SG_ 960 ZAS_Kl_50_Startanforderung 3;
BA_ "GenSigSwitchedByIgnition" SG_ 960 ZAS_Kl_50_Startanforderung 0;
BA_ "GenSigSendType" SG_ 960 ZAS_Kl_Infotainment 3;
BA_ "GenSigSwitchedByIgnition" SG_ 960 ZAS_Kl_Infotainment 0;
BA_ "GenSigSendType" SG_ 960 ZAS_Kl_S 3;
BA_ "GenSigSwitchedByIgnition" SG_ 960 ZAS_Kl_S 0;
BA_ "GenSigSendType" SG_ 960 ZAS_Kl_X 3;
BA_ "GenSigSwitchedByIgnition" SG_ 960 ZAS_Kl_X 0;
BA_ "GenSigActiveRepetitions" SG_ 1640 FSH_Taster 5;
BA_ "GenSigSendType" SG_ 1640 FSH_Taster 4;
BA_ "GenSigSwitchedByIgnition" SG_ 1640 FSH_Taster 0;
BA_ "GenSigActiveRepetitions" SG_ 1640 HSH_Taster 5;
BA_ "GenSigSendType" SG_ 1640 HSH_Taster 4;
BA_ "GenSigSwitchedByIgnition" SG_ 1640 HSH_Taster 0;
BA_ "GenSigSendType" SG_ 1640 KL_Beschlagsgefahr 3;
BA_ "GenSigSwitchedByIgnition" SG_ 1640 KL_Beschlagsgefahr 0;
BA_ "GenSigSendType" SG_ 1640 KL_Geblspng_Fond_Soll 0;
BA_ "GenSigSwitchedByIgnition" SG_ 1640 KL_Geblspng_Fond_Soll 0;
BA_ "Fehlerwert" SG_ 1640 KL_Geblspng_Fond_Soll 255;
BA_ "GenSigSendType" SG_ 1640 KL_Geblspng_Soll 0;
BA_ "GenSigSwitchedByIgnition" SG_ 1640 KL_Geblspng_Soll 0;
BA_ "Fehlerwert" SG_ 1640 KL_Geblspng_Soll 255;
BA_ "GenSigSendType" SG_ 1640 KL_I_Geblaese 0;
BA_ "GenSigSwitchedByIgnition" SG_ 1640 KL_I_Geblaese 0;
BA_ "Fehlerwert" SG_ 1640 KL_I_Geblaese 255;
BA_ "GenSigSendType" SG_ 1640 KL_Kompressorstrom_soll 0;
BA_ "GenSigStartValue" SG_ 1640 KL_Kompressorstrom_soll 1022;
BA_ "GenSigSwitchedByIgnition" SG_ 1640 KL_Kompressorstrom_soll 0;
BA_ "Fehlerwert" SG_ 1640 KL_Kompressorstrom_soll 1023;
BA_ "GenSigSendType" SG_ 1640 KL_LRH_Stufe 3;
BA_ "GenSigStartValue" SG_ 1640 KL_LRH_Stufe 1;
BA_ "GenSigSwitchedByIgnition" SG_ 1640 KL_LRH_Stufe 0;
BA_ "GenSigActiveRepetitions" SG_ 1640 KL_LRH_Taster 5;
BA_ "GenSigSendType" SG_ 1640 KL_LRH_Taster 4;
BA_ "GenSigSwitchedByIgnition" SG_ 1640 KL_LRH_Taster 0;
BA_ "GenSigSendType" SG_ 1640 KL_PTC_Verbauinfo 0;
BA_ "GenSigSwitchedByIgnition" SG_ 1640 KL_PTC_Verbauinfo 0;
BA_ "GenSigSendType" SG_ 1640 KL_SIH_Soll_li 3;
BA_ "GenSigSwitchedByIgnition" SG_ 1640 KL_SIH_Soll_li 0;
BA_ "GenSigSendType" SG_ 1640 KL_SIH_Soll_re 3;
BA_ "GenSigSwitchedByIgnition" SG_ 1640 KL_SIH_Soll_re 0;
BA_ "GenSigSendType" SG_ 1640 KL_SIL_Soll_li 3;
BA_ "GenSigSwitchedByIgnition" SG_ 1640 KL_SIL_Soll_li 0;
BA_ "GenSigSendType" SG_ 1640 KL_SIL_Soll_re 3;
BA_ "GenSigSwitchedByIgnition" SG_ 1640 KL_SIL_Soll_re 0;
BA_ "GenSigSendType" SG_ 1640 KL_Umluftklappe_Status 0;
BA_ "GenSigStartValue" SG_ 1640 KL_Umluftklappe_Status 14;
BA_ "GenSigSwitchedByIgnition" SG_ 1640 KL_Umluftklappe_Status 0;
BA_ "Fehlerwert" SG_ 1640 KL_Umluftklappe_Status 15;
BA_ "GenSigSendType" SG_ 1640 KL_Zuheizer_Freigabe 3;
BA_ "GenSigSwitchedByIgnition" SG_ 1640 KL_Zuheizer_Freigabe 0;
BA_ "GenSigSendType" SG_ 1640 KRH_Soll_li 3;
BA_ "GenSigSwitchedByIgnition" SG_ 1640 KRH_Soll_li 0;
BA_ "GenSigSendType" SG_ 1640 KRH_Soll_re 3;
BA_ "GenSigSwitchedByIgnition" SG_ 1640 KRH_Soll_re 0;
BA_ "GenSigSendType" SG_ 2549088275 ABS_Abschaltstufe 0;
BA_ "GenSigSwitchedByIgnition" SG_ 2549088275 ABS_Abschaltstufe 0;
BA_ "GenSigSendType" SG_ 2549088275 ABS_SNI 0;
BA_ "GenSigStartValue" SG_ 2549088275 ABS_SNI 19;
BA_ "GenSigSwitchedByIgnition" SG_ 2549088275 ABS_SNI 0;
BA_ "GenSigSendType" SG_ 2549088275 ABS_Transport_Mode 0;
BA_ "GenSigSwitchedByIgnition" SG_ 2549088275 ABS_Transport_Mode 0;
BA_ "GenSigSendType" SG_ 2549088275 ESP_KD_Fehler 0;
BA_ "GenSigSwitchedByIgnition" SG_ 2549088275 ESP_KD_Fehler 0;
BA_ "GenSigSendType" SG_ 2549088275 ESP_KompSchutz 0;
BA_ "GenSigSwitchedByIgnition" SG_ 2549088275 ESP_KompSchutz 0;
BA_ "GenSigSendType" SG_ 2549088275 ESP_Nachlauftyp 0;
BA_ "GenSigStartValue" SG_ 2549088275 ESP_Nachlauftyp 2;
BA_ "GenSigSwitchedByIgnition" SG_ 2549088275 ESP_Nachlauftyp 0;
BA_ "GenSigSendType" SG_ 2549088275 KN_ESP_BusKnockOutTimer 0;
BA_ "GenSigSwitchedByIgnition" SG_ 2549088275 KN_ESP_BusKnockOutTimer 0;
BA_ "GenSigSendType" SG_ 2549088271 Allrad_Abschaltstufe 0;
BA_ "GenSigSendType" SG_ 2549088271 Allrad_KompSchutz 0;
BA_ "GenSigSendType" SG_ 2549088271 Allrad_Nachlauftyp 0;
BA_ "GenSigSendType" SG_ 2549088271 Allrad_SNI 0;
BA_ "GenSigStartValue" SG_ 2549088271 Allrad_SNI 15;
BA_ "GenSigSendType" SG_ 2549088271 Allrad_Transport_Mode 0;
BA_ "GenSigSendType" SG_ 2549088271 ALR_KD_Fehler 0;
BA_ "GenSigSendType" SG_ 2549088370 Daempfer_Abschaltstufe 0;
BA_ "GenSigSendType" SG_ 2549088370 Daempfer_KompSchutz 0;
BA_ "GenSigSendType" SG_ 2549088370 Daempfer_Nachlauftyp 0;
BA_ "GenSigSendType" SG_ 2549088370 Daempfer_SNI 0;
BA_ "GenSigStartValue" SG_ 2549088370 Daempfer_SNI 114;
BA_ "GenSigSendType" SG_ 2549088370 Daempfer_Transport_Mode 0;
BA_ "GenSigSendType" SG_ 2549088370 DR_KD_Fehler 0;
BA_ "GenSigSendType" SG_ 2549088266 EPH_Abschaltstufe 0;
BA_ "GenSigSendType" SG_ 2549088266 EPH_KompSchutz 0;
BA_ "GenSigSendType" SG_ 2549088266 EPH_Nachlauftyp 0;
BA_ "GenSigSendType" SG_ 2549088266 EPH_SNI 0;
BA_ "GenSigStartValue" SG_ 2549088266 EPH_SNI 10;
BA_ "GenSigSendType" SG_ 2549088266 EPH_Transport_Mode 0;
BA_ "GenSigSendType" SG_ 2549088266 PH_KD_Fehler 0;
BA_ "GenSigSendType" SG_ 2549088274 EPS_KD_Fehler 0;
BA_ "GenSigSwitchedByIgnition" SG_ 2549088274 EPS_KD_Fehler 0;
BA_ "GenSigSendType" SG_ 2549088274 Lenkhilfe_Abschaltstufe 0;
BA_ "GenSigSwitchedByIgnition" SG_ 2549088274 Lenkhilfe_Abschaltstufe 0;
BA_ "GenSigSendType" SG_ 2549088274 Lenkhilfe_KompSchutz 0;
BA_ "GenSigSwitchedByIgnition" SG_ 2549088274 Lenkhilfe_KompSchutz 0;
BA_ "GenSigSendType" SG_ 2549088274 Lenkhilfe_Nachlauftyp 0;
BA_ "GenSigStartValue" SG_ 2549088274 Lenkhilfe_Nachlauftyp 2;
BA_ "GenSigSwitchedByIgnition" SG_ 2549088274 Lenkhilfe_Nachlauftyp 0;
BA_ "GenSigSendType" SG_ 2549088274 Lenkhilfe_SNI 0;
BA_ "GenSigStartValue" SG_ 2549088274 Lenkhilfe_SNI 18;
BA_ "GenSigSwitchedByIgnition" SG_ 2549088274 Lenkhilfe_SNI 0;
BA_ "GenSigSendType" SG_ 2549088274 Lenkhilfe_Transport_Mode 0;
BA_ "GenSigSwitchedByIgnition" SG_ 2549088274 Lenkhilfe_Transport_Mode 0;
BA_ "GenSigSendType" SG_ 2549088361 KN_Rearview_BusKnockOutTimer 0;
BA_ "GenSigSwitchedByIgnition" SG_ 2549088361 KN_Rearview_BusKnockOutTimer 0;
BA_ "GenSigSendType" SG_ 2549088361 Rearview_Abschaltstufe 0;
BA_ "GenSigSwitchedByIgnition" SG_ 2549088361 Rearview_Abschaltstufe 0;
BA_ "GenSigSendType" SG_ 2549088361 Rearview_KompSchutz 0;
BA_ "GenSigSwitchedByIgnition" SG_ 2549088361 Rearview_KompSchutz 0;
BA_ "GenSigSendType" SG_ 2549088361 Rearview_Nachlauftyp 0;
BA_ "GenSigStartValue" SG_ 2549088361 Rearview_Nachlauftyp 2;
BA_ "GenSigSwitchedByIgnition" SG_ 2549088361 Rearview_Nachlauftyp 0;
BA_ "GenSigSendType" SG_ 2549088361 Rearview_SNI 0;
BA_ "GenSigStartValue" SG_ 2549088361 Rearview_SNI 105;
BA_ "GenSigSwitchedByIgnition" SG_ 2549088361 Rearview_SNI 0;
BA_ "GenSigSendType" SG_ 2549088361 Rearview_Transport_Mode 0;
BA_ "GenSigSwitchedByIgnition" SG_ 2549088361 Rearview_Transport_Mode 0;
BA_ "GenSigSendType" SG_ 2549088361 RV_KD_Fehler 0;
BA_ "GenSigSwitchedByIgnition" SG_ 2549088361 RV_KD_Fehler 0;
BA_REL_ "GenSigTimeoutTime" BU_SG_REL_ Allrad_Haldex SG_ 173 GE_Zielgang 500;
BA_REL_ "GenSigTimeoutTime" BU_SG_REL_ AreaView_MQB SG_ 795 ESP_Lampe 500;
BA_REL_ "GenSigTimeoutTime" BU_SG_REL_ AreaView_MQB SG_ 795 ESP_Wegimp_VA 500;
BA_REL_ "GenSigTimeoutTime" BU_SG_REL_ AreaView_MQB SG_ 795 ESP_Fehlerstatus_Wegimp 500;
BA_REL_ "GenSigTimeoutTime" BU_SG_REL_ AreaView_MQB SG_ 795 ESP_Wegimp_Ueberlauf 500;
BA_REL_ "GenSigTimeoutTime" BU_SG_REL_ AreaView_MQB SG_ 795 ESP_QBit_Wegimp_VA 500;
BA_REL_ "GenSigTimeoutTime" BU_SG_REL_ AreaView_MQB SG_ 987 BCM_01_alt 1000;
BA_REL_ "GenSigTimeoutTime" BU_SG_REL_ AreaView_MQB SG_ 987 SMLS_01_alt 1000;
BA_REL_ "GenSigTimeoutTime" BU_SG_REL_ AreaView_MQB SG_ 987 ZV_02_alt 1000;
BA_REL_ "GenSigTimeoutTime" BU_SG_REL_ AreaView_MQB SG_ 987 Anhaenger_01_alt 1000;
BA_REL_ "GenSigTimeoutTime" BU_SG_REL_ AreaView_MQB SG_ 987 Licht_Anf_01_alt 1000;
BA_REL_ "GenSigTimeoutTime" BU_SG_REL_ AreaView_MQB SG_ 987 ZV_HFS_offen 1000;
BA_REL_ "GenSigTimeoutTime" BU_SG_REL_ AreaView_MQB SG_ 987 ZV_HBFS_offen 1000;
BA_REL_ "GenSigTimeoutTime" BU_SG_REL_ AreaView_MQB SG_ 987 ZV_BT_offen 1000;
BA_REL_ "GenSigTimeoutTime" BU_SG_REL_ AreaView_MQB SG_ 987 ZV_FT_offen 1000;
BA_REL_ "GenSigTimeoutTime" BU_SG_REL_ AreaView_MQB SG_ 987 AAG_Anhaenger_erkannt 1000;
BA_REL_ "GenSigTimeoutTime" BU_SG_REL_ AreaView_MQB SG_ 987 BCM1_MH_Schalter 1000;
BA_REL_ "GenSigTimeoutTime" BU_SG_REL_ AreaView_MQB SG_ 987 ZV_HD_offen 1000;
BA_REL_ "GenSigTimeoutTime" BU_SG_REL_ AreaView_MQB SG_ 987 BCM_Rueckfahrlicht_Anf 1000;
BA_REL_ "GenSigTimeoutTime" BU_SG_REL_ AreaView_MQB SG_ 987 BH_Blinker_li 1000;
BA_REL_ "GenSigTimeoutTime" BU_SG_REL_ AreaView_MQB SG_ 987 BH_Blinker_re 1000;
BA_REL_ "GenSigTimeoutTime" BU_SG_REL_ AreaView_MQB SG_ 173 GE_Fahrstufe 500;
BA_REL_ "GenSigTimeoutTime" BU_SG_REL_ AreaView_MQB SG_ 960 ZAS_Kl_15 1000;
BA_REL_ "GenSigTimeoutTime" BU_SG_REL_ Bremse_ABS_MK100 SG_ 987 BCM_01_alt 1000;
BA_REL_ "GenSigTimeoutTime" BU_SG_REL_ Bremse_ABS_MK100 SG_ 987 ZV_02_alt 1000;
BA_REL_ "GenSigTimeoutTime" BU_SG_REL_ Bremse_ABS_MK100 SG_ 987 Wischer_01_alt 1000;
BA_REL_ "GenSigTimeoutTime" BU_SG_REL_ Bremse_ABS_MK100 SG_ 987 BCM1_Rueckfahrlicht_Schalter 1000;
BA_REL_ "GenSigTimeoutTime" BU_SG_REL_ Bremse_ABS_MK100 SG_ 987 ZV_FT_offen 1000;
BA_REL_ "GenSigTimeoutTime" BU_SG_REL_ Bremse_ABS_MK100 SG_ 987 Wischer_vorne_aktiv 1000;
BA_REL_ "GenSigTimeoutTime" BU_SG_REL_ Bremse_ABS_MK100 SG_ 987 WWSs_01_alt 1000;
BA_REL_ "GenSigTimeoutTime" BU_SG_REL_ Bremse_ABS_MK100 SG_ 173 Getriebe_11_CRC 500;
BA_REL_ "GenSigTimeoutTime" BU_SG_REL_ Bremse_ABS_MK100 SG_ 173 Getriebe_11_BZ 500;
BA_REL_ "GenSigTimeoutTime" BU_SG_REL_ Bremse_ABS_MK100 SG_ 173 GE_Uefkt 500;
BA_REL_ "GenSigTimeoutTime" BU_SG_REL_ Bremse_ABS_MK100 SG_ 173 GE_Fahrstufe 500;
BA_REL_ "GenSigTimeoutTime" BU_SG_REL_ Bremse_ABS_MK100 SG_ 173 GE_Schaltablauf 500;
BA_REL_ "GenSigTimeoutTime" BU_SG_REL_ Bremse_ABS_MK100 SG_ 173 GE_Zielgang 500;
BA_REL_ "GenSigTimeoutTime" BU_SG_REL_ Bremse_ESP_EPB_EBC460Vi SG_ 264 Fahrwerk_01_CRC 500;
BA_REL_ "GenSigTimeoutTime" BU_SG_REL_ Bremse_ESP_EPB_EBC460Vi SG_ 264 Fahrwerk_01_BZ 500;
BA_REL_ "GenSigTimeoutTime" BU_SG_REL_ Bremse_ESP_EPB_EBC460Vi SG_ 264 FA_ESP_Zuschaltung 500;
BA_REL_ "GenSigTimeoutTime" BU_SG_REL_ Bremse_ESP_EPB_EBC460Vi SG_ 314 FCW_02_CRC 500;
BA_REL_ "GenSigTimeoutTime" BU_SG_REL_ Bremse_ESP_EPB_EBC460Vi SG_ 314 FCW_02_BZ 500;
BA_REL_ "GenSigTimeoutTime" BU_SG_REL_ Bremse_ESP_EPB_EBC460Vi SG_ 314 FCWO_Ruck_Freigabe 500;
BA_REL_ "GenSigTimeoutTime" BU_SG_REL_ Bremse_ESP_EPB_EBC460Vi SG_ 314 FCWO_Ruckprofil 500;
BA_REL_ "GenSigTimeoutTime" BU_SG_REL_ Bremse_ESP_EPB_EBC460Vi SG_ 314 FCWO_Anf_Prefill 500;
BA_REL_ "GenSigTimeoutTime" BU_SG_REL_ Bremse_ESP_EPB_EBC460Vi SG_ 314 FCWO_HBA_Param 500;
BA_REL_ "GenSigTimeoutTime" BU_SG_REL_ Bremse_ESP_EPB_EBC460Vi SG_ 314 FCWP_Anf_Prefill 500;
BA_REL_ "GenSigTimeoutTime" BU_SG_REL_ Bremse_ESP_EPB_EBC460Vi SG_ 314 FCWP_HBA_Param 500;
BA_REL_ "GenSigTimeoutTime" BU_SG_REL_ Bremse_ESP_EPB_EBC460Vi SG_ 314 FCWP_Ruck_Freigabe 500;
BA_REL_ "GenSigTimeoutTime" BU_SG_REL_ Bremse_ESP_EPB_EBC460Vi SG_ 314 FCWP_Ruckprofil 500;
BA_REL_ "GenSigTimeoutTime" BU_SG_REL_ Bremse_ESP_EPB_EBC460Vi SG_ 987 BCM_01_alt 1000;
BA_REL_ "GenSigTimeoutTime" BU_SG_REL_ Bremse_ESP_EPB_EBC460Vi SG_ 987 ZV_02_alt 1000;
BA_REL_ "GenSigTimeoutTime" BU_SG_REL_ Bremse_ESP_EPB_EBC460Vi SG_ 987 Wischer_01_alt 1000;
BA_REL_ "GenSigTimeoutTime" BU_SG_REL_ Bremse_ESP_EPB_EBC460Vi SG_ 987 Anhaenger_01_alt 1000;
BA_REL_ "GenSigTimeoutTime" BU_SG_REL_ Bremse_ESP_EPB_EBC460Vi SG_ 987 BCM1_Rueckfahrlicht_Schalter 1000;
BA_REL_ "GenSigTimeoutTime" BU_SG_REL_ Bremse_ESP_EPB_EBC460Vi SG_ 987 ZV_FT_offen 1000;
BA_REL_ "GenSigTimeoutTime" BU_SG_REL_ Bremse_ESP_EPB_EBC460Vi SG_ 987 Wischer_vorne_aktiv 1000;
BA_REL_ "GenSigTimeoutTime" BU_SG_REL_ Bremse_ESP_EPB_EBC460Vi SG_ 987 AAG_Anhaenger_erkannt 1000;
BA_REL_ "GenSigTimeoutTime" BU_SG_REL_ Bremse_ESP_EPB_EBC460Vi SG_ 987 WWSs_01_alt 1000;
BA_REL_ "GenSigTimeoutTime" BU_SG_REL_ Bremse_ESP_EPB_EBC460Vi SG_ 1004 Klima_11_alt 2000;
BA_REL_ "GenSigTimeoutTime" BU_SG_REL_ Bremse_ESP_EPB_EBC460Vi SG_ 1004 Motor_17_alt 2000;
BA_REL_ "GenSigTimeoutTime" BU_SG_REL_ Bremse_ESP_EPB_EBC460Vi SG_ 1004 MO_NGS_Position 2000;
BA_REL_ "GenSigTimeoutTime" BU_SG_REL_ Bremse_ESP_EPB_EBC460Vi SG_ 1004 MO_NGS_Status 2000;
BA_REL_ "GenSigTimeoutTime" BU_SG_REL_ Bremse_ESP_EPB_EBC460Vi SG_ 1004 KL_Vorwarn_Komp_ein 2000;
BA_REL_ "GenSigTimeoutTime" BU_SG_REL_ Bremse_ESP_EPB_EBC460Vi SG_ 173 Getriebe_11_CRC 500;
BA_REL_ "GenSigTimeoutTime" BU_SG_REL_ Bremse_ESP_EPB_EBC460Vi SG_ 173 Getriebe_11_BZ 500;
BA_REL_ "GenSigTimeoutTime" BU_SG_REL_ Bremse_ESP_EPB_EBC460Vi SG_ 173 GE_Uefkt 500;
BA_REL_ "GenSigTimeoutTime" BU_SG_REL_ Bremse_ESP_EPB_EBC460Vi SG_ 173 GE_Fahrstufe 500;
BA_REL_ "GenSigTimeoutTime" BU_SG_REL_ Bremse_ESP_EPB_EBC460Vi SG_ 173 GE_Schaltablauf 500;
BA_REL_ "GenSigTimeoutTime" BU_SG_REL_ Bremse_ESP_EPB_EBC460Vi SG_ 173 GE_Zielgang 500;
BA_REL_ "GenSigTimeoutTime" BU_SG_REL_ Bremse_ESP_EPB_EBC460Vi SG_ 968 GE_Verlustmoment 1000;
BA_REL_ "GenSigTimeoutTime" BU_SG_REL_ Bremse_ESP_EPB_EBC460Vi SG_ 968 GE_LaunchControl 1000;
BA_REL_ "GenSigTimeoutTime" BU_SG_REL_ Bremse_ESP_EPB_EBC460Vi SG_ 960 Klemmen_Status_01_CRC 1000;
BA_REL_ "GenSigTimeoutTime" BU_SG_REL_ Bremse_ESP_EPB_EBC460Vi SG_ 960 Klemmen_Status_01_BZ 1000;
BA_REL_ "GenSigTimeoutTime" BU_SG_REL_ Bremse_ESP_EPB_EBC460Vi SG_ 960 ZAS_Kl_S 1000;
BA_REL_ "GenSigTimeoutTime" BU_SG_REL_ Bremse_ESP_EPB_EBC460Vi SG_ 960 ZAS_Kl_15 1000;
BA_REL_ "GenSigTimeoutTime" BU_SG_REL_ Bremse_ESP_EPB_MK100 SG_ 264 Fahrwerk_01_CRC 500;
BA_REL_ "GenSigTimeoutTime" BU_SG_REL_ Bremse_ESP_EPB_MK100 SG_ 264 Fahrwerk_01_BZ 500;
BA_REL_ "GenSigTimeoutTime" BU_SG_REL_ Bremse_ESP_EPB_MK100 SG_ 264 FA_ESP_Zuschaltung 500;
BA_REL_ "GenSigTimeoutTime" BU_SG_REL_ Bremse_ESP_EPB_MK100 SG_ 314 FCW_02_CRC 500;
BA_REL_ "GenSigTimeoutTime" BU_SG_REL_ Bremse_ESP_EPB_MK100 SG_ 314 FCW_02_BZ 500;
BA_REL_ "GenSigTimeoutTime" BU_SG_REL_ Bremse_ESP_EPB_MK100 SG_ 314 FCWO_Ruck_Freigabe 500;
BA_REL_ "GenSigTimeoutTime" BU_SG_REL_ Bremse_ESP_EPB_MK100 SG_ 314 FCWO_Ruckprofil 500;
BA_REL_ "GenSigTimeoutTime" BU_SG_REL_ Bremse_ESP_EPB_MK100 SG_ 314 FCWO_Anf_Prefill 500;
BA_REL_ "GenSigTimeoutTime" BU_SG_REL_ Bremse_ESP_EPB_MK100 SG_ 314 FCWO_HBA_Param 500;
BA_REL_ "GenSigTimeoutTime" BU_SG_REL_ Bremse_ESP_EPB_MK100 SG_ 314 FCWP_Anf_Prefill 500;
BA_REL_ "GenSigTimeoutTime" BU_SG_REL_ Bremse_ESP_EPB_MK100 SG_ 314 FCWP_HBA_Param 500;
BA_REL_ "GenSigTimeoutTime" BU_SG_REL_ Bremse_ESP_EPB_MK100 SG_ 314 FCWP_Ruck_Freigabe 500;
BA_REL_ "GenSigTimeoutTime" BU_SG_REL_ Bremse_ESP_EPB_MK100 SG_ 314 FCWP_Ruckprofil 500;
BA_REL_ "GenSigTimeoutTime" BU_SG_REL_ Bremse_ESP_EPB_MK100 SG_ 987 BCM_01_alt 1000;
BA_REL_ "GenSigTimeoutTime" BU_SG_REL_ Bremse_ESP_EPB_MK100 SG_ 987 ZV_02_alt 1000;
BA_REL_ "GenSigTimeoutTime" BU_SG_REL_ Bremse_ESP_EPB_MK100 SG_ 987 Wischer_01_alt 1000;
BA_REL_ "GenSigTimeoutTime" BU_SG_REL_ Bremse_ESP_EPB_MK100 SG_ 987 Anhaenger_01_alt 1000;
BA_REL_ "GenSigTimeoutTime" BU_SG_REL_ Bremse_ESP_EPB_MK100 SG_ 987 BCM1_Rueckfahrlicht_Schalter 1000;
BA_REL_ "GenSigTimeoutTime" BU_SG_REL_ Bremse_ESP_EPB_MK100 SG_ 987 ZV_FT_offen 1000;
BA_REL_ "GenSigTimeoutTime" BU_SG_REL_ Bremse_ESP_EPB_MK100 SG_ 987 Wischer_vorne_aktiv 1000;
BA_REL_ "GenSigTimeoutTime" BU_SG_REL_ Bremse_ESP_EPB_MK100 SG_ 987 AAG_Anhaenger_erkannt 1000;
BA_REL_ "GenSigTimeoutTime" BU_SG_REL_ Bremse_ESP_EPB_MK100 SG_ 987 WWSs_01_alt 1000;
BA_REL_ "GenSigTimeoutTime" BU_SG_REL_ Bremse_ESP_EPB_MK100 SG_ 1004 Klima_11_alt 2000;
BA_REL_ "GenSigTimeoutTime" BU_SG_REL_ Bremse_ESP_EPB_MK100 SG_ 1004 Motor_17_alt 2000;
BA_REL_ "GenSigTimeoutTime" BU_SG_REL_ Bremse_ESP_EPB_MK100 SG_ 1004 MO_NGS_Position 2000;
BA_REL_ "GenSigTimeoutTime" BU_SG_REL_ Bremse_ESP_EPB_MK100 SG_ 1004 MO_NGS_Status 2000;
BA_REL_ "GenSigTimeoutTime" BU_SG_REL_ Bremse_ESP_EPB_MK100 SG_ 1004 KL_Vorwarn_Komp_ein 2000;
BA_REL_ "GenSigTimeoutTime" BU_SG_REL_ Bremse_ESP_EPB_MK100 SG_ 173 Getriebe_11_CRC 500;
BA_REL_ "GenSigTimeoutTime" BU_SG_REL_ Bremse_ESP_EPB_MK100 SG_ 173 Getriebe_11_BZ 500;
BA_REL_ "GenSigTimeoutTime" BU_SG_REL_ Bremse_ESP_EPB_MK100 SG_ 173 GE_Uefkt 500;
BA_REL_ "GenSigTimeoutTime" BU_SG_REL_ Bremse_ESP_EPB_MK100 SG_ 173 GE_Fahrstufe 500;
BA_REL_ "GenSigTimeoutTime" BU_SG_REL_ Bremse_ESP_EPB_MK100 SG_ 173 GE_Schaltablauf 500;
BA_REL_ "GenSigTimeoutTime" BU_SG_REL_ Bremse_ESP_EPB_MK100 SG_ 173 GE_Zielgang 500;
BA_REL_ "GenSigTimeoutTime" BU_SG_REL_ Bremse_ESP_EPB_MK100 SG_ 968 GE_Verlustmoment 1000;
BA_REL_ "GenSigTimeoutTime" BU_SG_REL_ Bremse_ESP_EPB_MK100 SG_ 968 GE_LaunchControl 1000;
BA_REL_ "GenSigTimeoutTime" BU_SG_REL_ Bremse_ESP_EPB_MK100 SG_ 294 HCA_01_CRC 5000;
BA_REL_ "GenSigTimeoutTime" BU_SG_REL_ Bremse_ESP_EPB_MK100 SG_ 294 HCA_01_BZ 5000;
BA_REL_ "GenSigTimeoutTime" BU_SG_REL_ Bremse_ESP_EPB_MK100 SG_ 294 EA_Ruckprofil 5000;
BA_REL_ "GenSigTimeoutTime" BU_SG_REL_ Bremse_ESP_EPB_MK100 SG_ 294 HCA_01_Sendestatus 5000;
BA_REL_ "GenSigTimeoutTime" BU_SG_REL_ Bremse_ESP_EPB_MK100 SG_ 294 EA_Ruckfreigabe 5000;
BA_REL_ "GenSigTimeoutTime" BU_SG_REL_ Bremse_ESP_EPB_MK100 SG_ 960 Klemmen_Status_01_CRC 1000;
BA_REL_ "GenSigTimeoutTime" BU_SG_REL_ Bremse_ESP_EPB_MK100 SG_ 960 Klemmen_Status_01_BZ 1000;
BA_REL_ "GenSigTimeoutTime" BU_SG_REL_ Bremse_ESP_EPB_MK100 SG_ 960 ZAS_Kl_S 1000;
BA_REL_ "GenSigTimeoutTime" BU_SG_REL_ Bremse_ESP_EPB_MK100 SG_ 960 ZAS_Kl_15 1000;
BA_REL_ "GenSigTimeoutTime" BU_SG_REL_ Bremse_ESP_MK100 SG_ 264 Fahrwerk_01_CRC 500;
BA_REL_ "GenSigTimeoutTime" BU_SG_REL_ Bremse_ESP_MK100 SG_ 264 Fahrwerk_01_BZ 500;
BA_REL_ "GenSigTimeoutTime" BU_SG_REL_ Bremse_ESP_MK100 SG_ 264 FA_ESP_Zuschaltung 500;
BA_REL_ "GenSigTimeoutTime" BU_SG_REL_ Bremse_ESP_MK100 SG_ 987 BCM_01_alt 1000;
BA_REL_ "GenSigTimeoutTime" BU_SG_REL_ Bremse_ESP_MK100 SG_ 987 ZV_02_alt 1000;
BA_REL_ "GenSigTimeoutTime" BU_SG_REL_ Bremse_ESP_MK100 SG_ 987 Wischer_01_alt 1000;
BA_REL_ "GenSigTimeoutTime" BU_SG_REL_ Bremse_ESP_MK100 SG_ 987 Anhaenger_01_alt 1000;
BA_REL_ "GenSigTimeoutTime" BU_SG_REL_ Bremse_ESP_MK100 SG_ 987 BCM1_Rueckfahrlicht_Schalter 1000;
BA_REL_ "GenSigTimeoutTime" BU_SG_REL_ Bremse_ESP_MK100 SG_ 987 ZV_FT_offen 1000;
BA_REL_ "GenSigTimeoutTime" BU_SG_REL_ Bremse_ESP_MK100 SG_ 987 Wischer_vorne_aktiv 1000;
BA_REL_ "GenSigTimeoutTime" BU_SG_REL_ Bremse_ESP_MK100 SG_ 987 AAG_Anhaenger_erkannt 1000;
BA_REL_ "GenSigTimeoutTime" BU_SG_REL_ Bremse_ESP_MK100 SG_ 987 WWSs_01_alt 1000;
BA_REL_ "GenSigTimeoutTime" BU_SG_REL_ Bremse_ESP_MK100 SG_ 173 Getriebe_11_CRC 500;
BA_REL_ "GenSigTimeoutTime" BU_SG_REL_ Bremse_ESP_MK100 SG_ 173 Getriebe_11_BZ 500;
BA_REL_ "GenSigTimeoutTime" BU_SG_REL_ Bremse_ESP_MK100 SG_ 173 GE_Uefkt 500;
BA_REL_ "GenSigTimeoutTime" BU_SG_REL_ Bremse_ESP_MK100 SG_ 173 GE_Fahrstufe 500;
BA_REL_ "GenSigTimeoutTime" BU_SG_REL_ Bremse_ESP_MK100 SG_ 173 GE_Schaltablauf 500;
BA_REL_ "GenSigTimeoutTime" BU_SG_REL_ Bremse_ESP_MK100 SG_ 173 GE_Zielgang 500;
BA_REL_ "GenSigTimeoutTime" BU_SG_REL_ Bremse_ESP_MK100 SG_ 968 GE_LaunchControl 1000;
BA_REL_ "GenSigTimeoutTime" BU_SG_REL_ Bremse_ESP_MK100 SG_ 294 HCA_01_CRC 5000;
BA_REL_ "GenSigTimeoutTime" BU_SG_REL_ Bremse_ESP_MK100 SG_ 294 HCA_01_BZ 5000;
BA_REL_ "GenSigTimeoutTime" BU_SG_REL_ Bremse_ESP_MK100 SG_ 294 EA_Ruckprofil 5000;
BA_REL_ "GenSigTimeoutTime" BU_SG_REL_ Bremse_ESP_MK100 SG_ 294 HCA_01_Sendestatus 5000;
BA_REL_ "GenSigTimeoutTime" BU_SG_REL_ Bremse_ESP_MK100 SG_ 294 EA_Ruckfreigabe 5000;
BA_REL_ "GenSigTimeoutTime" BU_SG_REL_ Gateway_MQB SG_ 795 ESP_Wegimp_VA 500;
BA_REL_ "GenSigTimeoutTime" BU_SG_REL_ Gateway_MQB SG_ 795 ESP_Fehlerstatus_Wegimp 500;
BA_REL_ "GenSigTimeoutTime" BU_SG_REL_ Gateway_MQB SG_ 795 ESP_Wegimp_Ueberlauf 500;
BA_REL_ "GenSigTimeoutTime" BU_SG_REL_ Gateway_MQB SG_ 2589283617 EDS_Charisma_FahrPr 5000;
BA_REL_ "GenSigTimeoutTime" BU_SG_REL_ Gateway_MQB SG_ 2589283617 EDS_Charisma_Status 5000;
BA_REL_ "GenSigTimeoutTime" BU_SG_REL_ Gateway_MQB SG_ 2589283617 HHC_Charisma_Status 5000;
BA_REL_ "GenSigTimeoutTime" BU_SG_REL_ Gateway_MQB SG_ 2589283617 HHC_Charisma_FahrPr 5000;
BA_REL_ "GenSigTimeoutTime" BU_SG_REL_ Gateway_MQB SG_ 427 ESC_Warnruck_aktiv 2000;
BA_REL_ "GenSigTimeoutTime" BU_SG_REL_ Gateway_MQB SG_ 427 ESC_Warnruck_nicht_verfuegbar 2000;
BA_REL_ "GenSigTimeoutTime" BU_SG_REL_ Gateway_MQB SG_ 427 ESC_Konsistenz_AGW 2000;
BA_REL_ "GenSigTimeoutTime" BU_SG_REL_ Gateway_MQB SG_ 2549088275 ESP_Nachlauftyp 5000;
BA_REL_ "GenSigTimeoutTime" BU_SG_REL_ Gateway_MQB SG_ 2549088275 ESP_KD_Fehler 2500;
BA_REL_ "GenSigTimeoutTime" BU_SG_REL_ Gateway_MQB SG_ 2549088271 Allrad_Nachlauftyp 5000;
BA_REL_ "GenSigTimeoutTime" BU_SG_REL_ Gateway_MQB SG_ 2549088271 ALR_KD_Fehler 2500;
BA_REL_ "GenSigTimeoutTime" BU_SG_REL_ Gateway_MQB SG_ 2549088370 Daempfer_Nachlauftyp 5000;
BA_REL_ "GenSigTimeoutTime" BU_SG_REL_ Gateway_MQB SG_ 2549088370 DR_KD_Fehler 2500;
BA_REL_ "GenSigTimeoutTime" BU_SG_REL_ Gateway_MQB SG_ 2549088266 EPH_Nachlauftyp 5000;
BA_REL_ "GenSigTimeoutTime" BU_SG_REL_ Gateway_MQB SG_ 2549088266 PH_KD_Fehler 2500;
BA_REL_ "GenSigTimeoutTime" BU_SG_REL_ Gateway_MQB SG_ 2549088274 Lenkhilfe_Nachlauftyp 5000;
BA_REL_ "GenSigTimeoutTime" BU_SG_REL_ Gateway_MQB SG_ 2549088274 EPS_KD_Fehler 2500;
BA_REL_ "GenSigTimeoutTime" BU_SG_REL_ Gateway_MQB SG_ 2549088361 Rearview_Nachlauftyp 5000;
BA_REL_ "GenSigTimeoutTime" BU_SG_REL_ Gateway_MQB SG_ 2549088361 RV_KD_Fehler 2500;
BA_REL_ "GenSigTimeoutTime" BU_SG_REL_ Lenkhilfe_EPS SG_ 795 ESP_24_CRC 500;
BA_REL_ "GenSigTimeoutTime" BU_SG_REL_ Lenkhilfe_EPS SG_ 795 ESP_24_BZ 500;
BA_REL_ "GenSigTimeoutTime" BU_SG_REL_ Lenkhilfe_EPS SG_ 795 ESP_Lampe 500;
BA_REL_ "GenSigTimeoutTime" BU_SG_REL_ Lenkhilfe_EPS SG_ 795 ABS_Lampe 500;
BA_REL_ "GenSigTimeoutTime" BU_SG_REL_ Lenkhilfe_EPS SG_ 795 ESP_Off_Lampe 500;
BA_REL_ "GenSigTimeoutTime" BU_SG_REL_ Lenkhilfe_EPS SG_ 987 Klima_Sensor_02_alt 1000;
BA_REL_ "GenSigTimeoutTime" BU_SG_REL_ Lenkhilfe_EPS SG_ 987 Licht_Anf_01_alt 1000;
BA_REL_ "GenSigTimeoutTime" BU_SG_REL_ Lenkhilfe_EPS SG_ 987 BCM_Rueckfahrlicht_Anf 1000;
BA_REL_ "GenSigTimeoutTime" BU_SG_REL_ Lenkhilfe_EPS SG_ 987 BCM1_OBD_FStatus_ATemp 1000;
BA_REL_ "GenSigTimeoutTime" BU_SG_REL_ Lenkhilfe_EPS SG_ 987 BCM1_Aussen_Temp_ungef 1000;
BA_REL_ "GenSigTimeoutTime" BU_SG_REL_ Lenkhilfe_EPS SG_ 294 HCA_01_CRC 5000;
BA_REL_ "GenSigTimeoutTime" BU_SG_REL_ Lenkhilfe_EPS SG_ 294 HCA_01_BZ 5000;
BA_REL_ "GenSigTimeoutTime" BU_SG_REL_ Lenkhilfe_EPS SG_ 294 HCA_01_Vib_Freq 5000;
BA_REL_ "GenSigTimeoutTime" BU_SG_REL_ Lenkhilfe_EPS SG_ 294 HCA_01_LM_Offset 5000;
BA_REL_ "GenSigTimeoutTime" BU_SG_REL_ Lenkhilfe_EPS SG_ 294 HCA_01_LM_OffSign 5000;
BA_REL_ "GenSigTimeoutTime" BU_SG_REL_ Lenkhilfe_EPS SG_ 294 HCA_01_Status_HCA 5000;
BA_REL_ "GenSigTimeoutTime" BU_SG_REL_ Lenkhilfe_EPS SG_ 294 HCA_01_Vib_Amp 5000;
BA_REL_ "GenSigTimeoutTime" BU_SG_REL_ Lenkhilfe_EPS SG_ 960 Klemmen_Status_01_CRC 1000;
BA_REL_ "GenSigTimeoutTime" BU_SG_REL_ Lenkhilfe_EPS SG_ 960 Klemmen_Status_01_BZ 1000;
BA_REL_ "GenSigTimeoutTime" BU_SG_REL_ Lenkhilfe_EPS SG_ 960 ZAS_Kl_S 1000;
BA_REL_ "GenSigTimeoutTime" BU_SG_REL_ Lenkhilfe_EPS SG_ 960 ZAS_Kl_15 1000;
BA_REL_ "GenSigTimeoutTime" BU_SG_REL_ PDC SG_ 795 ESP_Lampe 500;
BA_REL_ "GenSigTimeoutTime" BU_SG_REL_ PDC SG_ 427 ESP_33_CRC 2000;
BA_REL_ "GenSigTimeoutTime" BU_SG_REL_ PDC SG_ 427 ESP_33_BZ 2000;
BA_REL_ "GenSigTimeoutTime" BU_SG_REL_ PDC SG_ 427 ESC_AHW_aktiv 2000;
BA_REL_ "GenSigTimeoutTime" BU_SG_REL_ PDC SG_ 427 ESC_AHW_nicht_verfuegbar 2000;
BA_REL_ "GenSigTimeoutTime" BU_SG_REL_ PDC SG_ 427 ESC_Verz_Reg_aktiv 2000;
BA_REL_ "GenSigTimeoutTime" BU_SG_REL_ PDC SG_ 427 ESC_Verz_Reg_nicht_verfuegbar 2000;
BA_REL_ "GenSigTimeoutTime" BU_SG_REL_ PDC SG_ 427 ESC_Konsistenz_IPA 2000;
BA_REL_ "GenSigTimeoutTime" BU_SG_REL_ PDC SG_ 427 ESC_Fahrer_Bremsdruck_bestimmend 2000;
BA_REL_ "GenSigTimeoutTime" BU_SG_REL_ PDC SG_ 427 ESC_Konsistenz_BFF 2000;
BA_REL_ "GenSigTimeoutTime" BU_SG_REL_ PDC SG_ 427 ESC_Verz_ASIL_Verfuegbarkeit 2000;
BA_REL_ "GenSigTimeoutTime" BU_SG_REL_ PDC SG_ 987 BCM_01_alt 1000;
BA_REL_ "GenSigTimeoutTime" BU_SG_REL_ PDC SG_ 987 SMLS_01_alt 1000;
BA_REL_ "GenSigTimeoutTime" BU_SG_REL_ PDC SG_ 987 ZV_02_alt 1000;
BA_REL_ "GenSigTimeoutTime" BU_SG_REL_ PDC SG_ 987 Anhaenger_01_alt 1000;
BA_REL_ "GenSigTimeoutTime" BU_SG_REL_ PDC SG_ 987 Klima_Sensor_02_alt 1000;
BA_REL_ "GenSigTimeoutTime" BU_SG_REL_ PDC SG_ 987 Verdeck_01_alt 1000;
BA_REL_ "GenSigTimeoutTime" BU_SG_REL_ PDC SG_ 987 WFS_01_alt 1000;
BA_REL_ "GenSigTimeoutTime" BU_SG_REL_ PDC SG_ 987 Licht_Anf_01_alt 1000;
BA_REL_ "GenSigTimeoutTime" BU_SG_REL_ PDC SG_ 987 AAG_Anhaenger_abgesteckt 1000;
BA_REL_ "GenSigTimeoutTime" BU_SG_REL_ PDC SG_ 987 VS_Verdeck_Anf 1000;
BA_REL_ "GenSigTimeoutTime" BU_SG_REL_ PDC SG_ 987 VS_VD_entriegelt 1000;
BA_REL_ "GenSigTimeoutTime" BU_SG_REL_ PDC SG_ 987 ZV_HFS_offen 1000;
BA_REL_ "GenSigTimeoutTime" BU_SG_REL_ PDC SG_ 987 ZV_HBFS_offen 1000;
BA_REL_ "GenSigTimeoutTime" BU_SG_REL_ PDC SG_ 987 VS_VD_offen_ver 1000;
BA_REL_ "GenSigTimeoutTime" BU_SG_REL_ PDC SG_ 987 VS_VD_zu_ver 1000;
BA_REL_ "GenSigTimeoutTime" BU_SG_REL_ PDC SG_ 987 ZV_BT_offen 1000;
BA_REL_ "GenSigTimeoutTime" BU_SG_REL_ PDC SG_ 987 BCM1_Rueckfahrlicht_Schalter 1000;
BA_REL_ "GenSigTimeoutTime" BU_SG_REL_ PDC SG_ 987 ZV_FT_offen 1000;
BA_REL_ "GenSigTimeoutTime" BU_SG_REL_ PDC SG_ 987 AAG_Anhaenger_erkannt 1000;
BA_REL_ "GenSigTimeoutTime" BU_SG_REL_ PDC SG_ 987 ZV_HD_offen 1000;
BA_REL_ "GenSigTimeoutTime" BU_SG_REL_ PDC SG_ 987 WFS_Schluessel_Fahrberecht 1000;
BA_REL_ "GenSigTimeoutTime" BU_SG_REL_ PDC SG_ 987 BCM_Rueckfahrlicht_Anf 1000;
BA_REL_ "GenSigTimeoutTime" BU_SG_REL_ PDC SG_ 987 AAG_LED_aktiv 1000;
BA_REL_ "GenSigTimeoutTime" BU_SG_REL_ PDC SG_ 987 BH_Blinker_li 1000;
BA_REL_ "GenSigTimeoutTime" BU_SG_REL_ PDC SG_ 987 BH_Blinker_re 1000;
BA_REL_ "GenSigTimeoutTime" BU_SG_REL_ PDC SG_ 987 BCM1_Aussen_Temp_ungef 1000;
BA_REL_ "GenSigTimeoutTime" BU_SG_REL_ PDC SG_ 1004 HDSG_01_alt 2000;
BA_REL_ "GenSigTimeoutTime" BU_SG_REL_ PDC SG_ 1004 ACC_02_alt 2000;
BA_REL_ "GenSigTimeoutTime" BU_SG_REL_ PDC SG_ 1004 HD_Endstellung_oben 2000;
BA_REL_ "GenSigTimeoutTime" BU_SG_REL_ PDC SG_ 1004 HD_Endstellung_unten 2000;
BA_REL_ "GenSigTimeoutTime" BU_SG_REL_ PDC SG_ 1004 ACC_Status_Anzeige 2000;
BA_REL_ "GenSigTimeoutTime" BU_SG_REL_ PDC SG_ 1004 HD_Position 2000;
BA_REL_ "GenSigTimeoutTime" BU_SG_REL_ PDC SG_ 173 GE_Fahrstufe 500;
BA_REL_ "GenSigTimeoutTime" BU_SG_REL_ PDC SG_ 960 ZAS_Kl_15 1000;
BA_REL_ "GenSigTimeoutTime" BU_SG_REL_ PDC SG_ 1640 KL_Geblspng_Soll 2000;
BA_REL_ "GenSigTimeoutTime" BU_SG_REL_ PDC SG_ 1640 KL_Geblspng_Fond_Soll 2000;
BA_REL_ "GenSigTimeoutTime" BU_SG_REL_ PDC_PLA SG_ 795 ESP_Lampe 500;
BA_REL_ "GenSigTimeoutTime" BU_SG_REL_ PDC_PLA SG_ 427 ESC_AHW_aktiv 2000;
BA_REL_ "GenSigTimeoutTime" BU_SG_REL_ PDC_PLA SG_ 427 ESC_AHW_nicht_verfuegbar 2000;
BA_REL_ "GenSigTimeoutTime" BU_SG_REL_ PDC_PLA SG_ 427 ESC_Verz_Reg_aktiv 2000;
BA_REL_ "GenSigTimeoutTime" BU_SG_REL_ PDC_PLA SG_ 427 ESC_Verz_Reg_nicht_verfuegbar 2000;
BA_REL_ "GenSigTimeoutTime" BU_SG_REL_ PDC_PLA SG_ 427 ESC_Konsistenz_IPA 2000;
BA_REL_ "GenSigTimeoutTime" BU_SG_REL_ PDC_PLA SG_ 427 ESC_Fahrer_Bremsdruck_bestimmend 2000;
BA_REL_ "GenSigTimeoutTime" BU_SG_REL_ PDC_PLA SG_ 427 ESC_Konsistenz_BFF 2000;
BA_REL_ "GenSigTimeoutTime" BU_SG_REL_ PDC_PLA SG_ 427 ESC_Verz_ASIL_Verfuegbarkeit 2000;
BA_REL_ "GenSigTimeoutTime" BU_SG_REL_ PDC_PLA SG_ 987 BCM_01_alt 1000;
BA_REL_ "GenSigTimeoutTime" BU_SG_REL_ PDC_PLA SG_ 987 SMLS_01_alt 1000;
BA_REL_ "GenSigTimeoutTime" BU_SG_REL_ PDC_PLA SG_ 987 ZV_02_alt 1000;
BA_REL_ "GenSigTimeoutTime" BU_SG_REL_ PDC_PLA SG_ 987 Anhaenger_01_alt 1000;
BA_REL_ "GenSigTimeoutTime" BU_SG_REL_ PDC_PLA SG_ 987 Klima_Sensor_02_alt 1000;
BA_REL_ "GenSigTimeoutTime" BU_SG_REL_ PDC_PLA SG_ 987 Verdeck_01_alt 1000;
BA_REL_ "GenSigTimeoutTime" BU_SG_REL_ PDC_PLA SG_ 987 WFS_01_alt 1000;
BA_REL_ "GenSigTimeoutTime" BU_SG_REL_ PDC_PLA SG_ 987 Licht_Anf_01_alt 1000;
BA_REL_ "GenSigTimeoutTime" BU_SG_REL_ PDC_PLA SG_ 987 AAG_Anhaenger_abgesteckt 1000;
BA_REL_ "GenSigTimeoutTime" BU_SG_REL_ PDC_PLA SG_ 987 VS_Verdeck_Anf 1000;
BA_REL_ "GenSigTimeoutTime" BU_SG_REL_ PDC_PLA SG_ 987 VS_VD_entriegelt 1000;
BA_REL_ "GenSigTimeoutTime" BU_SG_REL_ PDC_PLA SG_ 987 ZV_HFS_offen 1000;
BA_REL_ "GenSigTimeoutTime" BU_SG_REL_ PDC_PLA SG_ 987 ZV_HBFS_offen 1000;
BA_REL_ "GenSigTimeoutTime" BU_SG_REL_ PDC_PLA SG_ 987 VS_VD_offen_ver 1000;
BA_REL_ "GenSigTimeoutTime" BU_SG_REL_ PDC_PLA SG_ 987 VS_VD_zu_ver 1000;
BA_REL_ "GenSigTimeoutTime" BU_SG_REL_ PDC_PLA SG_ 987 ZV_BT_offen 1000;
BA_REL_ "GenSigTimeoutTime" BU_SG_REL_ PDC_PLA SG_ 987 BCM1_Rueckfahrlicht_Schalter 1000;
BA_REL_ "GenSigTimeoutTime" BU_SG_REL_ PDC_PLA SG_ 987 ZV_FT_offen 1000;
BA_REL_ "GenSigTimeoutTime" BU_SG_REL_ PDC_PLA SG_ 987 AAG_Anhaenger_erkannt 1000;
BA_REL_ "GenSigTimeoutTime" BU_SG_REL_ PDC_PLA SG_ 987 ZV_HD_offen 1000;
BA_REL_ "GenSigTimeoutTime" BU_SG_REL_ PDC_PLA SG_ 987 WFS_Schluessel_Fahrberecht 1000;
BA_REL_ "GenSigTimeoutTime" BU_SG_REL_ PDC_PLA SG_ 987 BCM_Rueckfahrlicht_Anf 1000;
BA_REL_ "GenSigTimeoutTime" BU_SG_REL_ PDC_PLA SG_ 987 AAG_LED_aktiv 1000;
BA_REL_ "GenSigTimeoutTime" BU_SG_REL_ PDC_PLA SG_ 987 BH_Blinker_li 1000;
BA_REL_ "GenSigTimeoutTime" BU_SG_REL_ PDC_PLA SG_ 987 BH_Blinker_re 1000;
BA_REL_ "GenSigTimeoutTime" BU_SG_REL_ PDC_PLA SG_ 987 BCM1_Aussen_Temp_ungef 1000;
BA_REL_ "GenSigTimeoutTime" BU_SG_REL_ PDC_PLA SG_ 1004 HDSG_01_alt 2000;
BA_REL_ "GenSigTimeoutTime" BU_SG_REL_ PDC_PLA SG_ 1004 ACC_02_alt 2000;
BA_REL_ "GenSigTimeoutTime" BU_SG_REL_ PDC_PLA SG_ 1004 LDW_02_alt 2000;
BA_REL_ "GenSigTimeoutTime" BU_SG_REL_ PDC_PLA SG_ 1004 HC_Uss_Anforderung 2000;
BA_REL_ "GenSigTimeoutTime" BU_SG_REL_ PDC_PLA SG_ 1004 HD_Endstellung_oben 2000;
BA_REL_ "GenSigTimeoutTime" BU_SG_REL_ PDC_PLA SG_ 1004 HD_Endstellung_unten 2000;
BA_REL_ "GenSigTimeoutTime" BU_SG_REL_ PDC_PLA SG_ 1004 ACC_Status_Anzeige 2000;
BA_REL_ "GenSigTimeoutTime" BU_SG_REL_ PDC_PLA SG_ 1004 HD_Position 2000;
BA_REL_ "GenSigTimeoutTime" BU_SG_REL_ PDC_PLA SG_ 173 GE_Fahrstufe 500;
BA_REL_ "GenSigTimeoutTime" BU_SG_REL_ PDC_PLA SG_ 960 ZAS_Kl_15 1000;
BA_REL_ "GenSigTimeoutTime" BU_SG_REL_ PDC_PLA SG_ 1640 KL_Geblspng_Soll 2000;
BA_REL_ "GenSigTimeoutTime" BU_SG_REL_ PDC_PLA SG_ 1640 KL_Geblspng_Fond_Soll 2000;
VAL_ 795 ESP_Lampe 0 "Aus" 1 "Ein" ;
VAL_ 795 ABS_Lampe 0 "Aus" 1 "Ein" ;
VAL_ 795 BK_Lampe_02 0 "aus" 1 "ein_statisch" 3 "Warnung" ;
VAL_ 795 TC_Lampe 0 "Aus" 1 "Ein" ;
VAL_ 795 ESP_m_Raddrehz 32765 "Unterspannung" 32766 "Init" 32767 "Fehler" ;
VAL_ 795 ESP_Textanzeigen_03 0 "kein_Text" 1 "ESP_Stoerung" 2 "ABS_Stoerung" 3 "ESP_ABS_Stoerung" 4 "Werkstatt_Bremse" 5 "ASR_Stoerung" 6 "ESP_switched_off" 7 "ASR_off" 8 "ESP_ASR_on" 10 "keine_Bremskraftverstaerkung" 11 "ASR_aktiviert" 12 "ABS_ASR_Stoerung" 15 "ESP_offroad" 17 "ESP_sport" 18 "ESP_Zwangsaktivierung" 19 "ESP_Taster_Info" 20 "TC_aktiv" 21 "reserviert_fuer_Verlwarn" 22 "TC_switched_off" 23 "Verlwarn_akt_Rollsicher_inakt" 24 "ESP_SuperSport" 25 "ESP_Offroad_nicht_verfuegbar" ;
VAL_ 795 ESP_Meldungen 0 "keine_Anzeige" 1 "Autohold_Hinweis_1" 2 "Stoerung_Autohold" 3 "Stoerung_Hillholder" 4 "Uebernehmen" 5 "Autohold_aus" 6 "Autohold_Hinweis_2" ;
VAL_ 795 ESP_Fehlerstatus_Wegimp 0 "Wegimpulse_iO" 1 "Fehler" ;
VAL_ 795 ESP_Wegimp_Ueberlauf 0 "Reset_und_kein_Ueberlauf" 1 "mindestens_1x_Ueberlauf" ;
VAL_ 795 ESP_QBit_Wegimp_VA 0 "gueltiger_Wert" 1 "Ersatz_Init_oder_Fehlerwert" ;
VAL_ 795 ESP_HDC_FktLampe 0 "Aus" 1 "Ein" ;
VAL_ 795 ESP_Off_Lampe 0 "Lampe_aus" 1 "Lampe_ein" ;
VAL_ 795 ESP_HDC_Regelgeschw 0 "nicht_verbaut" 125 "HDC_Standby" 126 "Init" 127 "Fehler" ;
VAL_ 795 ESP_BKV_Warnung 0 "keine_Anzeige" 1 "keine_Bremskraftverstaerkung" ;
VAL_ 2589283617 EDS_Charisma_FahrPr 0 "keine_Funktion" 1 "Programm_1" 2 "Programm_2" 3 "Programm_3" 4 "Programm_4" 5 "Programm_5" 6 "Programm_6" 7 "Programm_7" 8 "Programm_8" 9 "Programm_9" 10 "Programm_10" 11 "Programm_11" 12 "Programm_12" 13 "Programm_13" 14 "Programm_14" 15 "Programm_15" ;
VAL_ 2589283617 EDS_Charisma_Status 0 "Init" 1 "verfuegbar" 2 "nicht_verfuegbar" 3 "asynchron_durch_Fahrerwunsch" ;
VAL_ 2589283617 HHC_Charisma_Status 0 "Init" 1 "verfuegbar" 2 "nicht_verfuegbar" 3 "asynchron_durch_Fahrerwunsch" ;
VAL_ 2589283617 HHC_Charisma_FahrPr 0 "keine_Funktion" 1 "Programm_1" 2 "Programm_2" 3 "Programm_3" 4 "Programm_4" 5 "Programm_5" 6 "Programm_6" 7 "Programm_7" 8 "Programm_8" 9 "Programm_9" 10 "Programm_10" 11 "Programm_11" 12 "Programm_12" 13 "Programm_13" 14 "Programm_14" 15 "Programm_15" ;
VAL_ 2589283617 RLE_Anzeigen 0 "keine_Anzeige" 1 "Rad_lose_allgemein" 2 "Rad_VL_lose" 3 "Rad_VR_lose" 4 "Rad_HL_lose" 5 "Rad_HR_lose" 6 "RLE_Pruefphase" ;
VAL_ 427 ESC_AHW_aktiv 0 "keine_Aktivitaet" 1 "Aktivitaet_durch_IPA" 2 "Aktivitaet_durch_ARA" 3 "Aktivitaet_durch_ACC" 4 "tbd" 5 "tbd" 6 "tbd" 7 "tbd" ;
VAL_ 427 ESC_AHW_nicht_verfuegbar 0 "verfuegbar" 1 "nicht_verfuegbar" ;
VAL_ 427 ESC_ANB_CM_aktiv 0 "keine_Aktivitaet" 1 "Aktivitaet_durch_AWV" ;
VAL_ 427 ESC_ANB_CM_nicht_verfuegbar 0 "verfuegbar" 1 "nicht_verfuegbar" ;
VAL_ 427 ESC_Warnruck_aktiv 0 "keine_Aktivitaet" 1 "Aktivitaet_durch_AWV" 2 "Aktivitaet_durch_vFGS" 3 "Aktivitaet_durch_RCTA" 4 "Aktivitaet_durch_FCWO" 5 "Aktivitaet_durch_FCWP" 6 "Aktivitaet_durch_EA" 7 "Aktivitaet_durch_PCF" 8 "Aktivitaet_durch_KAS" 9 "Aktivitaet_durch_AGW" ;
VAL_ 427 ESC_Warnruck_nicht_verfuegbar 0 "verfuegbar" 1 "nicht_verfuegbar" ;
VAL_ 427 ESC_Prefill_aktiv 0 "keine_Aktivitaet" 1 "Prefill_aktiv" ;
VAL_ 427 ESC_Prefill_nicht_verfuegbar 0 "verfuegbar" 1 "nicht_verfuegbar" ;
VAL_ 427 ESC_HBA_aktiv 0 "keine_Aktivitaet" 1 "HBA_aktiv" ;
VAL_ 427 ESC_HBA_nicht_verfuegbar 0 "verfuegbar" 1 "nicht_verfuegbar" ;
VAL_ 427 ESC_TSK_SRBM_Anf 0 "keine_Aktivitaet" 1 "Aktivitaet_durch_TSK" ;
VAL_ 427 ESC_TSK_SRBM_nicht_verfuegbar 0 "verfuegbar" 1 "nicht_verfuegbar" ;
VAL_ 427 ESC_Verz_Reg_aktiv 0 "keine_Aktivitaet" 1 "Aktivitaet_TB_durch_AWV" 2 "Aktivitaet_ZB_durch_AWV" 3 "Aktivitaet_durch_vFGS" 4 "Aktivitaet_durch_TSK" 5 "Aktivitaet_durch_RCTA" 6 "Aktivitaet_durch_PLA_IPA" 7 "Aktivitaet_durch_STA" 8 "Aktivitaet_durch_ARA" 9 "Aktivitaet_durch_MKB" 10 "Aktivitaet_durch_BFF" 11 "Aktivitaet_durch_FAS_VK" 12 "Aktivitaet_durch_PCF" 13 "Aktivitaet_durch_KAS" 14 "Aktivitaet_durch_BRS_intern" 15 "reserviert" ;
VAL_ 427 ESC_Verz_Reg_nicht_verfuegbar 0 "verfuegbar" 1 "nicht_verfuegbar" ;
VAL_ 427 ESC_Verz_Reg_TB_nicht_verfuegbar 0 "verfuegbar" 1 "nicht_verfuegbar" ;
VAL_ 427 ESC_Verz_Reg_ZB_nicht_verfuegbar 0 "verfuegbar" 1 "nicht_verfuegbar" ;
VAL_ 427 ESC_Bremslicht_unplausibel 0 "plausibel" 1 "unplausibel" ;
VAL_ 427 ESC_Konsistenz_ACC 0 "konsistent" 1 "nicht_konsistent" ;
VAL_ 427 ESC_Konsistenz_AWV 0 "konsistent" 1 "nicht_konsistent" ;
VAL_ 427 ESC_Konsistenz_ARA 0 "konsistent" 1 "nicht_konsistent" ;
VAL_ 427 ESC_Konsistenz_IPA 0 "konsistent" 1 "nicht_konsistent" ;
VAL_ 427 ESC_Konsistenz_FCW 0 "konsistent" 1 "nicht_konsistent" ;
VAL_ 427 ESC_Konsistenz_NV 0 "konsistent" 1 "nicht_konsistent" ;
VAL_ 427 ESC_Konsistenz_RCTA 0 "konsistent" 1 "nicht_konsistent" ;
VAL_ 427 ESC_Konsistenz_TSK 0 "konsistent" 1 "nicht_konsistent" ;
VAL_ 427 ESC_Konsistenz_vFGS 0 "konsistent" 1 "nicht_konsistent" ;
VAL_ 427 ESC_Konsistenz_STA 0 "konsistent" 1 "nicht_konsistent" ;
VAL_ 427 ESC_Fahrer_Bremsdruck_bestimmend 0 "Fahrer_nicht_Bremsdruck_bestimmend" 1 "Fahrer_Bremsdruck_bestimmend" ;
VAL_ 427 ESC_Konsistenz_EA 0 "konsistent" 1 "nicht_konsistent" ;
VAL_ 427 ESC_Konsistenz_BFF 0 "konsistent" 1 "nicht_konsistent" ;
VAL_ 427 ESC_Konsistenz_MKB 0 "konsistent" 1 "nicht_konsistent" ;
VAL_ 427 ESC_Verz_ASIL_Verfuegbarkeit 0 "Nicht_verfuegbar" 1 "Verfuegbar_ab_ASIL_QM" 2 "Verfuegbar_ab_ASIL_A" 3 "Verfuegbar_ab_ASIL_B" 4 "Verfuegbar_ab_ASIL_C" 5 "reserved" 6 "reserved" 7 "reserved" ;
VAL_ 427 ESC_Pumpenanlauf_aktiv 0 "inaktiv" 1 "aktiv" ;
VAL_ 427 ESC_Konsistenz_AGW 0 "konsistent" 1 "nicht_konsistent" ;
VAL_ 427 ESC_Konsistenz_KAS 0 "konsistent" 1 "nicht_konsistent" ;
VAL_ 427 ESC_Konsistenz_PCF 0 "konsistent" 1 "nicht_konsistent" ;
VAL_ 427 ESC_Konsistenz_FAS_VK 0 "konsistent" 1 "nicht_konsistent" ;
VAL_ 427 ESC_Verz_Begrenzung 0 "keine_Begrenzung" 1 "Begrenzung_aktiv" ;
VAL_ 427 ESC_Konsistenz_AWA 0 "konsistent" 1 "nicht_konsistent" ;
VAL_ 87 BR_mi_Raddrehz 65533 "Unterspannung" 65534 "Init" 65535 "Fehler" ;
VAL_ 382 ESP_38_Sendestatus 0 "ESP_38_wird_mit_100ms_gesendet" 1 "ESP_38_wird_mit_10ms_gesendet" ;
VAL_ 382 ESC_soll_Druck_EBKV_Freigabe 0 "keine_Freigabe" 1 "Freigabe" ;
VAL_ 382 ESC_soll_Druck_EBKV 1023 "Fehler" ;
VAL_ 264 FA_Hoehenwerte_kalibriert 0 "kalibrierte Höhenwerte in mm" 1 "Rohwerte" ;
VAL_ 264 FA_ESP_Zuschaltung 0 "keine_ESP_Beeinflussung" 1 "ESP_Zwangszuschaltung_angefordert" ;
VAL_ 264 FA_Hoehenwert_VL_00 254 "nicht initialisiert" 255 "Fehler" ;
VAL_ 264 FA_Hoehenwert_VL_01 254 "nicht initialisiert" 255 "Fehler" ;
VAL_ 264 FA_Hoehenwert_VR_00 254 "nicht initialisiert" 255 "Fehler" ;
VAL_ 264 FA_Hoehenwert_VR_01 254 "nicht initialisiert" 255 "Fehler" ;
VAL_ 264 FA_Hoehenwert_HL_00 254 "nicht initialisiert" 255 "Fehler" ;
VAL_ 264 FA_Hoehenwert_HL_01 254 "nicht initialisiert" 255 "Fehler" ;
VAL_ 264 FA_Hoehenwert_HR_00 254 "nicht initialisiert" 255 "Fehler" ;
VAL_ 264 FA_Hoehenwert_HR_01 254 "nicht initialisiert" 255 "Fehler" ;
VAL_ 314 FCWO_Ruck_Freigabe 0 "keine_Freigabe" 1 "Freigabe" ;
VAL_ 314 FCWO_Ruckprofil 0 "kein_Ruckprofil" 1 "Ruckprofil_1" 2 "Ruckprofil_2" 3 "Ruckprofil_3" 4 "Ruckprofil_4" 5 "Ruckprofil_5" 6 "Ruckprofil_6" 7 "Ruckprofil_7" ;
VAL_ 314 FCWO_Anf_Prefill 0 "Prefill_nicht_aktivieren" 1 "Prefill_aktivieren" ;
VAL_ 314 FCWO_HBA_Param 0 "Defaultparametersatz" 1 "leicht_erh_Empfindlichkeit" 2 "erhoehte_Empfindlichkeit" 3 "hoechste_Empfindlichkeit" ;
VAL_ 314 FCWP_Anf_Prefill 0 "Prefill_nicht_aktivieren" 1 "Prefill_aktivieren" ;
VAL_ 314 FCWP_HBA_Param 0 "Defaultparametersatz" 1 "leicht_erh_Empfindlichkeit" 2 "erhoehte_Empfindlichkeit" 3 "hoechste_Empfindlichkeit" ;
VAL_ 314 FCWP_Ruck_Freigabe 0 "keine_Freigabe" 1 "Freigabe" ;
VAL_ 314 FCWP_Ruckprofil 0 "kein_Ruckprofil" 1 "Ruckprofil_1" 2 "Ruckprofil_2" 3 "Ruckprofil_3" 4 "Ruckprofil_4" 5 "Ruckprofil_5" 6 "Ruckprofil_6" 7 "Ruckprofil_7" ;
VAL_ 987 BCM_01_alt 0 "aktuell" 1 "veraltet" ;
VAL_ 987 SMLS_01_alt 0 "aktuell" 1 "veraltet" ;
VAL_ 987 ZV_02_alt 0 "aktuell" 1 "veraltet" ;
VAL_ 987 Wischer_01_alt 0 "aktuell" 1 "veraltet" ;
VAL_ 987 Anhaenger_01_alt 0 "aktuell" 1 "veraltet" ;
VAL_ 987 Klima_Sensor_02_alt 0 "aktuell" 1 "veraltet" ;
VAL_ 987 Verdeck_01_alt 0 "aktuell" 1 "veraltet" ;
VAL_ 987 Klima_11_alt 0 "aktuell" 1 "veraltet" ;
VAL_ 987 WFS_01_alt 0 "aktuell" 1 "veraltet" ;
VAL_ 987 Licht_Anf_01_alt 0 "aktuell" 1 "veraltet" ;
VAL_ 987 ZV_verriegelt_extern_soll 1 "Fahrzeug verriegelt extern; Sollzusstand" ;
VAL_ 987 BH_Lichthupe 0 "nicht_betaetigt" 1 "Blinkerhebel in Richtung Lichthupe betaetigt" ;
VAL_ 987 WFS_Klemmenfreigabe 0 "keine_Freigabe" 1 "Freigabe" ;
VAL_ 987 ZV_Tankklappe_offen 0 "Tankklappe_geschlossen" 1 "Tankklappe_offen" ;
VAL_ 987 AAG_Anhaenger_abgesteckt 1 "Anhaenger_wurde_bei_KL15_aus_abgesteckt" ;
VAL_ 987 BCM1_LDS_Stellung 0 "Init" 1 "Stellung_0" 2 "Auto" 3 "Standlicht" 4 "Abblendlicht" 7 "Fehler" ;
VAL_ 987 VS_VD_entriegelt 1 "Zustand des Verdeck entriegelt" ;
VAL_ 987 ZV_HFS_offen 0 "geschlossen" 1 "offen" ;
VAL_ 987 ZV_HBFS_offen 0 "geschlossen" 1 "offen" ;
VAL_ 987 VS_VD_offen_ver 0 "Init" 1 "Zustand des Verdecks verriegelt und offen" ;
VAL_ 987 VS_VD_zu_ver 1 "Zustand des Verdecks verriegelt und geschlossen" ;
VAL_ 987 ZV_BT_offen 1 "BT_geoeffnet" ;
VAL_ 987 BCM1_Rueckfahrlicht_Schalter 0 "nicht_betaetigt" 1 "betaetigt" ;
VAL_ 987 ZV_FT_offen 1 "FT_geoeffnet" ;
VAL_ 987 Wischer_vorne_aktiv 1 "Wischer vorne läuft" ;
VAL_ 987 AAG_Anhaenger_erkannt 0 "kein_Anhaenger_erkannt" 1 "AAG_Anhaenger_erkannt" ;
VAL_ 987 BCM1_MH_Schalter 0 "MH_geschlossen" 1 "MH_offen" ;
VAL_ 987 ZV_HD_offen 1 "Heckdeckel_auf" ;
VAL_ 987 Waschen_vorne_aktiv 1 "Waschen aktiv" ;
VAL_ 987 KL_Thermomanagement 0 "keine_Freigabe_TMM__max_Heizbedarf" 1 "kleine_Freigabe_TMM" 2 "mittlere_Freigabe_TMM" 3 "volle_Freigabe_TMM__kein_Heizbedarf" ;
VAL_ 987 WFS_Schluessel_Fahrberecht 0 "kein authorisierter Schluessel erkannt " 1 "aktive_Funkschluessel_Nr_01" 2 "aktive_Funkschluessel_Nr_02" 3 "aktive_Funkschluessel_Nr_03" 4 "aktive_Funkschluessel_Nr_04" 5 "aktive_Funkschluessel_Nr_05" 6 "aktive_Funkschluessel_Nr_06" 7 "aktive_Funkschluessel_Nr_07" 8 "aktive_Funkschluessel_Nr_08" 9 "ungueltig_09" 10 "ungueltig_10" 11 "ungueltig_11" 12 "ungueltig_12" 13 "ungueltig_13" 14 "ungueltig_14" 15 "ungueltig_15" ;
VAL_ 987 BCM_Rueckfahrlicht_Anf 0 "Licht_nicht_angefordert" 1 "Licht_angefordert" ;
VAL_ 987 WWSs_01_alt 0 "aktuell" 1 "veraltet" ;
VAL_ 987 BCM_Tankklappensteller_Fehler 0 "kein_Fehler" 1 "Fehler" ;
VAL_ 987 AAG_LED_aktiv 0 "Lampen" 1 "LED" ;
VAL_ 987 ZV_verriegelt_soll 0 "Init" 1 "nicht_verriegelt" 2 "verriegelt" ;
VAL_ 987 ZV_Schluessel_Zugang 0 "kein authorisierter Schluessel erkannt " 1 "aktive_Funkschluessel_Nr_01" 2 "aktive_Funkschluessel_Nr_02" 3 "aktive_Funkschluessel_Nr_03" 4 "aktive_Funkschluessel_Nr_04" 5 "aktive_Funkschluessel_Nr_05" 6 "aktive_Funkschluessel_Nr_06" 7 "aktive_Funkschluessel_Nr_07" 8 "aktive_Funkschluessel_Nr_08" 9 "ungueltig_09" 10 "ungueltig_10" 11 "ungueltig_11" 12 "ungueltig_12" 13 "ungueltig_13" 14 "ungueltig_14" 15 "ungueltig_15" ;
VAL_ 987 WFS_ID_Geb_autorisiert_in_Kl15 0 "nicht_authorisiert_in_Kl15" 1 "authorisiert_in_Kl15" ;
VAL_ 987 BH_Fernlicht 0 "nicht_betaetigt" 1 "Blinkerhebel_in_Richtung_Fernlicht_betaetigt" ;
VAL_ 987 BH_Blinker_li 0 "nicht_betaetigt" 1 "Blinkerhebel_Richtung_links_betaetigt" ;
VAL_ 987 BH_Blinker_re 0 "nicht_betaetigt" 1 "Blinkerhebel_Richtung_rechts_betaetigt" ;
VAL_ 987 BCM1_OBD_FStatus_ATemp 0 "kein Fehler / Init / nicht verbaut" 1 "KS- (Kurzschluss nach minus)" 2 "KS+ (Kurzschluss nach plus)" 3 "OC (Leitungsunterbrechung)" 4 "OOR+ (Signal zu gross)" 5 "OOR- (Signal zu klein)" 6 "RC+ (Signal unplausibel zu gross)" 7 "RC- (Signal unplausibel zu klein)" 8 "KS+/OC (Kurzschluss nach plus/Unterbrechung)" 9 "KS-/OC  (Kurzschluss nach minus/Unterbrechung)" 10 "KS-/KS+  (Kurzschluss nach minus/plus)" 11 "KS-/KS+/OC (Kurzschluss nach minus/plus/Unterbrechung)" 12 "frei" 13 "frei" 14 "frei" 15 "frei" ;
VAL_ 987 BCM1_Aussen_Temp_ungef 253 "nicht_verbaut" 254 "Initwert" 255 "Fehler" ;
VAL_ 1004 HDSG_01_alt 0 "aktuell" 1 "veraltet" ;
VAL_ 1004 ACC_02_alt 0 "aktuell" 1 "veraltet" ;
VAL_ 1004 Klima_11_alt 0 "aktuell" 1 "veraltet" ;
VAL_ 1004 Motor_17_alt 0 "aktuell" 1 "veraltet" ;
VAL_ 1004 LDW_02_alt 0 "aktuell" 1 "veraltet" ;
VAL_ 1004 MO_NGS_Position 0 "Neutralposition_nicht_erkannt" 1 "Neutralposition_erkannt" ;
VAL_ 1004 MO_NGS_Status 0 "nicht_verbaut" 1 "nicht_plausibilisiert" 2 "plausibilisiert" 3 "Fehler" ;
VAL_ 1004 HC_Uss_Anforderung 0 "Ultraschallsensoren Aus" 1 "Ultraschallsensoren An" ;
VAL_ 1004 KL_Vorwarn_Komp_ein 0 "Init" 1 "Vorwarnung_Kompressor_ein" ;
VAL_ 1004 HD_Endstellung_oben 1 "HD in Endstellung oben (offen)" ;
VAL_ 1004 HD_Endstellung_unten 1 "HD in Endstellung unten (geschlossen)" ;
VAL_ 1004 ACC_Status_Anzeige 0 "ACC_GRA_Hauptschalter_aus" 1 "ACC_in_Init_nicht_bei_GRA" 2 "ACC_GRA_passiv" 3 "ACC_GRA_aktiv" 4 "ACC_GRA_im_Hintergrund_uebertreten" 5 "ACC_GRA_Abschaltreaktion" 6 "ACC_reversibel_aus_nicht_bei_GRA" 7 "ACC_GRA_irreversibel_aus" ;
VAL_ 173 GE_MMom_Soll_02 1022 "keine_Anforderung_Init" 1023 "Fehler" ;
VAL_ 173 GE_MMom_Vorhalt_02 1022 "Init" 1023 "Fehler" ;
VAL_ 173 GE_Uefkt 1023 "Fehler" ;
VAL_ 173 GE_Fahrstufe 0 "Zwischenstellung" 1 "Init" 5 "Position_P" 6 "Position_R" 7 "Position_N" 8 "Position_D" 9 "Position_S" 10 "Effizienz" 13 "Tipp_in_S" 14 "Tipp_in_D" 15 "Fehler" ;
VAL_ 173 GE_Schaltablauf 0 "keine_Schaltung" 1 "Momentenueberschneidung" 2 "Befuellphase" 3 "Drehzahlueberfuehrung" ;
VAL_ 173 GE_Uefkt_unplausibel 0 "Uefkt_plausibel" 1 "Uefkt_unplausibel" ;
VAL_ 173 GE_MMom_Status_02 0 "kein_Eingriff" 1 "abs_reduzierender_Eingriff_auf_Gesamt_Antrieb_nur_schneller_Pfad" 2 "abs_erhoehender_Eingriff_auf_Gesamt_Antrieb" 3 "relativer_Eingriff_auf_Gesamt_Antrieb" 4 "relativer_Eingriff_auf_E_Maschine" 5 "abs_red_Eingr_auf_Gesamt_Antrieb_nur_Luftpfad" 6 "abs_red_Eingr_auf_Gesamt_Antrieb_Luft-_und_schnellen_Pfad" 7 "abs_Eingriff_auf_Gesamtantrieb_erhoehend_und_reduzierend" ;
VAL_ 173 GE_Status_Kraftschluss 0 "offen_kein_Kraftschluss" 1 "offen_mit_Kraftschluss" 2 "schlupfend_geregelt" 4 "geschlossen_mit_Mikroschlupf" 5 "geschlossen_mit_Ueberanpressung" 6 "sonstige_Fehler" 7 "fehlerhaft_geschlossen" ;
VAL_ 173 GE_MMom_Status 0 "keine Anforderung" 1 "reduzierender Getriebeeingriff" 2 "erhöhender Getriebeeingriff" 3 "Änderung mit Sprung" ;
VAL_ 173 GE_Freig_MMom_Vorhalt 0 "nicht_freigegeben" 1 "freigegeben" ;
VAL_ 173 GE_Verbot_Ausblendung 0 "kein_Verbot" 1 "Verbot" ;
VAL_ 173 GE_Zielgang 0 "Gang P/N (ausgekuppelt)" 1 "Gang 1" 2 "Gang 2" 3 "Gang 3" 4 "Gang 4" 5 "Gang 5" 6 "Gang 6" 7 "Gang 7" 8 "Gang R" 11 "Gang 8" 12 "Gang 9" 13 "Gang10" 14 "Istgang nicht definiert" 15 "Fehler" ;
VAL_ 968 GE_OBD_AbsperrVent 0 "kein Fehler / Init / nicht verbaut" 1 "KS- (Kurzschluss nach minus)" 2 "KS+ (Kurzschluss nach plus)" 3 "OC (Leitungsunterbrechung)" 4 "OOR+ (Signal zu gross)" 5 "OOR- (Signal zu klein)" 6 "RC+ (Signal unplausibel zu gross)" 7 "RC- (Signal unplausibel zu klein)" 8 "KS+/OC (Kurzschluss nach plus/Unterbrechung)" 9 "KS-/OC  (Kurzschluss nach minus/Unterbrechung)" 10 "KS-/KS+  (Kurzschluss nach minus/plus)" 11 "KS-/KS+/OC (Kurzschluss nach minus/plus/Unterbrechung)" 12 "Position_unbekannt" 13 "Failsafe_Position" 14 "Referenzfahrt_aktiv" 15 "frei" ;
VAL_ 968 GE_amax_moeglich 511 "nicht_definiert" ;
VAL_ 968 GE_Charisma_FahrPr 0 "keine_Funktion" 1 "Programm_1" 2 "Programm_2" 3 "Programm_3" 4 "Programm_4" 5 "Programm_5" 6 "Programm_6" 7 "Programm_7" 8 "Programm_8" 9 "Programm_9" 10 "Programm_10" 11 "Programm_11" 12 "Programm_12" 13 "Programm_13" 14 "Programm_14" 15 "Programm_15" ;
VAL_ 968 GE_Charisma_Status 0 "Init" 1 "verfuegbar" 2 "nicht_verfuegbar" 3 "asynchron_durch_Fahrerwunsch" ;
VAL_ 968 GE_Freigabe_Verfallsinfo_WFS 0 "Aus" 1 "Ein" ;
VAL_ 968 GE_Verlustmoment 255 "Fehler" ;
VAL_ 968 Freilauf_Charisma_FahrPr 0 "keine_Funktion" 1 "Programm_1" 2 "Programm_2" 3 "Programm_3" 4 "Programm_4" 5 "Programm_5" 6 "Programm_6" 7 "Programm_7" 8 "Programm_8" 9 "Programm_9" 10 "Programm_10" 11 "Programm_11" 12 "Programm_12" 13 "Programm_13" 14 "Programm_14" 15 "Programm_15" ;
VAL_ 968 Freilauf_Charisma_Status 0 "Init" 1 "verfuegbar" 2 "nicht_verfuegbar" 3 "asynchron_durch_Fahrerwunsch" ;
VAL_ 968 GE_Freigabe_Info_WFS 0 "ungueltig" 1 "gueltig" ;
VAL_ 968 GE_Sperr_Info_WFS 0 "nicht_gesperrt" 1 "gesperrt" ;
VAL_ 968 GE_Zustand_Kuppltemp 0 "Init" 1 "Kupplungstemp_normal" 2 "Kupplungstemp_hoch" 3 "Kupplungsschutz_aktivieren" ;
VAL_ 968 GE_Codierung_MSG 0 "Codierung iO / Init" 1 "Codierung niO" ;
VAL_ 968 GE_LaunchControl 0 "inaktiv" 1 "aktiv" ;
VAL_ 968 GE_Heizwunsch 0 "maximaler_Waermebedarf" 1 "kein_Waermebedarf" 2 "Kuehlbedarf" 3 "Notfall_(maximaler_Kuehlbedarf)" ;
VAL_ 968 GE_OBD_Status 0 "MIL aus" 1 "MIL ein" ;
VAL_ 968 GE_LFR_Adaption 0 "fuer_Adaption_geeignet" 1 "fuer_Adaption_nicht_geeignet" ;
VAL_ 968 GE_Sumpftemperatur 255 "Fehler" ;
VAL_ 294 EA_ACC_Sollstatus 0 "Init" 1 "ACC_aktivieren" 2 "ACC_deaktivieren" ;
VAL_ 294 EA_Ruckprofil 0 "Init" 1 "Profil_1" 2 "Profil_2" 3 "Profil_3" 4 "Profil_4" 5 "Profil_5" 6 "Profil_6" 7 "Profil_7" ;
VAL_ 294 HCA_01_Sendestatus 0 "HCA_sendet_mit_1000ms" 1 "HCA_sendet_mit_20ms" ;
VAL_ 294 HCA_01_LM_OffSign 0 "positives_Vorzeichen" 1 "negatives_Vorzeichen" ;
VAL_ 294 HCA_01_Status_HCA 0 "deaktiviert" 1 "reserviert" 2 "reserviert" 3 "funktionsbereit" 4 "reserviert" 5 "HCA_Momenteneingriff_1" 6 "MA_Aktiv" 7 "HCA_Momenteneingriff_2" 8 "reserviert" 9 "reserviert" 10 "reserviert" 11 "reserviert" 12 "reserviert" 13 "reserviert" 14 "reserviert" 15 "reserviert" ;
VAL_ 294 EA_Ruckfreigabe 0 "keine_Freigabe" 1 "Freigabe" ;
VAL_ 294 EA_ACC_Wunschgeschwindigkeit 1023 "Init" ;
VAL_ 1412 HSP_Warnung_Ton 0 "Aus" 1 "Ein" ;
VAL_ 1412 HSP_Warnung_Text 0 "Aus" 1 "Ein" ;
VAL_ 1412 HSP_Endlage_eingefahren 0 "Endlage nicht erreicht" 1 "Endlage erreicht" ;
VAL_ 1412 HSP_Endlage_ausgefahren 0 "Endlage nicht erreicht" 1 "Endlage erreicht" ;
VAL_ 1412 HSP_Motor_def 0 "normal" 1 "Fehler" ;
VAL_ 1412 HSP_Taster_Error 0 "Taster_iO" 1 "Fehler__haengender_Taster" ;
VAL_ 1412 HSP_Charisma_FahrPr 0 "keine_Funktion" 1 "Programm_1" 2 "Programm_2" 3 "Programm_3" 4 "Programm_4" 5 "Programm_5" 6 "Programm_6" 7 "Programm_7" 8 "Programm_8" 9 "Programm_9" 10 "Programm_10" 11 "Programm_11" 12 "Programm_12" 13 "Programm_13" 14 "Programm_14" 15 "Programm_15" ;
VAL_ 1412 HSP_Charisma_Status 0 "Init" 1 "verfuegbar" 2 "nicht_verfuegbar" 3 "asynchron_durch_Fahrerwunsch" ;
VAL_ 960 RSt_Fahrerhinweise 0 "Init" 1 "Fahreruebernahme_Hinweis_ZAT_Automat_ohne_Gong" 2 "Fahreruebernahme_Hinweis_ZAT_Automat_mit_Gong" 3 "Fahreruebernahme_Hinweis_ZAT_Handschalter_ohne_Gong" 4 "Fahreruebernahme_Hinweis_ZAT_Handschalter_mit_Gong" 5 "Fahreruebernahme_Hinweis_ZAS_Automat_ohne_Gong" 6 "Fahreruebernahme_Hinweis_ZAS_Automat_mit_Gong" 7 "Fahreruebernahme_Hinweis_ZAS_Handschalter_ohne_Gong" 8 "Fahreruebernahme_Hinweis_ZAS_Handschalter_mit_Gong" 9 "RemoteStart_aktiv_ohne_Gong" 10 "RemoteStart_aktiv_mit_Gong" 11 "void" 12 "void" 13 "void" 14 "void" 15 "void" ;
VAL_ 960 ZAS_Kl_S 0 "aus" 1 "S_Kontakt_ein" ;
VAL_ 960 ZAS_Kl_15 0 "aus" 1 "ein" ;
VAL_ 960 ZAS_Kl_X 0 "aus" 1 "ein" ;
VAL_ 960 ZAS_Kl_50_Startanforderung 0 "aus" 1 "KL50_ein_Startwunsch_Fahrer" ;
VAL_ 960 BCM_Remotestart_Betrieb 0 "kein_RS_Betrieb" 1 "RS_Betrieb" ;
VAL_ 960 ZAS_Kl_Infotainment 0 "inaktiv" 1 "aktiv" ;
VAL_ 960 BCM_Remotestart_KL15_Anf 0 "inaktiv" 1 "aktiv" ;
VAL_ 960 BCM_Remotestart_MO_Start 0 "nicht_angefordert" 1 "angefordert" ;
VAL_ 960 KST_Warn_P1_ZST_def 0 "nicht_defekt" 1 "defekt" ;
VAL_ 960 KST_Warn_P2_ZST_def 0 "nicht_defekt" 1 "defekt" ;
VAL_ 960 KST_Fahrerhinweis_1 0 "inaktiv" 1 "aktiv" ;
VAL_ 960 KST_Fahrerhinweis_2 0 "inaktiv" 1 "aktiv" ;
VAL_ 960 BCM_Ausparken_Betrieb 0 "kein_Betrieb" 1 "Ausparkvorgang_aktiv" ;
VAL_ 960 KST_Fahrerhinweis_4 0 "inaktiv" 1 "aktiv" ;
VAL_ 960 KST_Fahrerhinweis_5 0 "inaktiv" 1 "aktiv" ;
VAL_ 960 KST_Fahrerhinweis_6 0 "inaktiv" 1 "aktiv" ;
VAL_ 1640 KL_LRH_Taster 0 "nicht_betaetigt" 1 "betaetigt" ;
VAL_ 1640 KL_LRH_Stufe 0 "Stufe_niedrig" 1 "Stufe_mittel" 2 "Stufe_hoch" ;
VAL_ 1640 HSH_Taster 0 "nicht_betaetigt" 1 "short_push" 2 "long_push" 3 "tbd" ;
VAL_ 1640 FSH_Taster 0 "nicht_betaetigt" 1 "betaetigt" ;
VAL_ 1640 KL_Zuheizer_Freigabe 0 "keine_Freigabe_Zuheizer" 1 "Zuheizerfreigabe" ;
VAL_ 1640 KL_Beschlagsgefahr 0 "keine_Beschlagsgefahr" 1 "Beschlagsgefahr" ;
VAL_ 1640 KRH_Soll_li 0 "aus" 1 "Stufe_1" 2 "Stufe_2" 3 "Stufe_3" ;
VAL_ 1640 KRH_Soll_re 0 "aus" 1 "Stufe_1" 2 "Stufe_2" 3 "Stufe_3" ;
VAL_ 1640 KL_Geblspng_Soll 0 "0V_Motorspannung" 252 "0V_sofort_Abschalten" 253 "0V_senken_mit_Rampe" 254 "reserviert" 255 "Fehler" ;
VAL_ 1640 KL_Geblspng_Fond_Soll 0 "0V_Motorspannung" 252 "0V_sofort_Abschalten" 253 "0V_senken_mit_Rampe" 254 "reserviert" 255 "Fehler" ;
VAL_ 1640 KL_I_Geblaese 255 "Fehler" ;
VAL_ 1640 KL_Kompressorstrom_soll 1022 "Init" 1023 "Fehler" ;
VAL_ 1640 KL_Umluftklappe_Status 0 "Frischluft" 1 "Teilumluft_10" 2 "Teilumluft_20" 3 "Teilumluft_30" 4 "Teilumluft_40" 5 "Teilumluft_50" 6 "Teilumluft_60" 7 "Teilumluft_70" 8 "Teilumluft_80" 9 "Teilumluft_90" 10 "Umluft" 14 "Init" 15 "Fehler" ;
VAL_ 1640 KL_PTC_Verbauinfo 0 "kein_PTC" 1 "600W_geschaltet" 2 "1000W_geschaltet" 3 "1400W_LIN" ;
VAL_ 2549088275 ESP_KompSchutz 0 "inaktiv" 1 "aktiv" ;
VAL_ 2549088275 ABS_Abschaltstufe 0 "keine_Einschraenkung" 1 "Funktionseinschraenkung" ;
VAL_ 2549088275 ABS_Transport_Mode 0 "keine_Einschraenkung" 1 "Funktionseinschraenkung" ;
VAL_ 2549088275 ESP_Nachlauftyp 0 "Komm_bei_KL15_EIN" 1 "Komm_nach_KL15_AUS" 2 "Komm_bei_KL15_AUS" ;
VAL_ 2549088275 ABS_SNI 19 "ABS" ;
VAL_ 2549088275 KN_ESP_BusKnockOutTimer 255 "BusKnockOut_deaktiviert" ;
VAL_ 2549088275 ESP_KD_Fehler 0 "kein_KD_Fehler" 1 "KD_Fehler" ;
VAL_ 2549088271 Allrad_KompSchutz 0 "inaktiv" 1 "aktiv" ;
VAL_ 2549088271 Allrad_Abschaltstufe 0 "keine_Einschraenkung" 1 "Funktionseinschraenkung" ;
VAL_ 2549088271 Allrad_Transport_Mode 0 "keine_Einschraenkung" 1 "Funktionseinschraenkung" ;
VAL_ 2549088271 Allrad_Nachlauftyp 0 "Komm_bei_KL15_EIN" 1 "Komm_nach_KL15_AUS" 2 "Komm_bei_KL15_AUS" ;
VAL_ 2549088271 Allrad_SNI 15 "Allrad" ;
VAL_ 2549088271 ALR_KD_Fehler 0 "kein_KD_Fehler" 1 "KD_Fehler" ;
VAL_ 2549088370 Daempfer_KompSchutz 0 "inaktiv" 1 "aktiv" ;
VAL_ 2549088370 Daempfer_Abschaltstufe 0 "keine_Einschraenkung" 1 "Funktionseinschraenkung" ;
VAL_ 2549088370 Daempfer_Transport_Mode 0 "keine_Einschraenkung" 1 "Funktionseinschraenkung" ;
VAL_ 2549088370 Daempfer_Nachlauftyp 0 "Komm_bei_KL15_EIN" 1 "Komm_nach_KL15_AUS" 2 "Komm_bei_KL15_AUS" ;
VAL_ 2549088370 Daempfer_SNI 114 "Daempfer" ;
VAL_ 2549088370 DR_KD_Fehler 0 "kein_KD_Fehler" 1 "KD_Fehler" ;
VAL_ 2549088266 EPH_KompSchutz 0 "inaktiv" 1 "aktiv" ;
VAL_ 2549088266 EPH_Abschaltstufe 0 "keine_Einschraenkung" 1 "Funktionseinschraenkung" ;
VAL_ 2549088266 EPH_Transport_Mode 0 "keine_Einschraenkung" 1 "Funktionseinschraenkung" ;
VAL_ 2549088266 EPH_Nachlauftyp 0 "Komm_bei_KL15_EIN" 1 "Komm_nach_KL15_AUS" 2 "Komm_bei_KL15_AUS" ;
VAL_ 2549088266 EPH_SNI 10 "EPH" ;
VAL_ 2549088266 PH_KD_Fehler 0 "kein_KD_Fehler" 1 "KD_Fehler" ;
VAL_ 2549088274 Lenkhilfe_KompSchutz 0 "inaktiv" 1 "aktiv" ;
VAL_ 2549088274 Lenkhilfe_Abschaltstufe 0 "keine_Einschraenkung" 1 "Funktionseinschraenkung" ;
VAL_ 2549088274 Lenkhilfe_Transport_Mode 0 "keine_Einschraenkung" 1 "Funktionseinschraenkung" ;
VAL_ 2549088274 Lenkhilfe_Nachlauftyp 0 "Komm_bei_KL15_EIN" 1 "Komm_nach_KL15_AUS" 2 "Komm_bei_KL15_AUS" ;
VAL_ 2549088274 Lenkhilfe_SNI 18 "Lenkhilfe" ;
VAL_ 2549088274 EPS_KD_Fehler 0 "kein_KD_Fehler" 1 "KD_Fehler" ;
VAL_ 2549088361 Rearview_KompSchutz 0 "inaktiv" 1 "aktiv" ;
VAL_ 2549088361 Rearview_Abschaltstufe 0 "keine_Einschraenkung" 1 "Funktionseinschraenkung" ;
VAL_ 2549088361 Rearview_Transport_Mode 0 "keine_Einschraenkung" 1 "Funktionseinschraenkung" ;
VAL_ 2549088361 Rearview_Nachlauftyp 0 "Komm_bei_KL15_EIN" 1 "Komm_nach_KL15_AUS" 2 "Komm_bei_KL15_AUS" ;
VAL_ 2549088361 Rearview_SNI 105 "Rearview" ;
VAL_ 2549088361 KN_Rearview_BusKnockOutTimer 255 "BusKnockOut_deaktiviert" ;
VAL_ 2549088361 RV_KD_Fehler 0 "kein_KD_Fehler" 1 "KD_Fehler" ;
